VERSION "created by canmatrix"

NS_ :

BS_:

BU_: MD1_ECM ETC NODE_5 BSM_EBS RM_IRCS IC_Multic SGW BCM_NBM VCM NODE_31 ETS NODE_45 FCCU DICO NODE_72 FMReceiver SGW2 VCU ADCU MRGEN DTCO MBMS TPMS AI_CAID ELC ELC_R NODE_F7 BMS3 TUROLLA PCM SRR_Front_Left SRR_Rear_Right SRR_Front_Right SRR_Front SRR_Rear_Left ELFA3_S THERMOKING_M TMU_HP_Rr NODE_B1 NODE_B2 NODE_B3 NODE_B4 NODE_B5 NODE_B6 NODE_B7 NODE_B8 BMS2 NODE_B9 NODE_BA NODE_FC NODE_BB NODE_BC NODE_BE NODE_BD NODE_BF ACU NODE_C0 BMS1 NODE_C1 FCU NODE_C3 NODE_C4 NODE_EC NODE_C5 NODE_C6 NODE_C7 NODE_C8 VCU2 NODE_CA NODE_CB NODE_CD NODE_CE NODE_CF NODE_ED ST_ScanTool MASTER68_STD1 NODE_D1 NODE_F2 NODE_FD NODE_D2 MCSL NODE_EB NODE_D3 NODE_D4 NODE_D5 NODE_D6 VCCU NODE_D8 NODE_D9 NODE_F9 DiagTool NODE_DA NODE_DB NODE_DC NODE_DD NODE_DE NODE_DF NODE_E0 NODE_E1 NODE_E2 NODE_E9 NODE_E3 SAS NODE_FB NODE_F8 NODE_E6 ELFA3 NODE_F THERMOKING_D FMS MULTIC_S MULTIC_2 BMS4 BMS5 BMS6 BMS7 BMS8 BMS9 BMS10 BMS11 NODE_71

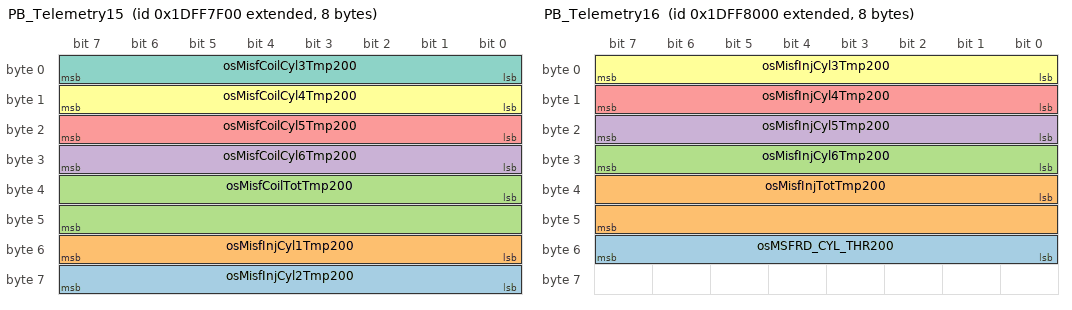
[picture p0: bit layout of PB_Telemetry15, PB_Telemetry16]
BO_ 2650767104 PB_Telemetry15: 8 MD1_ECM
 SG_ osMisfInjCyl2Tmp200 : 56|8@1+ (1,0) [0|255] "adm"  PCM
 SG_ osMisfInjCyl1Tmp200 : 48|8@1+ (1,0) [0|255] "adm"  PCM
 SG_ osMisfCoilTotTmp200 : 32|16@1+ (1,0) [0|65535] "adm"  PCM
 SG_ osMisfCoilCyl6Tmp200 : 24|8@1+ (1,0) [0|255] "adm"  PCM
 SG_ osMisfCoilCyl5Tmp200 : 16|8@1+ (1,0) [0|255] "adm"  PCM
 SG_ osMisfCoilCyl4Tmp200 : 8|8@1+ (1,0) [0|255] "adm"  PCM
 SG_ osMisfCoilCyl3Tmp200 : 0|8@1+ (1,0) [0|255] "adm"  PCM

BO_ 2650767360 PB_Telemetry16: 8 MD1_ECM
 SG_ osMSFRD_CYL_THR200 : 48|8@1+ (1,0) [0|100] "adm"  PCM
 SG_ osMisfInjTotTmp200 : 32|16@1+ (1,0) [0|65535] "adm"  PCM
 SG_ osMisfInjCyl6Tmp200 : 24|8@1+ (1,0) [0|255] "adm"  PCM
 SG_ osMisfInjCyl5Tmp200 : 16|8@1+ (1,0) [0|255] "adm"  PCM
 SG_ osMisfInjCyl4Tmp200 : 8|8@1+ (1,0) [0|255] "adm"  PCM
 SG_ osMisfInjCyl3Tmp200 : 0|8@1+ (1,0) [0|255] "adm"  PCM

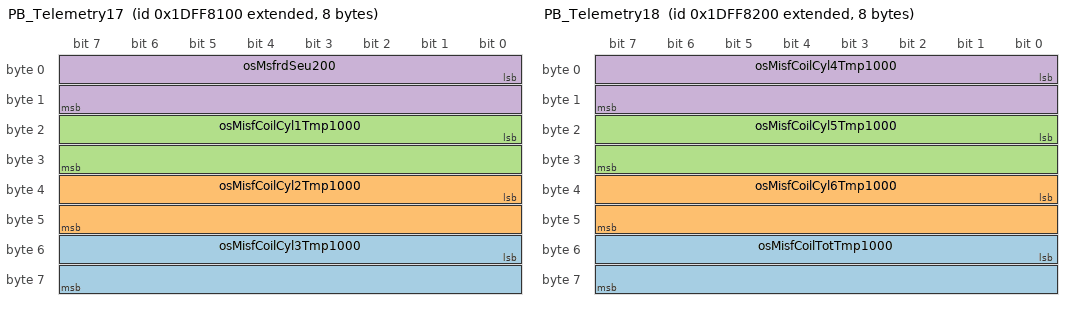
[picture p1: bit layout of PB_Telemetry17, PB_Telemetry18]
BO_ 2650767616 PB_Telemetry17: 8 MD1_ECM
 SG_ osMisfCoilCyl3Tmp1000 : 48|16@1+ (1,0) [0|65535] "adm"  PCM
 SG_ osMisfCoilCyl2Tmp1000 : 32|16@1+ (1,0) [0|65535] "adm"  PCM
 SG_ osMisfCoilCyl1Tmp1000 : 16|16@1+ (1,0) [0|65535] "adm"  PCM
 SG_ osMsfrdSeu200 : 0|16@1+ (1,0) [0|65535] "adm"  PCM

BO_ 2650767872 PB_Telemetry18: 8 MD1_ECM
 SG_ osMisfCoilTotTmp1000 : 48|16@1+ (1,0) [0|65535] "adm"  PCM
 SG_ osMisfCoilCyl6Tmp1000 : 32|16@1+ (1,0) [0|65535] "adm"  PCM
 SG_ osMisfCoilCyl5Tmp1000 : 16|16@1+ (1,0) [0|65535] "adm"  PCM
 SG_ osMisfCoilCyl4Tmp1000 : 0|16@1+ (1,0) [0|65535] "adm"  PCM

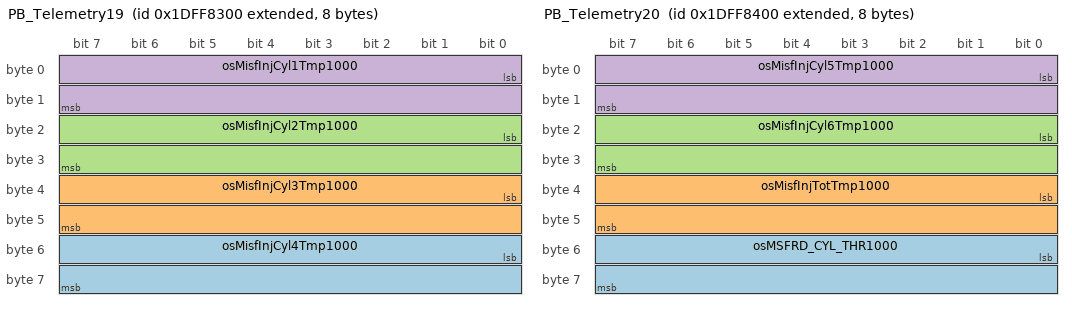
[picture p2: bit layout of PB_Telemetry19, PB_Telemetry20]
BO_ 2650768128 PB_Telemetry19: 8 MD1_ECM
 SG_ osMisfInjCyl4Tmp1000 : 48|16@1+ (1,0) [0|65535] "adm"  PCM
 SG_ osMisfInjCyl3Tmp1000 : 32|16@1+ (1,0) [0|65535] "adm"  PCM
 SG_ osMisfInjCyl2Tmp1000 : 16|16@1+ (1,0) [0|65535] "adm"  PCM
 SG_ osMisfInjCyl1Tmp1000 : 0|16@1+ (1,0) [0|65535] "adm"  PCM

BO_ 2650768384 PB_Telemetry20: 8 MD1_ECM
 SG_ osMSFRD_CYL_THR1000 : 48|16@1+ (1,0) [0|500] "adm"  PCM
 SG_ osMisfInjTotTmp1000 : 32|16@1+ (1,0) [0|65535] "adm"  PCM
 SG_ osMisfInjCyl6Tmp1000 : 16|16@1+ (1,0) [0|65535] "adm"  PCM
 SG_ osMisfInjCyl5Tmp1000 : 0|16@1+ (1,0) [0|65535] "adm"  PCM

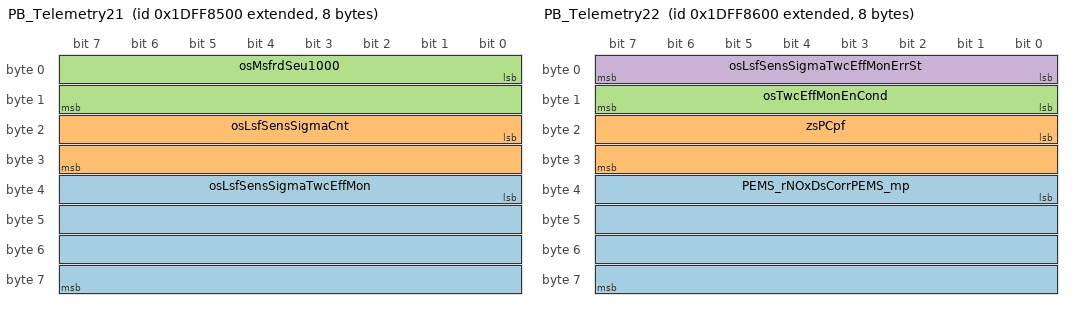
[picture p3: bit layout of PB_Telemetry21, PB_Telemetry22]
BO_ 2650768640 PB_Telemetry21: 8 MD1_ECM
 SG_ osLsfSensSigmaTwcEffMon : 32|32@1+ (2.3283064365387E-006,0) [0|10000] "mV"  PCM
 SG_ osLsfSensSigmaCnt : 16|16@1+ (1,0) [0|65535] "adm"  PCM
 SG_ osMsfrdSeu1000 : 0|16@1+ (1,0) [0|65535] "adm"  PCM

BO_ 2650768896 PB_Telemetry22: 8 MD1_ECM
 SG_ PEMS_rNOxDsCorrPEMS_mp : 32|32@1+ (1.52587890625E-005,0) [-32768|32767] "ppm"  PCM
 SG_ zsPCpf : 16|16@1+ (1,0) [-32768|32767] "hPa"  PCM
 SG_ osTwcEffMonEnCond : 8|8@1+ (1,0) [0|1] "adm"  PCM
 SG_ osLsfSensSigmaTwcEffMonErrSt : 0|8@1+ (1,0) [0|1] "adm"  PCM

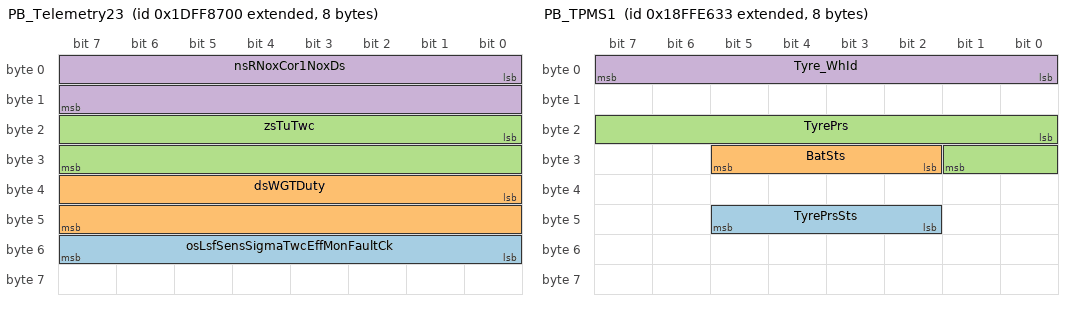
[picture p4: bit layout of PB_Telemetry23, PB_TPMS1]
BO_ 2650769152 PB_Telemetry23: 8 MD1_ECM
 SG_ osLsfSensSigmaTwcEffMonFaultCk : 48|8@1+ (1,0) [0|1] "adm"  PCM
 SG_ dsWGTDuty : 32|16@1+ (0.125,0) [0|8191.875] "%"  PCM
 SG_ zsTuTwc : 16|16@1+ (1,-40) [-40|65495] "°C"  PCM
 SG_ nsRNoxCor1NoxDs : 0|16@1+ (1,0) [-32768|32767] "ppm"  PCM

BO_ 2566907443 PB_TPMS1: 8 TPMS
 SG_ TyrePrsSts : 42|4@1+ (1,0) [0|15] ""  PCM
 SG_ BatSts : 26|4@1+ (10,0) [0|100] "%"  PCM
 SG_ TyrePrs : 16|10@1+ (2,0) [0|2036] "kPa"  PCM
 SG_ Tyre_WhId : 0|8@1+ (1,0) [0|255] ""  PCM

BO_ 2566867182 PB_VDO1: 32 DTCO
 SG_ SignifTimeOverlapInUsedDrivActiv : 254|2@1+ (1,0) [0|3] ""  PCM
 SG_ MultiManningCurShift : 252|2@1+ (1,0) [0|3] ""  PCM
 SG_ WeekRestPerCalcEna : 250|2@1+ (1,0) [0|3] ""  PCM
 SG_ NoSuffDataOnTheDrivCard : 248|2@1+ (1,0) [0|3] ""  PCM
 SG_ UnknownPer : 246|2@1+ (1,0) [0|3] ""  PCM
 SG_ RemReducDayRestPer : 243|3@1+ (1,0) [0|7] ""  PCM
 SG_ Rem10HDrivTimes : 240|3@1+ (1,0) [0|7] ""  PCM
 SG_ OpenCompIn2ndWeekBefLast : 224|16@1+ (1,0) [0|64255] "min"  PCM
 SG_ OpenCompInWeekBefLast : 208|16@1+ (1,0) [0|64255] "min"  PCM
 SG_ OpenCompInLw : 192|16@1+ (1,0) [0|64255] "min"  PCM
 SG_ DurOfNwlyRestPer : 176|16@1+ (1,0) [0|64255] "min"  PCM
 SG_ RemTimeTillNwlyRestPer : 160|16@1+ (1,0) [0|64255] "min"  PCM
 SG_ RemDrivTimeOfCw : 144|16@1+ (1,0) [0|64255] "min"  PCM
 SG_ DurOfNextDayRestPer : 128|16@1+ (1,0) [0|64255] "min"  PCM
 SG_ RemTimeTillNextDayRestPer : 112|16@1+ (1,0) [0|64255] "min"  PCM
 SG_ RemCurDayDrivTime : 96|16@1+ (1,0) [0|64255] "min"  PCM
 SG_ DurOfNextDrivPer : 80|16@1+ (1,0) [0|64255] "min"  PCM
 SG_ TimeBefStartOfNextDrivPer : 64|16@1+ (1,0) [0|64255] "min"  PCM
 SG_ RemDurOfCurBreak_Rest : 48|16@1+ (1,0) [0|64255] "min"  PCM
 SG_ DurOfNextRest_Break : 32|16@1+ (1,0) [0|64255] "min"  PCM
 SG_ RemTimeTillNextRest_Break : 16|16@1+ (1,0) [0|64255] "min"  PCM
 SG_ RemCurDrivTime : 0|16@1+ (1,0) [0|64255] "min"  PCM

BO_ 2566867438 PB_VDO1ex: 16 DTCO
 SG_ NextBreak_RestExByAComp : 22|2@1+ (1,0) [0|3] ""  PCM
 SG_ TypeOfNextBreak_Rest : 16|6@1+ (1,0) [0|63] ""  PCM
 SG_ RemDrivTimeTillNwlyRestPer : 0|16@1+ (1,0) [0|64255] "min"  PCM

BO_ 2566867694 PB_VDO2: 32 DTCO
 SG_ CwWorkTime : 144|16@1+ (1,0) [0|64255] "min"  PCM
 SG_ CurDayWorkTime : 128|16@1+ (1,0) [0|64255] "min"  PCM
 SG_ LwAssignReducWeekRestPer : 124|4@1+ (1,0) [0|15] ""  PCM
 SG_ LwAssignRegWeekRestPer : 120|4@1+ (1,0) [0|15] ""  PCM
 SG_ CwNumOfAssignReducWeekRestPer : 116|4@1+ (1,0) [0|15] ""  PCM
 SG_ CwNumOfAssignRegWeekRestPer : 112|4@1+ (1,0) [0|15] ""  PCM
 SG_ DurOfCurRestPer : 96|16@1+ (1,0) [0|64255] "min"  PCM
 SG_ DurOfCurRest : 80|16@1+ (1,0) [0|64255] "min"  PCM
 SG_ CumulBreakTime : 64|16@1+ (1,0) [0|64255] "min"  PCM
 SG_ WeekDrivTime : 48|16@1+ (1,0) [0|64255] "min"  PCM
 SG_ TwoWeeksDrivTime : 32|16@1+ (1,0) [0|64255] "min"  PCM
 SG_ DayDrivTime_FF4AEE : 16|16@1+ (1,0) [0|64255] "min"  PCM
 SG_ ContDrivTime : 0|16@1+ (1,0) [0|64255] "min"  PCM

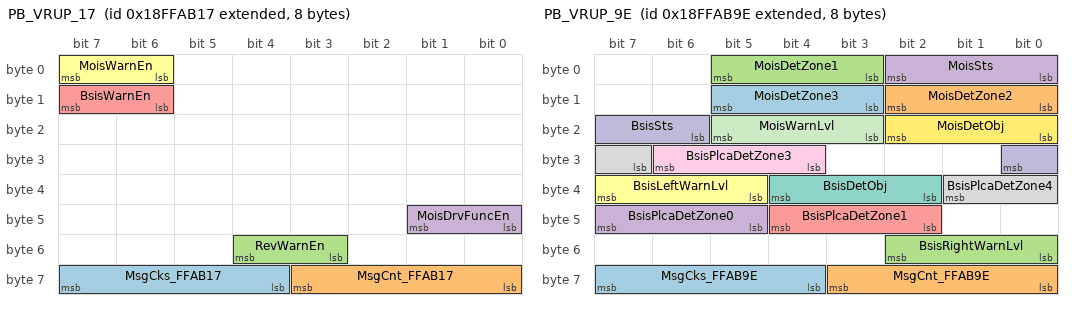
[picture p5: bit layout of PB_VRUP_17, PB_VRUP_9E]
BO_ 2566892311 PB_VRUP_17: 8 IC_Multic
 SG_ MsgCks_FFAB17 : 60|4@1+ (1,0) [0|15] "count"  PCM
 SG_ MsgCnt_FFAB17 : 56|4@1+ (1,0) [0|15] "count"  PCM
 SG_ RevWarnEn : 51|2@1+ (1,0) [0|3] ""  PCM
 SG_ MoisDrvFuncEn : 40|2@1+ (1,0) [0|3] ""  PCM
 SG_ BsisWarnEn : 14|2@1+ (1,0) [0|3] ""  PCM
 SG_ MoisWarnEn : 6|2@1+ (1,0) [0|3] ""  PCM

BO_ 2566892446 PB_VRUP_9E: 8 ADCU
 SG_ MsgCks_FFAB9E : 60|4@1+ (1,0) [0|15] "count"  PCM
 SG_ MsgCnt_FFAB9E : 56|4@1+ (1,0) [0|15] "count"  PCM
 SG_ BsisRightWarnLvl : 48|3@1+ (1,0) [0|7] ""  PCM
 SG_ BsisPlcaDetZone0 : 45|3@1+ (1,0) [0|7] ""  PCM
 SG_ BsisPlcaDetZone1 : 42|3@1+ (1,0) [0|7] ""  PCM
 SG_ BsisLeftWarnLvl : 37|3@1+ (1,0) [0|7] ""  PCM
 SG_ BsisDetObj : 34|3@1+ (1,0) [0|7] ""  PCM
 SG_ BsisPlcaDetZone4 : 31|3@1+ (1,0) [0|7] ""  PCM
 SG_ BsisPlcaDetZone3 : 28|3@1+ (1,0) [0|7] ""  PCM
 SG_ BsisSts : 22|3@1+ (1,0) [0|3] ""  PCM
 SG_ MoisWarnLvl : 19|3@1+ (1,0) [0|7] ""  PCM
 SG_ MoisDetObj : 16|3@1+ (1,0) [0|7] ""  PCM
 SG_ MoisDetZone3 : 11|3@1+ (1,0) [0|7] ""  PCM
 SG_ MoisDetZone2 : 8|3@1+ (1,0) [0|7] ""  PCM
 SG_ MoisDetZone1 : 3|3@1+ (1,0) [0|7] ""  PCM
 SG_ MoisSts : 0|3@1+ (1,0) [0|7] ""  PCM

BO_ 2631855639 RESET_17_EE: 8 IC_Multic
 SG_ TripGrp1 : 0|2@1+ (1,0) [0|3] ""  PCM,DTCO

BO_ 2566847248 RF: 8 RM_IRCS
 SG_ HydrRetOilTemp : 8|8@1+ (1,-40) [-40|210] "°C"  PCM

BO_ 2565537539 RQST_03: 3 ETC
 SG_ PgnRqst : 0|24@1+ (1,0) [0|16777215] "PGN"  PCM

BO_ 2565485386 RQST_4A_33: 3 PCM
 SG_ PgnRqst_EA334A : 0|24@1+ (1,0) [0|16777215] "PGN"  TPMS

BO_ 2565533258 RQST_4A_EE: 3 PCM
 SG_ PgnRqst_EAEE4A : 0|24@1+ (1,0) [0|16777215] "PGN"  DTCO

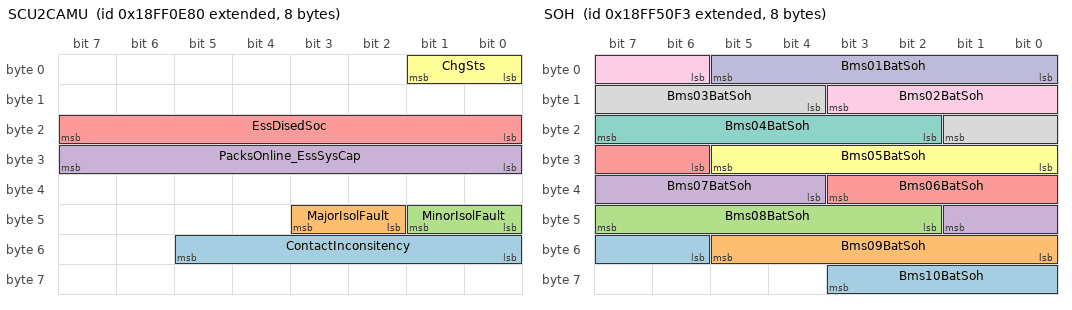
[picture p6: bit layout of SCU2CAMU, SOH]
BO_ 2566852224 SCU2CAMU: 8 VCU
 SG_ ContactInconsitency : 48|6@1+ (1,0) [0|63] ""  PCM
 SG_ MajorIsolFault : 42|2@1+ (1,0) [0|3] ""  PCM
 SG_ MinorIsolFault : 40|2@1+ (1,0) [0|3] ""  PCM
 SG_ PacksOnline_EssSysCap : 24|8@1+ (1,0) [0|250] "packs"  PCM
 SG_ EssDisedSoc : 16|8@1+ (0.4,0) [0|100] "%"  PCM
 SG_ ChgSts : 0|2@1+ (1,0) [0|3] ""  PCM

BO_ 2566838813 SOFT_1D: 202 SGW
 SG_ SwIdField5 : 40|8@1+ (1,0) [0|255] "ASCII"  PCM
 SG_ SwIdField4 : 32|8@1+ (1,0) [0|255] "ASCII"  PCM
 SG_ SwIdField3 : 24|8@1+ (1,0) [0|255] "ASCII"  PCM
 SG_ SwIdField2 : 16|8@1+ (1,0) [0|255] "ASCII"  PCM
 SG_ SwIdField1 : 8|8@1+ (1,0) [0|255] "ASCII"  PCM
 SG_ NumOfSwIdFields : 0|8@1+ (1,0) [0|250] "step"  PCM

BO_ 2566838878 SOFT_5E: 202 AI_CAID
 SG_ SwId : 8|8@1+ (1,0) [0|255] "ASCII"  PCM
 SG_ NumOfSwIdFields_FEDA5E : 0|8@1+ (1,0) [0|250] "step"  PCM

BO_ 2566869235 SOH: 8 MBMS
 SG_ Bms10BatSoh : 54|6@1+ (1,39) [39|100] "%"  PCM
 SG_ Bms09BatSoh : 48|6@1+ (1,39) [39|100] "%"  PCM
 SG_ Bms08BatSoh : 42|6@1+ (1,39) [39|100] "%"  PCM
 SG_ Bms07BatSoh : 36|6@1+ (1,39) [39|100] "%"  PCM
 SG_ Bms06BatSoh : 30|6@1+ (1,39) [39|100] "%"  PCM
 SG_ Bms05BatSoh : 24|6@1+ (1,39) [39|100] "%"  PCM
 SG_ Bms04BatSoh : 18|6@1+ (1,39) [39|100] "%"  PCM
 SG_ Bms03BatSoh : 12|6@1+ (1,39) [39|100] "%"  PCM
 SG_ Bms02BatSoh : 6|6@1+ (1,39) [39|100] "%"  PCM
 SG_ Bms01BatSoh : 0|6@1+ (1,39) [39|100] "%"  PCM

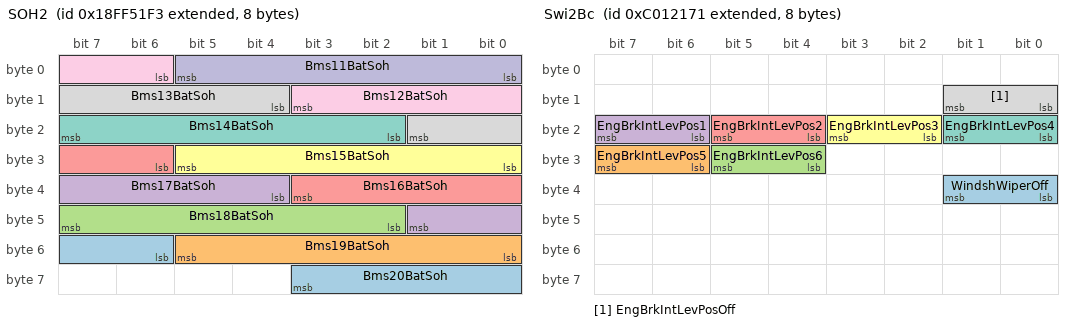
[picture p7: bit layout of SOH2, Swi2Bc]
BO_ 2566869491 SOH2: 8 MBMS
 SG_ Bms20BatSoh : 54|6@1+ (1,39) [39|100] "%"  PCM
 SG_ Bms19BatSoh : 48|6@1+ (1,39) [39|100] "%"  PCM
 SG_ Bms18BatSoh : 42|6@1+ (1,39) [39|100] "%"  PCM
 SG_ Bms17BatSoh : 36|6@1+ (1,39) [39|100] "%"  PCM
 SG_ Bms16BatSoh : 30|6@1+ (1,39) [39|100] "%"  PCM
 SG_ Bms15BatSoh : 24|6@1+ (1,39) [39|100] "%"  PCM
 SG_ Bms14BatSoh : 18|6@1+ (1,39) [39|100] "%"  PCM
 SG_ Bms13BatSoh : 12|6@1+ (1,39) [39|100] "%"  PCM
 SG_ Bms12BatSoh : 6|6@1+ (1,39) [39|100] "%"  PCM
 SG_ Bms11BatSoh : 0|6@1+ (1,39) [39|100] "%"  PCM

BO_ 2566884079 StTU1: 8 ELFA3
 SG_ TempInvHeatsink : 24|8@1+ (1,-40) [-40|210] "°C"  PCM

BO_ 2348884337 Swi2Bc: 8 NODE_71
 SG_ WindshWiperOff : 32|2@1+ (1,0) [0|3] ""  PCM,BCM_NBM
 SG_ EngBrkIntLevPos5 : 30|2@1+ (1,0) [0|3] ""  PCM,BCM_NBM
 SG_ EngBrkIntLevPos6 : 28|2@1+ (1,0) [0|3] ""  PCM,BCM_NBM
 SG_ EngBrkIntLevPos1 : 22|2@1+ (1,0) [0|3] ""  PCM,BCM_NBM
 SG_ EngBrkIntLevPos2 : 20|2@1+ (1,0) [0|3] ""  PCM,BCM_NBM
 SG_ EngBrkIntLevPos3 : 18|2@1+ (1,0) [0|3] ""  PCM,BCM_NBM
 SG_ EngBrkIntLevPos4 : 16|2@1+ (1,0) [0|3] ""  PCM,BCM_NBM
 SG_ EngBrkIntLevPosOff : 8|2@1+ (1,0) [0|3] ""  PCM,BCM_NBM

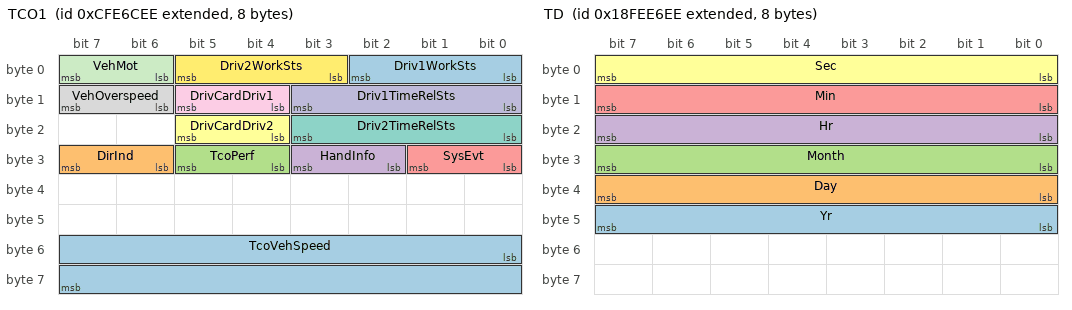
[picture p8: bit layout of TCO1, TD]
BO_ 2365484270 TCO1: 8 DTCO
 SG_ TcoVehSpeed : 48|16@1+ (0.00390625,0) [0|250.996] "km/h"  PCM
 SG_ DirInd : 30|2@1+ (1,0) [0|3] ""  PCM
 SG_ TcoPerf : 28|2@1+ (1,0) [0|3] ""  PCM
 SG_ HandInfo : 26|2@1+ (1,0) [0|3] ""  PCM
 SG_ SysEvt : 24|2@1+ (1,0) [0|3] ""  PCM
 SG_ DrivCardDriv2 : 20|2@1+ (1,0) [0|3] ""  PCM
 SG_ Driv2TimeRelSts : 16|4@1+ (1,0) [0|15] ""  PCM
 SG_ VehOverspeed : 14|2@1+ (1,0) [0|3] ""  PCM
 SG_ DrivCardDriv1 : 12|2@1+ (1,0) [0|3] ""  PCM
 SG_ Driv1TimeRelSts : 8|4@1+ (1,0) [0|15] ""  PCM
 SG_ VehMot : 6|2@1+ (1,0) [0|3] ""  PCM
 SG_ Driv2WorkSts : 3|3@1+ (1,0) [0|7] ""  PCM
 SG_ Driv1WorkSts : 0|3@1+ (1,0) [0|7] ""  PCM

BO_ 2566842094 TD: 8 DTCO
 SG_ Yr : 40|8@1+ (1,1985) [1985|2235] "year"  PCM
 SG_ Day : 32|8@1+ (0.25,0) [0|62.5] "day"  PCM
 SG_ Month : 24|8@1+ (1,0) [0|250] "month"  PCM
 SG_ Hr : 16|8@1+ (1,0) [0|250] "h"  PCM
 SG_ Min : 8|8@1+ (1,0) [0|250] "min"  PCM
 SG_ Sec : 0|8@1+ (0.25,0) [0|62.5] "s"  PCM

BO_ 2566854213 Telemat_1: 8 NODE_45
 SG_ ApuRedWarn : 63|1@1+ (1,0) [0|1] ""  PCM
 SG_ MildhybridStop_StartDeact : 62|1@1+ (1,0) [0|1] ""  PCM
 SG_ ApuOrangeWarn_ElectrovalvesApuDe : 61|1@1+ (1,0) [0|1] ""  PCM
 SG_ OilLevPwrSteerPumpDef : 60|1@1+ (1,0) [0|1] ""  PCM
 SG_ OilSepFault : 59|1@1+ (1,0) [0|1] ""  PCM
 SG_ GasFailElectrovalveN10 : 58|1@1+ (1,0) [0|1] ""  PCM
 SG_ GasFailElectrovalveN9 : 57|1@1+ (1,0) [0|1] ""  PCM
 SG_ GasFailElectrovalveN8 : 56|1@1+ (1,0) [0|1] ""  PCM
 SG_ GasFailElectrovalveN7 : 55|1@1+ (1,0) [0|1] ""  PCM
 SG_ GasFailElectrovalveN6 : 54|1@1+ (1,0) [0|1] ""  PCM
 SG_ GasFailElectrovalveN5 : 53|1@1+ (1,0) [0|1] ""  PCM
 SG_ GasFailElectrovalveN4 : 52|1@1+ (1,0) [0|1] ""  PCM
 SG_ GasFailElectrovalveN3 : 51|1@1+ (1,0) [0|1] ""  PCM
 SG_ GasFailElectrovalveN2 : 50|1@1+ (1,0) [0|1] ""  PCM
 SG_ GasFailElectrovalveN1 : 49|1@1+ (1,0) [0|1] ""  PCM
 SG_ ElectrovalveGasFail : 48|1@1+ (1,0) [0|1] ""  PCM
 SG_ GasTempSensFail : 47|1@1+ (1,0) [0|1] ""  PCM
 SG_ GasRefuelingGateOpen : 46|1@1+ (1,0) [0|1] ""  PCM
 SG_ GasTempTooHigh : 45|1@1+ (1,0) [0|1] ""  PCM
 SG_ AutoOilDef : 43|1@1+ (1,0) [0|1] ""  PCM
 SG_ DefPompeDosMod : 42|1@1+ (1,0) [0|1] ""  PCM
 SG_ AcComprSts : 41|1@1+ (1,0) [0|1] ""  PCM
 SG_ AcFault : 40|1@1+ (1,0) [0|1] ""  PCM
 SG_ AcOn : 39|1@1+ (1,0) [0|1] ""  PCM
 SG_ DrivAcFault : 38|1@1+ (1,0) [0|1] ""  PCM
 SG_ DrivAcOn : 37|1@1+ (1,0) [0|1] ""  PCM
 SG_ FuelFiltClogDef : 36|1@1+ (1,0) [0|1] ""  PCM
 SG_ EngOilLowLev : 35|1@1+ (1,0) [0|1] ""  PCM
 SG_ EngAirFiltClogDef : 34|1@1+ (1,0) [0|1] ""  PCM
 SG_ LowLevEngCoolRefr : 33|1@1+ (1,0) [0|1] ""  PCM
 SG_ VehSpeedSigDef : 32|1@1+ (1,0) [0|1] ""  PCM
 SG_ CaidLeadenBtnSts : 31|1@1+ (1,0) [0|1] ""  PCM
 SG_ DrlLightDef : 30|1@1+ (1,0) [0|1] ""  PCM
 SG_ PavillonRightTurnLightDef : 29|1@1+ (1,0) [0|1] ""  PCM
 SG_ PavillonLeftTurnLightDef : 28|1@1+ (1,0) [0|1] ""  PCM
 SG_ LatRightTurnLightDef : 27|1@1+ (1,0) [0|1] ""  PCM
 SG_ LatLeftTurnLightDef : 26|1@1+ (1,0) [0|1] ""  PCM
 SG_ RearRightTurnLightDef : 25|1@1+ (1,0) [0|1] ""  PCM
 SG_ RearLeftTurnLightDef : 24|1@1+ (1,0) [0|1] ""  PCM
 SG_ RearFogLightDef : 23|1@1+ (1,0) [0|1] ""  PCM
 SG_ FaRFogLightDef : 22|1@1+ (1,0) [0|1] ""  PCM
 SG_ FaLFogLightDef : 21|1@1+ (1,0) [0|1] ""  PCM
 SG_ RearPosLightDef : 20|1@1+ (1,0) [0|1] ""  PCM
 SG_ RearPavillonPosLightDef : 19|1@1+ (1,0) [0|1] ""  PCM
 SG_ FrontRightTurnLightDef : 18|1@1+ (1,0) [0|1] ""  PCM
 SG_ FrontLeftTurnLightDef : 17|1@1+ (1,0) [0|1] ""  PCM
 SG_ RightLowBeamLightDef : 16|1@1+ (1,0) [0|1] ""  PCM
 SG_ LeftLowBeamLightDef : 15|1@1+ (1,0) [0|1] ""  PCM
 SG_ RightHighBeamLightDef : 14|1@1+ (1,0) [0|1] ""  PCM
 SG_ LeftHighBeamLightDef : 13|1@1+ (1,0) [0|1] ""  PCM
 SG_ RevLightDef : 12|1@1+ (1,0) [0|1] ""  PCM
 SG_ StopLightDef : 11|1@1+ (1,0) [0|1] ""  PCM
 SG_ FireOngoing : 10|1@1+ (1,0) [0|1] ""  PCM
 SG_ Overheating_RiskOfFire : 9|1@1+ (1,0) [0|1] ""  PCM
 SG_ FireExtinctionFaulty : 8|1@1+ (1,0) [0|1] ""  PCM
 SG_ AirPrsMidBrkCircDef : 7|1@1+ (1,0) [0|1] ""  PCM
 SG_ AirPrsServitudeCircDef : 6|1@1+ (1,0) [0|1] ""  PCM
 SG_ AirPrsParkBrkCircDef : 5|1@1+ (1,0) [0|1] ""  PCM
 SG_ AirPrsFrontBrkCircDef : 4|1@1+ (1,0) [0|1] ""  PCM
 SG_ AirPrsRearBrkCircDef : 3|1@1+ (1,0) [0|1] ""  PCM
 SG_ Ramp_Whchair_LiftFail : 2|1@1+ (1,0) [0|1] ""  PCM
 SG_ FailOnRampSensitiveEdge_Step : 1|1@1+ (1,0) [0|1] ""  PCM
 SG_ DoorsSecurModeDeactivated : 0|1@1+ (1,0) [0|1] ""  PCM

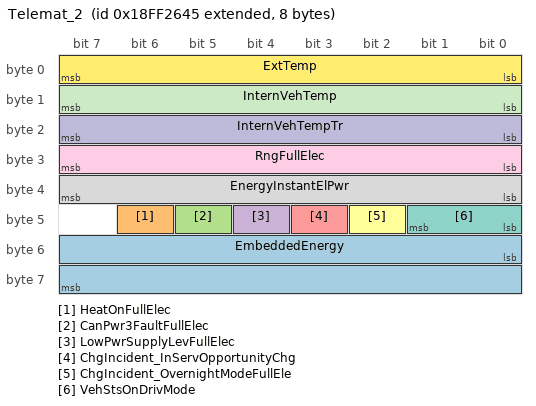
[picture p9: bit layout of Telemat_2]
BO_ 2566858309 Telemat_2: 8 NODE_45
 SG_ EmbeddedEnergy : 48|16@1+ (1,0) [0|385] "kwh"  PCM
 SG_ HeatOnFullElec : 46|1@1+ (1,0) [0|1] ""  PCM
 SG_ CanPwr3FaultFullElec : 45|1@1+ (1,0) [0|1] ""  PCM
 SG_ LowPwrSupplyLevFullElec : 44|1@1+ (1,0) [0|1] ""  PCM
 SG_ ChgIncident_InServOpportunityChg : 43|1@1+ (1,0) [0|1] ""  PCM
 SG_ ChgIncident_OvernightModeFullEle : 42|1@1+ (1,0) [0|1] ""  PCM
 SG_ VehStsOnDrivMode : 40|2@1+ (1,0) [0|3] ""  PCM
 SG_ EnergyInstantElPwr : 32|8@1+ (2,-250) [-250|250] "kw"  PCM
 SG_ RngFullElec : 24|8@1+ (2,0) [0|500] "km"  PCM
 SG_ InternVehTempTr : 16|8@1+ (1,-40) [-40|210] "°C"  PCM
 SG_ InternVehTemp : 8|8@1+ (1,-40) [-40|210] "°C"  PCM
 SG_ ExtTemp : 0|8@1+ (1,-40) [-40|210] "°C"  PCM

CM_ BO_ 2650767104 "- Telemetry purpose. NEF CNG only";
CM_ BO_ 2650767360 "- Telemetry purpose. NEF CNG only";
CM_ BO_ 2650767616 "- Telemetry purpose. NEF CNG only";
CM_ BO_ 2650767872 "- Telemetry purpose. NEF CNG only";
CM_ BO_ 2650768128 "- Telemetry purpose. NEF CNG only";
CM_ BO_ 2650768384 "- Telemetry purpose. NEF CNG only";
CM_ BO_ 2650768640 "- Telemetry purpose. NEF CNG only";
CM_ BO_ 2650768896 "- Telemetry purpose. NEF CNG only";
CM_ BO_ 2650769152 "- Telemetry purpose. NEF CNG only";
CM_ SG_ 2566907443 Tyre_WhId "- The TPMS Tyre location parameter will follow that which is defined by ISO 11992 defined i.e. 0x17, 0x19, 0x27, 0x29, 0x36, etc.";
CM_ BO_ 2566867182 "- PGN=0xFF00 (65280) as Conti default, 0xFF48 (65352) applied by Iveco.
-  Transmission rate: 60 [s] or at change
-  Update filled in acc with DTCO4.1 (New file)";
CM_ BO_ 2566867438 "- PGN=0xFF01 (65281) as Conti default, 0xFF49 (65353) applied by Iveco
-  Update filled in acc with DTCO4.1 (New file)";
CM_ BO_ 2566867694 "- PGN=0xFF02 (65282) as Conti default, 0xFF4A (65354) applied by Iveco
-  Update filled in acc with DTCO4.1 (New file)";
CM_ SG_ 2566892311 RevWarnEn "- Z. Lin: Check internally - Used for SRR as REV sensor";
CM_ BO_ 2566892446 "- IC1.A.IC..25..MCS: routed from ADCU";
CM_ SG_ 2566892446 BsisRightWarnLvl "- DC4.xx.MCSL..GSRC..MCS: routed to Right MCS";
CM_ BO_ 2631855639 "- Repetition rate: 1000 ms on request (ms). Timeout (ms): 1000 ms.
-  Transmission rate: 1000/AsNeeded.";
CM_ SG_ 2631855639 TripGrp1 "- bits 1, 0: Trip Group 1 - Resets the High Resolution Trip Distance, see [1_CAN_3360].
-  bits 3, 2: Trip Group 2 - Proprietary Resets the Driving, Work and Availability counters, see [1_CAN_3361].
-  bits 7 to 4: ‘1111’B. -Don’t care, any value will be accepted.";
CM_ BO_ 2565537539 "- Any Source Address and ECU specific or Global Destination Addresses shall be accepted (CNHI Std. 18-2253).
-  Request PGN Transmission to ALL
-  Requested after LOG P60 (on CAN Telem, Tacho, FMS).";
CM_ SG_ 2565537539 PgnRqst "- Value Table filled with the most commonly used PGNs in Iveco applications, ECU implementation may differ";
CM_ BO_ 2565485386 "- CUC.C.PCM..3..TELEM: Filled in acordind with TPMS request";
CM_ BO_ 2565533258 "- Any Source Address and ECU specific or Global Destination Addresses shall be accepted (CNHI Std. 18-2253)
-  Used by X-Slot to request VIN and Driver's ID.";
CM_ BO_ 2566852224 "- Now 100ms, previously 1000ms, 100ms on change
- OVG.Mtx.MPPxPT.FE2.25..FMSi: Output message managed via PNG with SA 0xFF0E80";
CM_ SG_ 2566852224 ContactInconsitency "- 000000: no error. 00xxxx: Error status. 110000: error. 111111: not available
-  00000x: Bit 1 for Contactor Q1 . 0000x0: Bit 2 for Contactor Q2. 000x00: Bit 3 for Contactor Q4. 00x000: Bit 4 for Contactor Q5
-  X = 0 no error. X = 1 error";
CM_ BO_ 2566838813 "- Multipacket message handled by SAE Transport Protocol (J1939/21, par 5.10, Multipacket Broadcast with TP.CM/BAM, TP.DT)
-  Transport Protocol with Control Flow  (RTS, CTS, EndOfMsgAck, Conn_Abort) shall be also supported by the receiver if the multipacket message has been solicited by a Destination Specific Request
-  Variable Message Length, maximum value used for dbc generation";
CM_ SG_ 2566838813 SwIdField5 "- 8+1 characters maximum, CNHI Warning and Fault Database Version (CNHI Std. 18-2253)
-  Variable signal length, 8 bits used for dbc generation only";
CM_ SG_ 2566838813 SwIdField4 "- 15+1 characters maximum. Calibration Identification Number (CNHI Std. 18-2253)
-  Variable signal length, 8 bits used for dbc generation only";
CM_ SG_ 2566838813 SwIdField3 "- 8+1 characters (yyyymmdd). Manufacturer SW Issue Date, optional if Software Version is available (CNHI Std. 18-2253)
-  Variable signal length, 8 bits used for dbc generation only";
CM_ SG_ 2566838813 SwIdField2 "- 15+1 characters maximum. Manufacturer SW Version, Optional if Software Issue Date is available (CNHI Std. 18-2253)
-  Variable signal length, 8 bits used for dbc generation only";
CM_ SG_ 2566838813 SwIdField1 "- Variable signal length, 8 bits used for dbc generation only";
CM_ SG_ 2566838813 NumOfSwIdFields "- 5 (IVECO Std. 18-2253)";
CM_ SG_ 2566838878 SwId "- 15+1 characters maximum. Manufacturer SW P/N (CNHI Std. 18-2253)
-  Variable signal length, 8 bits used for dbc generation only";
CM_ SG_ 2566838878 NumOfSwIdFields_FEDA5E "- 5 (IVECO Std. 18-2253)";
CM_ BO_ 2566869235 "- OVG.Mtx.FMS.4.24.Generic.FMSi: predisposal. Full Elec only";
CM_ SG_ 2566869235 Bms10BatSoh "- 1% resolution / range [39-100%] 000000 = 39%. 111101 = 100%
-  111110 = Error (Error on SOH measurment). 111111 = Not Available";
CM_ SG_ 2566869235 Bms09BatSoh "- 1% resolution / range [39-100%] 000000 = 39%. 111101 = 100%
-  111110 = Error (Error on SOH measurment). 111111 = Not Available";
CM_ SG_ 2566869235 Bms08BatSoh "- 1% resolution / range [39-100%] 000000 = 39%. 111101 = 100%
-  111110 = Error (Error on SOH measurment). 111111 = Not Available";
CM_ SG_ 2566869235 Bms07BatSoh "- 1% resolution / range [39-100%] 000000 = 39%. 111101 = 100%
-  111110 = Error (Error on SOH measurment). 111111 = Not Available";
CM_ SG_ 2566869235 Bms06BatSoh "- 1% resolution / range [39-100%] 000000 = 39%. 111101 = 100%
-  111110 = Error (Error on SOH measurment). 111111 = Not Available";
CM_ SG_ 2566869235 Bms05BatSoh "- 1% resolution / range [39-100%] 000000 = 39%. 111101 = 100%
-  111110 = Error (Error on SOH measurment). 111111 = Not Available";
CM_ SG_ 2566869235 Bms04BatSoh "- 1% resolution / range [39-100%] 000000 = 39%. 111101 = 100%
-  111110 = Error (Error on SOH measurment). 111111 = Not Available";
CM_ SG_ 2566869235 Bms03BatSoh "- 1% resolution / range [39-100%] 000000 = 39%. 111101 = 100%
-  111110 = Error (Error on SOH measurment). 111111 = Not Available";
CM_ SG_ 2566869235 Bms02BatSoh "- 1% resolution / range [39-100%] 000000 = 39%. 111101 = 100%
-  111110 = Error (Error on SOH measurment). 111111 = Not Available";
CM_ SG_ 2566869235 Bms01BatSoh "- 1% resolution / range [39-100%] 000000 = 39%. 111101 = 100%
-  111110 = Error (Error on SOH measurment). 111111 = Not Available";
CM_ BO_ 2566869491 "- Predisposal for ZEN35 battery pack. Full Elec only";
CM_ SG_ 2566869491 Bms20BatSoh "- 1% resolution / range [39-100%] 000000 = 39%. 111101 = 100%
-  111110 = Error (Error on SOH measurment). 111111 = Not Available";
CM_ SG_ 2566869491 Bms19BatSoh "- 1% resolution / range [39-100%] 000000 = 39%. 111101 = 100%
-  111110 = Error (Error on SOH measurment). 111111 = Not Available";
CM_ SG_ 2566869491 Bms18BatSoh "- 1% resolution / range [39-100%] 000000 = 39%. 111101 = 100%
-  111110 = Error (Error on SOH measurment). 111111 = Not Available";
CM_ SG_ 2566869491 Bms17BatSoh "- 1% resolution / range [39-100%] 000000 = 39%. 111101 = 100%
-  111110 = Error (Error on SOH measurment). 111111 = Not Available";
CM_ SG_ 2566869491 Bms16BatSoh "- 1% resolution / range [39-100%] 000000 = 39%. 111101 = 100%
-  111110 = Error (Error on SOH measurment). 111111 = Not Available";
CM_ SG_ 2566869491 Bms15BatSoh "- 1% resolution / range [39-100%] 000000 = 39%. 111101 = 100%
-  111110 = Error (Error on SOH measurment). 111111 = Not Available";
CM_ SG_ 2566869491 Bms14BatSoh "- 1% resolution / range [39-100%] 000000 = 39%. 111101 = 100%
-  111110 = Error (Error on SOH measurment). 111111 = Not Available";
CM_ SG_ 2566869491 Bms13BatSoh "- 1% resolution / range [39-100%] 000000 = 39%. 111101 = 100%
-  111110 = Error (Error on SOH measurment). 111111 = Not Available";
CM_ SG_ 2566869491 Bms12BatSoh "- 1% resolution / range [39-100%] 000000 = 39%. 111101 = 100%
-  111110 = Error (Error on SOH measurment). 111111 = Not Available";
CM_ SG_ 2566869491 Bms11BatSoh "- 1% resolution / range [39-100%] 000000 = 39%. 111101 = 100%
-  111110 = Error (Error on SOH measurment). 111111 = Not Available";
CM_ BO_ 2566884079 "- Specific to Siemens Full Elec vehicles. PCM Fill (in yellow) in acoording with VCU file.";
CM_ BO_ 2348884337 "- Exception - Should be J1939 p2p
-  To be confirmed if available on CW FE too. Message present on LOG VM81.";
CM_ BO_ 2365484270 "- If without Tacho then Multic S is Tx. else MulticS is Rx.
-  In some applications Rate transmission can be 20 ms.
- OVG.Mtx.FMS.4.24.Generic.FMSi: If option.";
CM_ BO_ 2566842094 "- MulticS/MulticII: Is sender ''Tx'' if P_TCO=0
-  SAE Trans.Rate=On Request
- OVG.Mtx.FMS.4.24.Generic.FMSi: If option.";
CM_ SG_ 2566842094 Yr "- SAE J1939/73 Freeze Frame parameter";
CM_ SG_ 2566842094 Day "- SAE J1939/73 Freeze Frame parameter";
CM_ SG_ 2566842094 Month "- SAE J1939/73 Freeze Frame parameter";
CM_ SG_ 2566842094 Hr "- SAE J1939/73 Freeze Frame parameter";
CM_ SG_ 2566842094 Min "- SAE J1939/73 Freeze Frame parameter";
CM_ SG_ 2566842094 Sec "- SAE J1939/73 Freeze Frame parameter";
CM_ BO_ 2566858309 "- Full Elec only.";
CM_ SG_ 2566858309 ChgIncident_InServOpportunityChg "- CUC.C.PCM..3..TELEM: Predisposition. Not yet implemented on MUX software";
CM_ SG_ 2566858309 ChgIncident_OvernightModeFullEle "- CUC.C.PCM..3..TELEM: Predisposition. Not yet implemented on MUX software";
BA_DEF_ BO_  "CI_MsgDefinition" STRING ;
BA_DEF_ BO_  "CI_MsgId" INT 0 2147483647;
BA_DEF_ BO_  "CI_MsgName" STRING ;
BA_DEF_ BO_  "GenMsgCycleTime" INT 0 3600000;
BA_DEF_ BO_  "GenMsgCycleTimeFast" INT 0 3600000;
BA_DEF_ BO_  "GenMsgDelayTime" INT 0 3600000;
BA_DEF_ BO_  "GenMsgILSupport" ENUM  "No","Yes";
BA_DEF_ BO_  "GenMsgNrOfRepetition" INT 0 1000000;
BA_DEF_ BO_  "GenMsgRequestable" INT 0 1;
BA_DEF_ BO_  "GenMsgSendType" ENUM  "cyclic","NotUsed","NotUsed","NotUsed","NotUsed","NotUsed","NotUsed","IfActive","noMsgSendType";
BA_DEF_ BO_  "GenMsgStartDelayTime" INT 0 100000;
BA_DEF_ BO_  "TpJ1939VarDlc" ENUM  "No","Yes";
BA_DEF_ BO_  "VFrameFormat" ENUM  "StandardCAN","ExtendedCAN","reserved","J1939PG";
BA_DEF_ SG_  "CI_ParId" STRING ;
BA_DEF_ SG_  "CI_SigId" INT 0 2147483647;
BA_DEF_ SG_  "CI_SigName" STRING ;
BA_DEF_ SG_  "GenSigEVName" STRING ;
BA_DEF_ SG_  "GenSigILSupport" ENUM  "No","Yes";
BA_DEF_ SG_  "GenSigInactiveValue" INT 0 2147483647;
BA_DEF_ SG_  "GenSigSendType" ENUM  "Cyclic","OnWrite","OnWriteWithRepetition","OnChange","OnChangeWithRepetition","IfActive","IfActiveWithRepetition","NoSigSendType";
BA_DEF_ SG_  "GenSigStartValue" INT 0 2147483647;
BA_DEF_ SG_  "GenSigTimeoutTime_ACM_CANAIR" INT 0 3600000;
BA_DEF_ SG_  "GenSigTimeoutTime_ACU" INT 0 3600000;
BA_DEF_ SG_  "GenSigTimeoutTime_ADCU" INT 0 3600000;
BA_DEF_ SG_  "GenSigTimeoutTime_AI_CAID" INT 0 3600000;
BA_DEF_ SG_  "GenSigTimeoutTime_ASM_ELC5_Fr" INT 0 3600000;
BA_DEF_ SG_  "GenSigTimeoutTime_AVAS" INT 0 3600000;
BA_DEF_ SG_  "GenSigTimeoutTime_Av2HP" INT 0 3600000;
BA_DEF_ SG_  "GenSigTimeoutTime_BCM_NBM" INT 0 3600000;
BA_DEF_ SG_  "GenSigTimeoutTime_BSM_EBS" INT 0 3600000;
BA_DEF_ SG_  "GenSigTimeoutTime_DICO" INT 0 3600000;
BA_DEF_ SG_  "GenSigTimeoutTime_DMS" INT 0 3600000;
BA_DEF_ SG_  "GenSigTimeoutTime_EBS_EBR" INT 0 3600000;
BA_DEF_ SG_  "GenSigTimeoutTime_ECM_MD1_D" INT 0 3600000;
BA_DEF_ SG_  "GenSigTimeoutTime_ECM_MD1_G" INT 0 3600000;
BA_DEF_ SG_  "GenSigTimeoutTime_ETC_DiwaNXT" INT 0 3600000;
BA_DEF_ SG_  "GenSigTimeoutTime_ETC_DiwaNXT_MH" INT 0 3600000;
BA_DEF_ SG_  "GenSigTimeoutTime_ETC_Ecolife2" INT 0 3600000;
BA_DEF_ SG_  "GenSigTimeoutTime_FCCU" INT 0 3600000;
BA_DEF_ SG_  "GenSigTimeoutTime_FMS_FMS4" INT 0 3600000;
BA_DEF_ SG_  "GenSigTimeoutTime_FMS_FMS5" INT 0 3600000;
BA_DEF_ SG_  "GenSigTimeoutTime_HVPDU_HV_BOX" INT 0 3600000;
BA_DEF_ SG_  "GenSigTimeoutTime_IC_MulticII" INT 0 3600000;
BA_DEF_ SG_  "GenSigTimeoutTime_IC_MulticS" INT 0 3600000;
BA_DEF_ SG_  "GenSigTimeoutTime_INVEM1_ELFA3" INT 0 3600000;
BA_DEF_ SG_  "GenSigTimeoutTime_MBMS" INT 0 3600000;
BA_DEF_ SG_  "GenSigTimeoutTime_MCSL" INT 0 3600000;
BA_DEF_ SG_  "GenSigTimeoutTime_MPPxPTFE2" INT 0 3600000;
BA_DEF_ SG_  "GenSigTimeoutTime_PCM" INT 0 3600000;
BA_DEF_ SG_  "GenSigTimeoutTime_RDAB_SmtRadio" INT 0 3600000;
BA_DEF_ SG_  "GenSigTimeoutTime_RM_INTD" INT 0 3600000;
BA_DEF_ SG_  "GenSigTimeoutTime_RM_IRCS" INT 0 3600000;
BA_DEF_ SG_  "GenSigTimeoutTime_SAS" INT 0 3600000;
BA_DEF_ SG_  "GenSigTimeoutTime_SGW" INT 0 3600000;
BA_DEF_ SG_  "GenSigTimeoutTime_SGW2" INT 0 3600000;
BA_DEF_ SG_  "GenSigTimeoutTime_TASM_ETS" INT 0 3600000;
BA_DEF_ SG_  "GenSigTimeoutTime_TMU_HP_Fr" INT 0 3600000;
BA_DEF_ SG_  "GenSigTimeoutTime_TMU_HP_Rr" INT 0 3600000;
BA_DEF_ SG_  "GenSigTimeoutTime_TPMS" INT 0 3600000;
BA_DEF_ SG_  "GenSigTimeoutTime_Tacho_DTCO" INT 0 3600000;
BA_DEF_ SG_  "GenSigTimeoutTime_Tacho_MTCO" INT 0 3600000;
BA_DEF_ SG_  "GenSigTimeoutTime_Tacho_TSU" INT 0 3600000;
BA_DEF_ SG_  "GenSigTimeoutTime_VCM" INT 0 3600000;
BA_DEF_ SG_  "GenSigTimeoutTime_VCU" INT 0 3600000;
BA_DEF_ SG_  "GenSigTimeoutTime_VMU" INT 0 3600000;
BA_DEF_ SG_  "SPN" INT 0 524287;
BA_DEF_ SG_  "SigType" ENUM  "Default","Range","RangeSigned","ASCII","Discrete","Control","ReferencePGN","DTC","StringDelimiter","StringLength","StringLengthControl";
BA_DEF_DEF_  "CI_MsgDefinition" "";
BA_DEF_DEF_  "CI_MsgId" 0;
BA_DEF_DEF_  "CI_MsgName" "";
BA_DEF_DEF_  "GenMsgCycleTime" 0;
BA_DEF_DEF_  "GenMsgCycleTimeFast" 0;
BA_DEF_DEF_  "GenMsgDelayTime" 1;
BA_DEF_DEF_  "GenMsgILSupport" "Yes";
BA_DEF_DEF_  "GenMsgNrOfRepetition" 0;
BA_DEF_DEF_  "GenMsgRequestable" 0;
BA_DEF_DEF_  "GenMsgSendType" "noMsgSendType";
BA_DEF_DEF_  "GenMsgStartDelayTime" 0;
BA_DEF_DEF_  "TpJ1939VarDlc" "No";
BA_DEF_DEF_  "VFrameFormat" "J1939PG";
BA_DEF_DEF_  "CI_ParId" "";
BA_DEF_DEF_  "CI_SigId" 0;
BA_DEF_DEF_  "CI_SigName" "";
BA_DEF_DEF_  "GenSigEVName" "Env@Nodename_@Signame";
BA_DEF_DEF_  "GenSigILSupport" "Yes";
BA_DEF_DEF_  "GenSigInactiveValue" 0;
BA_DEF_DEF_  "GenSigSendType" "NoSigSendType";
BA_DEF_DEF_  "GenSigStartValue" 0;
BA_DEF_DEF_  "GenSigTimeoutTime_ACM_CANAIR" 0;
BA_DEF_DEF_  "GenSigTimeoutTime_ACU" 0;
BA_DEF_DEF_  "GenSigTimeoutTime_ADCU" 0;
BA_DEF_DEF_  "GenSigTimeoutTime_AI_CAID" 0;
BA_DEF_DEF_  "GenSigTimeoutTime_ASM_ELC5_Fr" 0;
BA_DEF_DEF_  "GenSigTimeoutTime_AVAS" 0;
BA_DEF_DEF_  "GenSigTimeoutTime_Av2HP" 0;
BA_DEF_DEF_  "GenSigTimeoutTime_BCM_NBM" 0;
BA_DEF_DEF_  "GenSigTimeoutTime_BSM_EBS" 0;
BA_DEF_DEF_  "GenSigTimeoutTime_DICO" 0;
BA_DEF_DEF_  "GenSigTimeoutTime_DMS" 0;
BA_DEF_DEF_  "GenSigTimeoutTime_EBS_EBR" 0;
BA_DEF_DEF_  "GenSigTimeoutTime_ECM_MD1_D" 0;
BA_DEF_DEF_  "GenSigTimeoutTime_ECM_MD1_G" 0;
BA_DEF_DEF_  "GenSigTimeoutTime_ETC_DiwaNXT" 0;
BA_DEF_DEF_  "GenSigTimeoutTime_ETC_DiwaNXT_MH" 0;
BA_DEF_DEF_  "GenSigTimeoutTime_ETC_Ecolife2" 0;
BA_DEF_DEF_  "GenSigTimeoutTime_FCCU" 0;
BA_DEF_DEF_  "GenSigTimeoutTime_FMS_FMS4" 0;
BA_DEF_DEF_  "GenSigTimeoutTime_FMS_FMS5" 0;
BA_DEF_DEF_  "GenSigTimeoutTime_HVPDU_HV_BOX" 0;
BA_DEF_DEF_  "GenSigTimeoutTime_IC_MulticII" 0;
BA_DEF_DEF_  "GenSigTimeoutTime_IC_MulticS" 0;
BA_DEF_DEF_  "GenSigTimeoutTime_INVEM1_ELFA3" 0;
BA_DEF_DEF_  "GenSigTimeoutTime_MBMS" 0;
BA_DEF_DEF_  "GenSigTimeoutTime_MCSL" 0;
BA_DEF_DEF_  "GenSigTimeoutTime_MPPxPTFE2" 0;
BA_DEF_DEF_  "GenSigTimeoutTime_PCM" 0;
BA_DEF_DEF_  "GenSigTimeoutTime_RDAB_SmtRadio" 0;
BA_DEF_DEF_  "GenSigTimeoutTime_RM_INTD" 0;
BA_DEF_DEF_  "GenSigTimeoutTime_RM_IRCS" 0;
BA_DEF_DEF_  "GenSigTimeoutTime_SAS" 0;
BA_DEF_DEF_  "GenSigTimeoutTime_SGW" 0;
BA_DEF_DEF_  "GenSigTimeoutTime_SGW2" 0;
BA_DEF_DEF_  "GenSigTimeoutTime_TASM_ETS" 0;
BA_DEF_DEF_  "GenSigTimeoutTime_TMU_HP_Fr" 0;
BA_DEF_DEF_  "GenSigTimeoutTime_TMU_HP_Rr" 0;
BA_DEF_DEF_  "GenSigTimeoutTime_TPMS" 0;
BA_DEF_DEF_  "GenSigTimeoutTime_Tacho_DTCO" 0;
BA_DEF_DEF_  "GenSigTimeoutTime_Tacho_MTCO" 0;
BA_DEF_DEF_  "GenSigTimeoutTime_Tacho_TSU" 0;
BA_DEF_DEF_  "GenSigTimeoutTime_VCM" 0;
BA_DEF_DEF_  "GenSigTimeoutTime_VCU" 0;
BA_DEF_DEF_  "GenSigTimeoutTime_VMU" 0;
BA_DEF_DEF_  "SPN" 0;
BA_DEF_DEF_  "SigType" "Default";
BA_ "GenMsgStartDelayTime" BO_ 2650767104 32;
BA_ "GenMsgSendType" BO_ 2650767104 0;
BA_ "GenMsgDelayTime" BO_ 2650767104 250;
BA_ "GenMsgCycleTimeFast" BO_ 2650767104 500;
BA_ "GenMsgCycleTime" BO_ 2650767104 500;
BA_ "CI_MsgName" BO_ 2650767104 "PB_Telemetry15 - Proprietary B - Telemetry 15";
BA_ "CI_MsgId" BO_ 2650767104 17444;
BA_ "CI_MsgDefinition" BO_ 2650767104 "Iveco Proprietary";
BA_ "GenMsgStartDelayTime" BO_ 2650767360 33;
BA_ "GenMsgSendType" BO_ 2650767360 0;
BA_ "GenMsgDelayTime" BO_ 2650767360 250;
BA_ "GenMsgCycleTimeFast" BO_ 2650767360 500;
BA_ "GenMsgCycleTime" BO_ 2650767360 500;
BA_ "CI_MsgName" BO_ 2650767360 "PB_Telemetry16 - Proprietary B - Telemetry 16";
BA_ "CI_MsgId" BO_ 2650767360 17452;
BA_ "CI_MsgDefinition" BO_ 2650767360 "Iveco Proprietary";
BA_ "GenMsgStartDelayTime" BO_ 2650767616 34;
BA_ "GenMsgSendType" BO_ 2650767616 0;
BA_ "GenMsgDelayTime" BO_ 2650767616 250;
BA_ "GenMsgCycleTimeFast" BO_ 2650767616 500;
BA_ "GenMsgCycleTime" BO_ 2650767616 500;
BA_ "CI_MsgName" BO_ 2650767616 "PB_Telemetry17 - Proprietary B - Telemetry 17";
BA_ "CI_MsgId" BO_ 2650767616 17459;
BA_ "CI_MsgDefinition" BO_ 2650767616 "Iveco Proprietary";
BA_ "GenMsgStartDelayTime" BO_ 2650767872 35;
BA_ "GenMsgSendType" BO_ 2650767872 0;
BA_ "GenMsgDelayTime" BO_ 2650767872 250;
BA_ "GenMsgCycleTimeFast" BO_ 2650767872 500;
BA_ "GenMsgCycleTime" BO_ 2650767872 500;
BA_ "CI_MsgName" BO_ 2650767872 "PB_Telemetry18 - Proprietary B - Telemetry 18";
BA_ "CI_MsgId" BO_ 2650767872 17464;
BA_ "CI_MsgDefinition" BO_ 2650767872 "Iveco Proprietary";
BA_ "GenMsgStartDelayTime" BO_ 2650768128 36;
BA_ "GenMsgSendType" BO_ 2650768128 0;
BA_ "GenMsgDelayTime" BO_ 2650768128 250;
BA_ "GenMsgCycleTimeFast" BO_ 2650768128 500;
BA_ "GenMsgCycleTime" BO_ 2650768128 500;
BA_ "CI_MsgName" BO_ 2650768128 "PB_Telemetry19 - Proprietary B - Telemetry 19";
BA_ "CI_MsgId" BO_ 2650768128 17469;
BA_ "CI_MsgDefinition" BO_ 2650768128 "Iveco Proprietary";
BA_ "GenMsgStartDelayTime" BO_ 2650768384 37;
BA_ "GenMsgSendType" BO_ 2650768384 0;
BA_ "GenMsgDelayTime" BO_ 2650768384 250;
BA_ "GenMsgCycleTimeFast" BO_ 2650768384 500;
BA_ "GenMsgCycleTime" BO_ 2650768384 500;
BA_ "CI_MsgName" BO_ 2650768384 "PB_Telemetry20 - Proprietary B - Telemetry 20";
BA_ "CI_MsgId" BO_ 2650768384 17474;
BA_ "CI_MsgDefinition" BO_ 2650768384 "Iveco Proprietary";
BA_ "GenMsgStartDelayTime" BO_ 2650768640 38;
BA_ "GenMsgSendType" BO_ 2650768640 0;
BA_ "GenMsgDelayTime" BO_ 2650768640 250;
BA_ "GenMsgCycleTimeFast" BO_ 2650768640 500;
BA_ "GenMsgCycleTime" BO_ 2650768640 500;
BA_ "CI_MsgName" BO_ 2650768640 "PB_Telemetry21 - Proprietary B - Telemetry 21";
BA_ "CI_MsgId" BO_ 2650768640 17479;
BA_ "CI_MsgDefinition" BO_ 2650768640 "Iveco Proprietary";
BA_ "GenMsgStartDelayTime" BO_ 2650768896 39;
BA_ "GenMsgSendType" BO_ 2650768896 0;
BA_ "GenMsgDelayTime" BO_ 2650768896 250;
BA_ "GenMsgCycleTimeFast" BO_ 2650768896 500;
BA_ "GenMsgCycleTime" BO_ 2650768896 500;
BA_ "CI_MsgName" BO_ 2650768896 "PB_Telemetry22 - Proprietary B - Telemetry 22";
BA_ "CI_MsgId" BO_ 2650768896 17483;
BA_ "CI_MsgDefinition" BO_ 2650768896 "Iveco Proprietary";
BA_ "GenMsgStartDelayTime" BO_ 2650769152 41;
BA_ "GenMsgSendType" BO_ 2650769152 0;
BA_ "GenMsgDelayTime" BO_ 2650769152 250;
BA_ "GenMsgCycleTimeFast" BO_ 2650769152 500;
BA_ "GenMsgCycleTime" BO_ 2650769152 500;
BA_ "CI_MsgName" BO_ 2650769152 "PB_Telemetry23 - Proprietary B - Telemetry 23";
BA_ "CI_MsgId" BO_ 2650769152 17488;
BA_ "CI_MsgDefinition" BO_ 2650769152 "Iveco Proprietary";
BA_ "GenMsgSendType" BO_ 2566907443 0;
BA_ "GenMsgDelayTime" BO_ 2566907443 100;
BA_ "GenMsgCycleTimeFast" BO_ 2566907443 200;
BA_ "GenMsgCycleTime" BO_ 2566907443 200;
BA_ "CI_MsgName" BO_ 2566907443 "PB_TPMS1 - High Line Message (Sensata Technologies Proprietary)";
BA_ "CI_MsgId" BO_ 2566907443 3247;
BA_ "CI_MsgDefinition" BO_ 2566907443 "Sensata Technologies Proprietary";
BA_ "GenMsgStartDelayTime" BO_ 2566867182 51;
BA_ "GenMsgSendType" BO_ 2566867182 0;
BA_ "GenMsgDelayTime" BO_ 2566867182 30000;
BA_ "GenMsgCycleTimeFast" BO_ 2566867182 60000;
BA_ "GenMsgCycleTime" BO_ 2566867182 60000;
BA_ "CI_MsgName" BO_ 2566867182 "PB_VDO1 - VDO1 (Continental Proprietary)";
BA_ "CI_MsgId" BO_ 2566867182 13123;
BA_ "CI_MsgDefinition" BO_ 2566867182 "Continental Proprietary";
BA_ "GenMsgStartDelayTime" BO_ 2566867438 52;
BA_ "GenMsgSendType" BO_ 2566867438 0;
BA_ "GenMsgDelayTime" BO_ 2566867438 30000;
BA_ "GenMsgCycleTimeFast" BO_ 2566867438 60000;
BA_ "GenMsgCycleTime" BO_ 2566867438 60000;
BA_ "CI_MsgName" BO_ 2566867438 "PB_VDO1ex - VDO1 Extended (Continental Proprietary)";
BA_ "CI_MsgId" BO_ 2566867438 13146;
BA_ "CI_MsgDefinition" BO_ 2566867438 "Continental Proprietary";
BA_ "GenMsgStartDelayTime" BO_ 2566867694 53;
BA_ "GenMsgSendType" BO_ 2566867694 0;
BA_ "GenMsgDelayTime" BO_ 2566867694 30000;
BA_ "GenMsgCycleTimeFast" BO_ 2566867694 60000;
BA_ "GenMsgCycleTime" BO_ 2566867694 60000;
BA_ "CI_MsgName" BO_ 2566867694 "PB_VDO2 - VDO2 (Continental Proprietary)";
BA_ "CI_MsgId" BO_ 2566867694 780;
BA_ "CI_MsgDefinition" BO_ 2566867694 "Continental Proprietary";
BA_ "GenMsgStartDelayTime" BO_ 2566892311 52;
BA_ "GenMsgSendType" BO_ 2566892311 0;
BA_ "GenMsgDelayTime" BO_ 2566892311 50;
BA_ "GenMsgCycleTimeFast" BO_ 2566892311 100;
BA_ "GenMsgCycleTime" BO_ 2566892311 1000;
BA_ "CI_MsgName" BO_ 2566892311 "PB_VRUP_17 - Proprietary B - Vulnerable Road User Protection";
BA_ "CI_MsgId" BO_ 2566892311 2884;
BA_ "CI_MsgDefinition" BO_ 2566892311 "Iveco Proprietary";
BA_ "GenMsgStartDelayTime" BO_ 2566892446 19;
BA_ "GenMsgSendType" BO_ 2566892446 0;
BA_ "GenMsgDelayTime" BO_ 2566892446 100;
BA_ "GenMsgCycleTimeFast" BO_ 2566892446 1000;
BA_ "GenMsgCycleTime" BO_ 2566892446 1000;
BA_ "CI_MsgName" BO_ 2566892446 "PB_VRUP_9E - Proprietary B - Vulnerable Road User Protection";
BA_ "CI_MsgId" BO_ 2566892446 2866;
BA_ "CI_MsgDefinition" BO_ 2566892446 "Iveco Proprietary";
BA_ "GenMsgStartDelayTime" BO_ 2631855639 121;
BA_ "GenMsgSendType" BO_ 2631855639 0;
BA_ "GenMsgDelayTime" BO_ 2631855639 500;
BA_ "GenMsgCycleTimeFast" BO_ 2631855639 1000;
BA_ "GenMsgCycleTime" BO_ 2631855639 1000;
BA_ "CI_MsgName" BO_ 2631855639 "RESET_17_EE - Reset";
BA_ "CI_MsgId" BO_ 2631855639 4449;
BA_ "CI_MsgDefinition" BO_ 2631855639 "J1939DA";
BA_ "GenMsgStartDelayTime" BO_ 2566847248 37;
BA_ "GenMsgSendType" BO_ 2566847248 0;
BA_ "GenMsgDelayTime" BO_ 2566847248 500;
BA_ "GenMsgCycleTimeFast" BO_ 2566847248 1000;
BA_ "GenMsgCycleTime" BO_ 2566847248 1000;
BA_ "CI_MsgName" BO_ 2566847248 "RF - Retarder fluids";
BA_ "CI_MsgId" BO_ 2566847248 651;
BA_ "CI_MsgDefinition" BO_ 2566847248 "J1939DA";
BA_ "CI_MsgName" BO_ 2565537539 "RQST_03 - Request";
BA_ "CI_MsgId" BO_ 2565537539 11044;
BA_ "CI_MsgDefinition" BO_ 2565537539 "J1939 broadcast";
BA_ "CI_MsgName" BO_ 2565485386 "RQST_4A_33 - Request";
BA_ "CI_MsgId" BO_ 2565485386 11096;
BA_ "CI_MsgDefinition" BO_ 2565485386 "J1939 broadcast";
BA_ "CI_MsgName" BO_ 2565533258 "RQST_4A_EE - Request";
BA_ "CI_MsgId" BO_ 2565533258 13165;
BA_ "CI_MsgDefinition" BO_ 2565533258 "J1939 broadcast";
BA_ "GenMsgStartDelayTime" BO_ 2566852224 24;
BA_ "GenMsgSendType" BO_ 2566852224 0;
BA_ "GenMsgDelayTime" BO_ 2566852224 100;
BA_ "GenMsgCycleTimeFast" BO_ 2566852224 200;
BA_ "GenMsgCycleTime" BO_ 2566852224 200;
BA_ "CI_MsgName" BO_ 2566852224 "SCU2CAMU - VCU2CAMU";
BA_ "CI_MsgId" BO_ 2566852224 3318;
BA_ "CI_MsgDefinition" BO_ 2566852224 "Iveco Proprietary";
BA_ "TpJ1939VarDlc" BO_ 2566838813 1;
BA_ "CI_MsgName" BO_ 2566838813 "SOFT_1D - Software Identification";
BA_ "CI_MsgId" BO_ 2566838813 10443;
BA_ "CI_MsgDefinition" BO_ 2566838813 "J1939 broadcast";
BA_ "TpJ1939VarDlc" BO_ 2566838878 1;
BA_ "CI_MsgName" BO_ 2566838878 "SOFT_5E - Software Identification";
BA_ "CI_MsgId" BO_ 2566838878 10433;
BA_ "CI_MsgDefinition" BO_ 2566838878 "J1939 broadcast";
BA_ "GenMsgStartDelayTime" BO_ 2566869235 44;
BA_ "GenMsgSendType" BO_ 2566869235 0;
BA_ "GenMsgDelayTime" BO_ 2566869235 2500;
BA_ "GenMsgCycleTimeFast" BO_ 2566869235 5000;
BA_ "GenMsgCycleTime" BO_ 2566869235 5000;
BA_ "CI_MsgName" BO_ 2566869235 "SOH - Branches State of Health";
BA_ "CI_MsgId" BO_ 2566869235 2909;
BA_ "CI_MsgDefinition" BO_ 2566869235 "Iveco Bus Proprietary";
BA_ "GenMsgStartDelayTime" BO_ 2566869491 50;
BA_ "GenMsgSendType" BO_ 2566869491 0;
BA_ "GenMsgDelayTime" BO_ 2566869491 2500;
BA_ "GenMsgCycleTimeFast" BO_ 2566869491 5000;
BA_ "GenMsgCycleTime" BO_ 2566869491 5000;
BA_ "CI_MsgName" BO_ 2566869491 "SOH2 - Branches State of Health";
BA_ "CI_MsgId" BO_ 2566869491 2921;
BA_ "CI_MsgDefinition" BO_ 2566869491 "Iveco Bus Proprietary";
BA_ "GenMsgStartDelayTime" BO_ 2566884079 11;
BA_ "GenMsgSendType" BO_ 2566884079 0;
BA_ "GenMsgDelayTime" BO_ 2566884079 250;
BA_ "GenMsgCycleTimeFast" BO_ 2566884079 500;
BA_ "GenMsgCycleTime" BO_ 2566884079 500;
BA_ "CI_MsgName" BO_ 2566884079 "StTU1 - StatusTracUnit1";
BA_ "CI_MsgId" BO_ 2566884079 1458;
BA_ "CI_MsgDefinition" BO_ 2566884079 "Iveco Proprietary";
BA_ "GenMsgStartDelayTime" BO_ 2348884337 6;
BA_ "GenMsgSendType" BO_ 2348884337 0;
BA_ "GenMsgDelayTime" BO_ 2348884337 25;
BA_ "GenMsgCycleTimeFast" BO_ 2348884337 50;
BA_ "GenMsgCycleTime" BO_ 2348884337 50;
BA_ "CI_MsgName" BO_ 2348884337 "Swi2Bc - Steering Wheel Interface to Body Computer";
BA_ "CI_MsgId" BO_ 2348884337 3732;
BA_ "CI_MsgDefinition" BO_ 2348884337 "Iveco SPR2 Proprietary";
BA_ "GenMsgStartDelayTime" BO_ 2365484270 6;
BA_ "GenMsgSendType" BO_ 2365484270 0;
BA_ "GenMsgDelayTime" BO_ 2365484270 25;
BA_ "GenMsgCycleTimeFast" BO_ 2365484270 50;
BA_ "GenMsgCycleTime" BO_ 2365484270 50;
BA_ "CI_MsgName" BO_ 2365484270 "TCO1 - Tachograph";
BA_ "CI_MsgId" BO_ 2365484270 655;
BA_ "CI_MsgDefinition" BO_ 2365484270 "J1939DA";
BA_ "GenMsgStartDelayTime" BO_ 2566842094 30;
BA_ "GenMsgSendType" BO_ 2566842094 0;
BA_ "GenMsgDelayTime" BO_ 2566842094 500;
BA_ "GenMsgCycleTimeFast" BO_ 2566842094 1000;
BA_ "GenMsgCycleTime" BO_ 2566842094 1000;
BA_ "CI_MsgName" BO_ 2566842094 "TD - Time/Date";
BA_ "CI_MsgId" BO_ 2566842094 694;
BA_ "CI_MsgDefinition" BO_ 2566842094 "J1939DA";
BA_ "GenMsgStartDelayTime" BO_ 2566854213 148;
BA_ "GenMsgSendType" BO_ 2566854213 0;
BA_ "GenMsgDelayTime" BO_ 2566854213 500;
BA_ "GenMsgCycleTimeFast" BO_ 2566854213 1000;
BA_ "GenMsgCycleTime" BO_ 2566854213 1000;
BA_ "CI_MsgName" BO_ 2566854213 "Telemat_1 - Telemat message 1";
BA_ "CI_MsgId" BO_ 2566854213 1783;
BA_ "CI_MsgDefinition" BO_ 2566854213 "Iveco Bus Proprietary";
BA_ "VFrameFormat" BO_ 2566858309 1;
BA_ "GenMsgStartDelayTime" BO_ 2566858309 167;
BA_ "GenMsgSendType" BO_ 2566858309 0;
BA_ "GenMsgDelayTime" BO_ 2566858309 500;
BA_ "GenMsgCycleTimeFast" BO_ 2566858309 1000;
BA_ "GenMsgCycleTime" BO_ 2566858309 1000;
BA_ "CI_MsgName" BO_ 2566858309 "Telemat_2 - Telemat message 2";
BA_ "CI_MsgId" BO_ 2566858309 1847;
BA_ "CI_MsgDefinition" BO_ 2566858309 "Wabco Proprietary";
BA_ "SigType" SG_ 2650767104 osMisfInjCyl2Tmp200 1;
BA_ "GenSigTimeoutTime_SGW" SG_ 2650767104 osMisfInjCyl2Tmp200 2500;
BA_ "GenSigTimeoutTime_PCM" SG_ 2650767104 osMisfInjCyl2Tmp200 2500;
BA_ "CI_SigName" SG_ 2650767104 osMisfInjCyl2Tmp200 "Misfuel counter for cylinder 2 in a 200 rpm window";
BA_ "CI_SigId" SG_ 2650767104 osMisfInjCyl2Tmp200 17451;
BA_ "CI_ParId" SG_ 2650767104 osMisfInjCyl2Tmp200 "F344";
BA_ "SigType" SG_ 2650767104 osMisfInjCyl1Tmp200 1;
BA_ "GenSigTimeoutTime_SGW" SG_ 2650767104 osMisfInjCyl1Tmp200 2500;
BA_ "GenSigTimeoutTime_PCM" SG_ 2650767104 osMisfInjCyl1Tmp200 2500;
BA_ "CI_SigName" SG_ 2650767104 osMisfInjCyl1Tmp200 "Misfuel counter for cylinder 1 in a 200 rpm window";
BA_ "CI_SigId" SG_ 2650767104 osMisfInjCyl1Tmp200 17450;
BA_ "CI_ParId" SG_ 2650767104 osMisfInjCyl1Tmp200 "F343";
BA_ "SigType" SG_ 2650767104 osMisfCoilTotTmp200 1;
BA_ "GenSigTimeoutTime_SGW" SG_ 2650767104 osMisfCoilTotTmp200 2500;
BA_ "GenSigTimeoutTime_PCM" SG_ 2650767104 osMisfCoilTotTmp200 2500;
BA_ "CI_SigName" SG_ 2650767104 osMisfCoilTotTmp200 "Misfire total cylinder counter in a 200 rpm window";
BA_ "CI_SigId" SG_ 2650767104 osMisfCoilTotTmp200 17449;
BA_ "CI_ParId" SG_ 2650767104 osMisfCoilTotTmp200 "F342";
BA_ "SigType" SG_ 2650767104 osMisfCoilCyl6Tmp200 1;
BA_ "GenSigTimeoutTime_SGW" SG_ 2650767104 osMisfCoilCyl6Tmp200 2500;
BA_ "GenSigTimeoutTime_PCM" SG_ 2650767104 osMisfCoilCyl6Tmp200 2500;
BA_ "CI_SigName" SG_ 2650767104 osMisfCoilCyl6Tmp200 "Misfire counter for cylinder 6 in a 200 rpm window";
BA_ "CI_SigId" SG_ 2650767104 osMisfCoilCyl6Tmp200 17448;
BA_ "CI_ParId" SG_ 2650767104 osMisfCoilCyl6Tmp200 "F341";
BA_ "SigType" SG_ 2650767104 osMisfCoilCyl5Tmp200 1;
BA_ "GenSigTimeoutTime_SGW" SG_ 2650767104 osMisfCoilCyl5Tmp200 2500;
BA_ "GenSigTimeoutTime_PCM" SG_ 2650767104 osMisfCoilCyl5Tmp200 2500;
BA_ "CI_SigName" SG_ 2650767104 osMisfCoilCyl5Tmp200 "Misfire counter for cylinder 5 in a 200 rpm window";
BA_ "CI_SigId" SG_ 2650767104 osMisfCoilCyl5Tmp200 17447;
BA_ "CI_ParId" SG_ 2650767104 osMisfCoilCyl5Tmp200 "F340";
BA_ "SigType" SG_ 2650767104 osMisfCoilCyl4Tmp200 1;
BA_ "GenSigTimeoutTime_SGW" SG_ 2650767104 osMisfCoilCyl4Tmp200 2500;
BA_ "GenSigTimeoutTime_PCM" SG_ 2650767104 osMisfCoilCyl4Tmp200 2500;
BA_ "CI_SigName" SG_ 2650767104 osMisfCoilCyl4Tmp200 "Misfire counter for cylinder 4 in a 200 rpm window";
BA_ "CI_SigId" SG_ 2650767104 osMisfCoilCyl4Tmp200 17446;
BA_ "CI_ParId" SG_ 2650767104 osMisfCoilCyl4Tmp200 "F339";
BA_ "SigType" SG_ 2650767104 osMisfCoilCyl3Tmp200 1;
BA_ "GenSigTimeoutTime_SGW" SG_ 2650767104 osMisfCoilCyl3Tmp200 2500;
BA_ "GenSigTimeoutTime_PCM" SG_ 2650767104 osMisfCoilCyl3Tmp200 2500;
BA_ "CI_SigName" SG_ 2650767104 osMisfCoilCyl3Tmp200 "Misfire counter for cylinder 3 in a 200 rpm window";
BA_ "CI_SigId" SG_ 2650767104 osMisfCoilCyl3Tmp200 17445;
BA_ "CI_ParId" SG_ 2650767104 osMisfCoilCyl3Tmp200 "F338";
BA_ "SigType" SG_ 2650767360 osMSFRD_CYL_THR200 1;
BA_ "GenSigTimeoutTime_SGW" SG_ 2650767360 osMSFRD_CYL_THR200 2500;
BA_ "GenSigTimeoutTime_PCM" SG_ 2650767360 osMSFRD_CYL_THR200 2500;
BA_ "CI_SigName" SG_ 2650767360 osMSFRD_CYL_THR200 "Threshold for misfire and misfuel counters in a 200 rpm window";
BA_ "CI_SigId" SG_ 2650767360 osMSFRD_CYL_THR200 17458;
BA_ "CI_ParId" SG_ 2650767360 osMSFRD_CYL_THR200 "F350";
BA_ "SigType" SG_ 2650767360 osMisfInjTotTmp200 1;
BA_ "GenSigTimeoutTime_SGW" SG_ 2650767360 osMisfInjTotTmp200 2500;
BA_ "GenSigTimeoutTime_PCM" SG_ 2650767360 osMisfInjTotTmp200 2500;
BA_ "CI_SigName" SG_ 2650767360 osMisfInjTotTmp200 "Misfuel total cylinder counter in a 200 rpm window";
BA_ "CI_SigId" SG_ 2650767360 osMisfInjTotTmp200 17457;
BA_ "CI_ParId" SG_ 2650767360 osMisfInjTotTmp200 "F349";
BA_ "SigType" SG_ 2650767360 osMisfInjCyl6Tmp200 1;
BA_ "GenSigTimeoutTime_SGW" SG_ 2650767360 osMisfInjCyl6Tmp200 2500;
BA_ "GenSigTimeoutTime_PCM" SG_ 2650767360 osMisfInjCyl6Tmp200 2500;
BA_ "CI_SigName" SG_ 2650767360 osMisfInjCyl6Tmp200 "Misfuel counter for cylinder 6 in a 200 rpm window";
BA_ "CI_SigId" SG_ 2650767360 osMisfInjCyl6Tmp200 17456;
BA_ "CI_ParId" SG_ 2650767360 osMisfInjCyl6Tmp200 "F348";
BA_ "SigType" SG_ 2650767360 osMisfInjCyl5Tmp200 1;
BA_ "GenSigTimeoutTime_SGW" SG_ 2650767360 osMisfInjCyl5Tmp200 2500;
BA_ "GenSigTimeoutTime_PCM" SG_ 2650767360 osMisfInjCyl5Tmp200 2500;
BA_ "CI_SigName" SG_ 2650767360 osMisfInjCyl5Tmp200 "Misfuel counter for cylinder 5 in a 200 rpm window";
BA_ "CI_SigId" SG_ 2650767360 osMisfInjCyl5Tmp200 17455;
BA_ "CI_ParId" SG_ 2650767360 osMisfInjCyl5Tmp200 "F347";
BA_ "SigType" SG_ 2650767360 osMisfInjCyl4Tmp200 1;
BA_ "GenSigTimeoutTime_SGW" SG_ 2650767360 osMisfInjCyl4Tmp200 2500;
BA_ "GenSigTimeoutTime_PCM" SG_ 2650767360 osMisfInjCyl4Tmp200 2500;
BA_ "CI_SigName" SG_ 2650767360 osMisfInjCyl4Tmp200 "Misfuel counter for cylinder 4 in a 200 rpm window";
BA_ "CI_SigId" SG_ 2650767360 osMisfInjCyl4Tmp200 17454;
BA_ "CI_ParId" SG_ 2650767360 osMisfInjCyl4Tmp200 "F346";
BA_ "SigType" SG_ 2650767360 osMisfInjCyl3Tmp200 1;
BA_ "GenSigTimeoutTime_SGW" SG_ 2650767360 osMisfInjCyl3Tmp200 2500;
BA_ "GenSigTimeoutTime_PCM" SG_ 2650767360 osMisfInjCyl3Tmp200 2500;
BA_ "CI_SigName" SG_ 2650767360 osMisfInjCyl3Tmp200 "Misfuel counter for cylinder 3 in a 200 rpm window";
BA_ "CI_SigId" SG_ 2650767360 osMisfInjCyl3Tmp200 17453;
BA_ "CI_ParId" SG_ 2650767360 osMisfInjCyl3Tmp200 "F345";
BA_ "SigType" SG_ 2650767616 osMisfCoilCyl3Tmp1000 1;
BA_ "GenSigTimeoutTime_SGW" SG_ 2650767616 osMisfCoilCyl3Tmp1000 2500;
BA_ "GenSigTimeoutTime_PCM" SG_ 2650767616 osMisfCoilCyl3Tmp1000 2500;
BA_ "CI_SigName" SG_ 2650767616 osMisfCoilCyl3Tmp1000 "Misfire counter for cylinder 3 in a 1000 rpm window";
BA_ "CI_SigId" SG_ 2650767616 osMisfCoilCyl3Tmp1000 17463;
BA_ "CI_ParId" SG_ 2650767616 osMisfCoilCyl3Tmp1000 "F354";
BA_ "SigType" SG_ 2650767616 osMisfCoilCyl2Tmp1000 1;
BA_ "GenSigTimeoutTime_SGW" SG_ 2650767616 osMisfCoilCyl2Tmp1000 2500;
BA_ "GenSigTimeoutTime_PCM" SG_ 2650767616 osMisfCoilCyl2Tmp1000 2500;
BA_ "CI_SigName" SG_ 2650767616 osMisfCoilCyl2Tmp1000 "Misfire counter for cylinder 2 in a 1000 rpm window";
BA_ "CI_SigId" SG_ 2650767616 osMisfCoilCyl2Tmp1000 17462;
BA_ "CI_ParId" SG_ 2650767616 osMisfCoilCyl2Tmp1000 "F353";
BA_ "SigType" SG_ 2650767616 osMisfCoilCyl1Tmp1000 1;
BA_ "GenSigTimeoutTime_SGW" SG_ 2650767616 osMisfCoilCyl1Tmp1000 2500;
BA_ "GenSigTimeoutTime_PCM" SG_ 2650767616 osMisfCoilCyl1Tmp1000 2500;
BA_ "CI_SigName" SG_ 2650767616 osMisfCoilCyl1Tmp1000 "Misfire counter for cylinder 1 in a 1000 rpm window";
BA_ "CI_SigId" SG_ 2650767616 osMisfCoilCyl1Tmp1000 17461;
BA_ "CI_ParId" SG_ 2650767616 osMisfCoilCyl1Tmp1000 "F352";
BA_ "SigType" SG_ 2650767616 osMsfrdSeu200 1;
BA_ "GenSigTimeoutTime_SGW" SG_ 2650767616 osMsfrdSeu200 2500;
BA_ "GenSigTimeoutTime_PCM" SG_ 2650767616 osMsfrdSeu200 2500;
BA_ "CI_SigName" SG_ 2650767616 osMsfrdSeu200 "Threshold for sum of total misfire and misfuel counters in a 200 rpm window";
BA_ "CI_SigId" SG_ 2650767616 osMsfrdSeu200 17460;
BA_ "CI_ParId" SG_ 2650767616 osMsfrdSeu200 "F351";
BA_ "SigType" SG_ 2650767872 osMisfCoilTotTmp1000 1;
BA_ "GenSigTimeoutTime_SGW" SG_ 2650767872 osMisfCoilTotTmp1000 2500;
BA_ "GenSigTimeoutTime_PCM" SG_ 2650767872 osMisfCoilTotTmp1000 2500;
BA_ "CI_SigName" SG_ 2650767872 osMisfCoilTotTmp1000 "Misfire total cylinder counter in a 1000 rpm window";
BA_ "CI_SigId" SG_ 2650767872 osMisfCoilTotTmp1000 17468;
BA_ "CI_ParId" SG_ 2650767872 osMisfCoilTotTmp1000 "F358";
BA_ "SigType" SG_ 2650767872 osMisfCoilCyl6Tmp1000 1;
BA_ "GenSigTimeoutTime_SGW" SG_ 2650767872 osMisfCoilCyl6Tmp1000 2500;
BA_ "GenSigTimeoutTime_PCM" SG_ 2650767872 osMisfCoilCyl6Tmp1000 2500;
BA_ "CI_SigName" SG_ 2650767872 osMisfCoilCyl6Tmp1000 "Misfire counter for cylinder 6 in a 1000 rpm window";
BA_ "CI_SigId" SG_ 2650767872 osMisfCoilCyl6Tmp1000 17467;
BA_ "CI_ParId" SG_ 2650767872 osMisfCoilCyl6Tmp1000 "F357";
BA_ "SigType" SG_ 2650767872 osMisfCoilCyl5Tmp1000 1;
BA_ "GenSigTimeoutTime_SGW" SG_ 2650767872 osMisfCoilCyl5Tmp1000 2500;
BA_ "GenSigTimeoutTime_PCM" SG_ 2650767872 osMisfCoilCyl5Tmp1000 2500;
BA_ "CI_SigName" SG_ 2650767872 osMisfCoilCyl5Tmp1000 "Misfire counter for cylinder 5 in a 1000 rpm window";
BA_ "CI_SigId" SG_ 2650767872 osMisfCoilCyl5Tmp1000 17466;
BA_ "CI_ParId" SG_ 2650767872 osMisfCoilCyl5Tmp1000 "F356";
BA_ "SigType" SG_ 2650767872 osMisfCoilCyl4Tmp1000 1;
BA_ "GenSigTimeoutTime_SGW" SG_ 2650767872 osMisfCoilCyl4Tmp1000 2500;
BA_ "GenSigTimeoutTime_PCM" SG_ 2650767872 osMisfCoilCyl4Tmp1000 2500;
BA_ "CI_SigName" SG_ 2650767872 osMisfCoilCyl4Tmp1000 "Misfire counter for cylinder 4 in a 1000 rpm window";
BA_ "CI_SigId" SG_ 2650767872 osMisfCoilCyl4Tmp1000 17465;
BA_ "CI_ParId" SG_ 2650767872 osMisfCoilCyl4Tmp1000 "F355";
BA_ "SigType" SG_ 2650768128 osMisfInjCyl4Tmp1000 1;
BA_ "GenSigTimeoutTime_SGW" SG_ 2650768128 osMisfInjCyl4Tmp1000 2500;
BA_ "GenSigTimeoutTime_PCM" SG_ 2650768128 osMisfInjCyl4Tmp1000 2500;
BA_ "CI_SigName" SG_ 2650768128 osMisfInjCyl4Tmp1000 "Misfuel counter for cylinder 4 in a 1000 rpm window";
BA_ "CI_SigId" SG_ 2650768128 osMisfInjCyl4Tmp1000 17473;
BA_ "CI_ParId" SG_ 2650768128 osMisfInjCyl4Tmp1000 "F362";
BA_ "SigType" SG_ 2650768128 osMisfInjCyl3Tmp1000 1;
BA_ "GenSigTimeoutTime_SGW" SG_ 2650768128 osMisfInjCyl3Tmp1000 2500;
BA_ "GenSigTimeoutTime_PCM" SG_ 2650768128 osMisfInjCyl3Tmp1000 2500;
BA_ "CI_SigName" SG_ 2650768128 osMisfInjCyl3Tmp1000 "Misfuel counter for cylinder 3 in a 1000 rpm window";
BA_ "CI_SigId" SG_ 2650768128 osMisfInjCyl3Tmp1000 17472;
BA_ "CI_ParId" SG_ 2650768128 osMisfInjCyl3Tmp1000 "F361";
BA_ "SigType" SG_ 2650768128 osMisfInjCyl2Tmp1000 1;
BA_ "GenSigTimeoutTime_SGW" SG_ 2650768128 osMisfInjCyl2Tmp1000 2500;
BA_ "GenSigTimeoutTime_PCM" SG_ 2650768128 osMisfInjCyl2Tmp1000 2500;
BA_ "CI_SigName" SG_ 2650768128 osMisfInjCyl2Tmp1000 "Misfuel counter for cylinder 2 in a 1000 rpm window";
BA_ "CI_SigId" SG_ 2650768128 osMisfInjCyl2Tmp1000 17471;
BA_ "CI_ParId" SG_ 2650768128 osMisfInjCyl2Tmp1000 "F360";
BA_ "SigType" SG_ 2650768128 osMisfInjCyl1Tmp1000 1;
BA_ "GenSigTimeoutTime_SGW" SG_ 2650768128 osMisfInjCyl1Tmp1000 2500;
BA_ "GenSigTimeoutTime_PCM" SG_ 2650768128 osMisfInjCyl1Tmp1000 2500;
BA_ "CI_SigName" SG_ 2650768128 osMisfInjCyl1Tmp1000 "Misfuel counter for cylinder 1 in a 1000 rpm window";
BA_ "CI_SigId" SG_ 2650768128 osMisfInjCyl1Tmp1000 17470;
BA_ "CI_ParId" SG_ 2650768128 osMisfInjCyl1Tmp1000 "F359";
BA_ "SigType" SG_ 2650768384 osMSFRD_CYL_THR1000 1;
BA_ "GenSigTimeoutTime_SGW" SG_ 2650768384 osMSFRD_CYL_THR1000 2500;
BA_ "GenSigTimeoutTime_PCM" SG_ 2650768384 osMSFRD_CYL_THR1000 2500;
BA_ "CI_SigName" SG_ 2650768384 osMSFRD_CYL_THR1000 "Threshold for misfire and misfuel counters in a 1000 rpm window";
BA_ "CI_SigId" SG_ 2650768384 osMSFRD_CYL_THR1000 17478;
BA_ "CI_ParId" SG_ 2650768384 osMSFRD_CYL_THR1000 "F366";
BA_ "SigType" SG_ 2650768384 osMisfInjTotTmp1000 1;
BA_ "GenSigTimeoutTime_SGW" SG_ 2650768384 osMisfInjTotTmp1000 2500;
BA_ "GenSigTimeoutTime_PCM" SG_ 2650768384 osMisfInjTotTmp1000 2500;
BA_ "CI_SigName" SG_ 2650768384 osMisfInjTotTmp1000 "Misfuel total cylinder counter in a 1000 rpm window";
BA_ "CI_SigId" SG_ 2650768384 osMisfInjTotTmp1000 17477;
BA_ "CI_ParId" SG_ 2650768384 osMisfInjTotTmp1000 "F365";
BA_ "SigType" SG_ 2650768384 osMisfInjCyl6Tmp1000 1;
BA_ "GenSigTimeoutTime_SGW" SG_ 2650768384 osMisfInjCyl6Tmp1000 2500;
BA_ "GenSigTimeoutTime_PCM" SG_ 2650768384 osMisfInjCyl6Tmp1000 2500;
BA_ "CI_SigName" SG_ 2650768384 osMisfInjCyl6Tmp1000 "Misfuel counter for cylinder 6 in a 1000 rpm window";
BA_ "CI_SigId" SG_ 2650768384 osMisfInjCyl6Tmp1000 17476;
BA_ "CI_ParId" SG_ 2650768384 osMisfInjCyl6Tmp1000 "F364";
BA_ "SigType" SG_ 2650768384 osMisfInjCyl5Tmp1000 1;
BA_ "GenSigTimeoutTime_SGW" SG_ 2650768384 osMisfInjCyl5Tmp1000 2500;
BA_ "GenSigTimeoutTime_PCM" SG_ 2650768384 osMisfInjCyl5Tmp1000 2500;
BA_ "CI_SigName" SG_ 2650768384 osMisfInjCyl5Tmp1000 "Misfuel counter for cylinder 5 in a 1000 rpm window";
BA_ "CI_SigId" SG_ 2650768384 osMisfInjCyl5Tmp1000 17475;
BA_ "CI_ParId" SG_ 2650768384 osMisfInjCyl5Tmp1000 "F363";
BA_ "SigType" SG_ 2650768640 osLsfSensSigmaTwcEffMon 1;
BA_ "GenSigTimeoutTime_SGW" SG_ 2650768640 osLsfSensSigmaTwcEffMon 2500;
BA_ "GenSigTimeoutTime_PCM" SG_ 2650768640 osLsfSensSigmaTwcEffMon 2500;
BA_ "CI_SigName" SG_ 2650768640 osLsfSensSigmaTwcEffMon "Lambda probe oscillation";
BA_ "CI_SigId" SG_ 2650768640 osLsfSensSigmaTwcEffMon 17482;
BA_ "CI_ParId" SG_ 2650768640 osLsfSensSigmaTwcEffMon "F369";
BA_ "SigType" SG_ 2650768640 osLsfSensSigmaCnt 1;
BA_ "GenSigTimeoutTime_SGW" SG_ 2650768640 osLsfSensSigmaCnt 2500;
BA_ "GenSigTimeoutTime_PCM" SG_ 2650768640 osLsfSensSigmaCnt 2500;
BA_ "CI_SigName" SG_ 2650768640 osLsfSensSigmaCnt "Counter of active faults (based on sigma over threshold)";
BA_ "CI_SigId" SG_ 2650768640 osLsfSensSigmaCnt 17481;
BA_ "CI_ParId" SG_ 2650768640 osLsfSensSigmaCnt "F368";
BA_ "SigType" SG_ 2650768640 osMsfrdSeu1000 1;
BA_ "GenSigTimeoutTime_SGW" SG_ 2650768640 osMsfrdSeu1000 2500;
BA_ "GenSigTimeoutTime_PCM" SG_ 2650768640 osMsfrdSeu1000 2500;
BA_ "CI_SigName" SG_ 2650768640 osMsfrdSeu1000 "Threshold for sum of total misfire and misfuel counters in a 1000 rpm window";
BA_ "CI_SigId" SG_ 2650768640 osMsfrdSeu1000 17480;
BA_ "CI_ParId" SG_ 2650768640 osMsfrdSeu1000 "F367";
BA_ "SigType" SG_ 2650768896 PEMS_rNOxDsCorrPEMS_mp 1;
BA_ "GenSigTimeoutTime_SGW" SG_ 2650768896 PEMS_rNOxDsCorrPEMS_mp 2500;
BA_ "GenSigTimeoutTime_PCM" SG_ 2650768896 PEMS_rNOxDsCorrPEMS_mp 2500;
BA_ "CI_SigName" SG_ 2650768896 PEMS_rNOxDsCorrPEMS_mp "PEMS module corrected NOx concentration";
BA_ "CI_SigId" SG_ 2650768896 PEMS_rNOxDsCorrPEMS_mp 17487;
BA_ "CI_ParId" SG_ 2650768896 PEMS_rNOxDsCorrPEMS_mp "F373";
BA_ "SigType" SG_ 2650768896 zsPCpf 1;
BA_ "GenSigTimeoutTime_SGW" SG_ 2650768896 zsPCpf 2500;
BA_ "GenSigTimeoutTime_PCM" SG_ 2650768896 zsPCpf 2500;
BA_ "CI_SigName" SG_ 2650768896 zsPCpf "Differential pressure over CPF";
BA_ "CI_SigId" SG_ 2650768896 zsPCpf 17486;
BA_ "CI_ParId" SG_ 2650768896 zsPCpf "F372";
BA_ "SigType" SG_ 2650768896 osTwcEffMonEnCond 1;
BA_ "GenSigTimeoutTime_SGW" SG_ 2650768896 osTwcEffMonEnCond 2500;
BA_ "GenSigTimeoutTime_PCM" SG_ 2650768896 osTwcEffMonEnCond 2500;
BA_ "CI_SigName" SG_ 2650768896 osTwcEffMonEnCond "Status of enabling conditions of catalyst efficiency diagnosis";
BA_ "CI_SigId" SG_ 2650768896 osTwcEffMonEnCond 17485;
BA_ "CI_ParId" SG_ 2650768896 osTwcEffMonEnCond "F371";
BA_ "SigType" SG_ 2650768896 osLsfSensSigmaTwcEffMonErrSt 1;
BA_ "GenSigTimeoutTime_SGW" SG_ 2650768896 osLsfSensSigmaTwcEffMonErrSt 2500;
BA_ "GenSigTimeoutTime_PCM" SG_ 2650768896 osLsfSensSigmaTwcEffMonErrSt 2500;
BA_ "CI_SigName" SG_ 2650768896 osLsfSensSigmaTwcEffMonErrSt "Status of catalyst efficiency diagnosis";
BA_ "CI_SigId" SG_ 2650768896 osLsfSensSigmaTwcEffMonErrSt 17484;
BA_ "CI_ParId" SG_ 2650768896 osLsfSensSigmaTwcEffMonErrSt "F370";
BA_ "SigType" SG_ 2650769152 osLsfSensSigmaTwcEffMonFaultCk 1;
BA_ "GenSigTimeoutTime_SGW" SG_ 2650769152 osLsfSensSigmaTwcEffMonFaultCk 2500;
BA_ "GenSigTimeoutTime_PCM" SG_ 2650769152 osLsfSensSigmaTwcEffMonFaultCk 2500;
BA_ "CI_SigName" SG_ 2650769152 osLsfSensSigmaTwcEffMonFaultCk "Sigma under or over threshold";
BA_ "CI_SigId" SG_ 2650769152 osLsfSensSigmaTwcEffMonFaultCk 17492;
BA_ "CI_ParId" SG_ 2650769152 osLsfSensSigmaTwcEffMonFaultCk "F377";
BA_ "SigType" SG_ 2650769152 dsWGTDuty 1;
BA_ "GenSigTimeoutTime_SGW" SG_ 2650769152 dsWGTDuty 2500;
BA_ "GenSigTimeoutTime_PCM" SG_ 2650769152 dsWGTDuty 2500;
BA_ "CI_SigName" SG_ 2650769152 dsWGTDuty "Waste Gate control valve opening";
BA_ "CI_SigId" SG_ 2650769152 dsWGTDuty 17491;
BA_ "CI_ParId" SG_ 2650769152 dsWGTDuty "F376";
BA_ "SigType" SG_ 2650769152 zsTuTwc 1;
BA_ "GenSigTimeoutTime_SGW" SG_ 2650769152 zsTuTwc 2500;
BA_ "GenSigTimeoutTime_PCM" SG_ 2650769152 zsTuTwc 2500;
BA_ "GenSigStartValue" SG_ 2650769152 zsTuTwc 40;
BA_ "CI_SigName" SG_ 2650769152 zsTuTwc "Upstream catalyzer temperature";
BA_ "CI_SigId" SG_ 2650769152 zsTuTwc 17490;
BA_ "CI_ParId" SG_ 2650769152 zsTuTwc "F375";
BA_ "SigType" SG_ 2650769152 nsRNoxCor1NoxDs 1;
BA_ "GenSigTimeoutTime_SGW" SG_ 2650769152 nsRNoxCor1NoxDs 2500;
BA_ "GenSigTimeoutTime_PCM" SG_ 2650769152 nsRNoxCor1NoxDs 2500;
BA_ "CI_SigName" SG_ 2650769152 nsRNoxCor1NoxDs "Corrected Downstream NOx concentration";
BA_ "CI_SigId" SG_ 2650769152 nsRNoxCor1NoxDs 17489;
BA_ "CI_ParId" SG_ 2650769152 nsRNoxCor1NoxDs "F374";
BA_ "GenSigTimeoutTime_SGW" SG_ 2566907443 TyrePrsSts 1000;
BA_ "GenSigTimeoutTime_PCM" SG_ 2566907443 TyrePrsSts 1000;
BA_ "GenSigTimeoutTime_MPPxPTFE2" SG_ 2566907443 TyrePrsSts 1000;
BA_ "GenSigTimeoutTime_IC_MulticS" SG_ 2566907443 TyrePrsSts 1000;
BA_ "GenSigTimeoutTime_IC_MulticII" SG_ 2566907443 TyrePrsSts 1000;
BA_ "GenSigTimeoutTime_FMS_FMS5" SG_ 2566907443 TyrePrsSts 1000;
BA_ "CI_SigName" SG_ 2566907443 TyrePrsSts "Tyre Pressure Status";
BA_ "CI_SigId" SG_ 2566907443 TyrePrsSts 3254;
BA_ "CI_ParId" SG_ 2566907443 TyrePrsSts "St014";
BA_ "GenSigTimeoutTime_SGW" SG_ 2566907443 BatSts 1000;
BA_ "GenSigTimeoutTime_PCM" SG_ 2566907443 BatSts 1000;
BA_ "GenSigTimeoutTime_MPPxPTFE2" SG_ 2566907443 BatSts 1000;
BA_ "GenSigTimeoutTime_IC_MulticS" SG_ 2566907443 BatSts 1000;
BA_ "GenSigTimeoutTime_IC_MulticII" SG_ 2566907443 BatSts 1000;
BA_ "GenSigTimeoutTime_FMS_FMS5" SG_ 2566907443 BatSts 1000;
BA_ "CI_SigName" SG_ 2566907443 BatSts "Battery Status";
BA_ "CI_SigId" SG_ 2566907443 BatSts 3251;
BA_ "CI_ParId" SG_ 2566907443 BatSts "St011";
BA_ "GenSigTimeoutTime_SGW" SG_ 2566907443 TyrePrs 1000;
BA_ "GenSigTimeoutTime_PCM" SG_ 2566907443 TyrePrs 1000;
BA_ "GenSigTimeoutTime_MPPxPTFE2" SG_ 2566907443 TyrePrs 1000;
BA_ "GenSigTimeoutTime_IC_MulticS" SG_ 2566907443 TyrePrs 1000;
BA_ "GenSigTimeoutTime_IC_MulticII" SG_ 2566907443 TyrePrs 1000;
BA_ "GenSigTimeoutTime_FMS_FMS5" SG_ 2566907443 TyrePrs 1000;
BA_ "CI_SigName" SG_ 2566907443 TyrePrs "Tyre Pressure";
BA_ "CI_SigId" SG_ 2566907443 TyrePrs 3250;
BA_ "CI_ParId" SG_ 2566907443 TyrePrs "St010";
BA_ "GenSigTimeoutTime_SGW" SG_ 2566907443 Tyre_WhId 1000;
BA_ "GenSigTimeoutTime_PCM" SG_ 2566907443 Tyre_WhId 1000;
BA_ "GenSigTimeoutTime_MPPxPTFE2" SG_ 2566907443 Tyre_WhId 1000;
BA_ "GenSigTimeoutTime_IC_MulticS" SG_ 2566907443 Tyre_WhId 1000;
BA_ "GenSigTimeoutTime_IC_MulticII" SG_ 2566907443 Tyre_WhId 1000;
BA_ "GenSigTimeoutTime_FMS_FMS5" SG_ 2566907443 Tyre_WhId 1000;
BA_ "CI_SigName" SG_ 2566907443 Tyre_WhId "Tyre / Wheel Identification";
BA_ "CI_SigId" SG_ 2566907443 Tyre_WhId 3248;
BA_ "CI_ParId" SG_ 2566907443 Tyre_WhId "St008";
BA_ "SigType" SG_ 2566867182 SignifTimeOverlapInUsedDrivActiv 4;
BA_ "GenSigTimeoutTime_SGW" SG_ 2566867182 SignifTimeOverlapInUsedDrivActiv 300000;
BA_ "GenSigTimeoutTime_PCM" SG_ 2566867182 SignifTimeOverlapInUsedDrivActiv 300000;
BA_ "GenSigSendType" SG_ 2566867182 SignifTimeOverlapInUsedDrivActiv 3;
BA_ "CI_SigName" SG_ 2566867182 SignifTimeOverlapInUsedDrivActiv "Significant time overlap in used driver activities";
BA_ "CI_SigId" SG_ 2566867182 SignifTimeOverlapInUsedDrivActiv 13145;
BA_ "CI_ParId" SG_ 2566867182 SignifTimeOverlapInUsedDrivActiv "V075";
BA_ "SigType" SG_ 2566867182 MultiManningCurShift 4;
BA_ "GenSigTimeoutTime_SGW" SG_ 2566867182 MultiManningCurShift 300000;
BA_ "GenSigTimeoutTime_PCM" SG_ 2566867182 MultiManningCurShift 300000;
BA_ "GenSigSendType" SG_ 2566867182 MultiManningCurShift 3;
BA_ "CI_SigName" SG_ 2566867182 MultiManningCurShift "Multi-manning for the current shift";
BA_ "CI_SigId" SG_ 2566867182 MultiManningCurShift 13144;
BA_ "CI_ParId" SG_ 2566867182 MultiManningCurShift "V074";
BA_ "SigType" SG_ 2566867182 WeekRestPerCalcEna 4;
BA_ "GenSigTimeoutTime_SGW" SG_ 2566867182 WeekRestPerCalcEna 300000;
BA_ "GenSigTimeoutTime_PCM" SG_ 2566867182 WeekRestPerCalcEna 300000;
BA_ "GenSigSendType" SG_ 2566867182 WeekRestPerCalcEna 3;
BA_ "CI_SigName" SG_ 2566867182 WeekRestPerCalcEna "Weekly rest periods calculation enabled";
BA_ "CI_SigId" SG_ 2566867182 WeekRestPerCalcEna 13143;
BA_ "CI_ParId" SG_ 2566867182 WeekRestPerCalcEna "V073";
BA_ "SigType" SG_ 2566867182 NoSuffDataOnTheDrivCard 4;
BA_ "GenSigTimeoutTime_SGW" SG_ 2566867182 NoSuffDataOnTheDrivCard 300000;
BA_ "GenSigTimeoutTime_PCM" SG_ 2566867182 NoSuffDataOnTheDrivCard 300000;
BA_ "GenSigSendType" SG_ 2566867182 NoSuffDataOnTheDrivCard 3;
BA_ "CI_SigName" SG_ 2566867182 NoSuffDataOnTheDrivCard "No sufficient data on the driver card";
BA_ "CI_SigId" SG_ 2566867182 NoSuffDataOnTheDrivCard 13142;
BA_ "CI_ParId" SG_ 2566867182 NoSuffDataOnTheDrivCard "V072";
BA_ "SigType" SG_ 2566867182 UnknownPer 4;
BA_ "GenSigTimeoutTime_SGW" SG_ 2566867182 UnknownPer 300000;
BA_ "GenSigTimeoutTime_PCM" SG_ 2566867182 UnknownPer 300000;
BA_ "GenSigSendType" SG_ 2566867182 UnknownPer 3;
BA_ "CI_SigName" SG_ 2566867182 UnknownPer "Unknown periods";
BA_ "CI_SigId" SG_ 2566867182 UnknownPer 13141;
BA_ "CI_ParId" SG_ 2566867182 UnknownPer "V071";
BA_ "GenSigTimeoutTime_SGW" SG_ 2566867182 RemReducDayRestPer 300000;
BA_ "GenSigTimeoutTime_PCM" SG_ 2566867182 RemReducDayRestPer 300000;
BA_ "GenSigSendType" SG_ 2566867182 RemReducDayRestPer 3;
BA_ "CI_SigName" SG_ 2566867182 RemReducDayRestPer "Remaining reduced daily rest periods";
BA_ "CI_SigId" SG_ 2566867182 RemReducDayRestPer 13140;
BA_ "CI_ParId" SG_ 2566867182 RemReducDayRestPer "V070";
BA_ "GenSigTimeoutTime_SGW" SG_ 2566867182 Rem10HDrivTimes 300000;
BA_ "GenSigTimeoutTime_PCM" SG_ 2566867182 Rem10HDrivTimes 300000;
BA_ "GenSigSendType" SG_ 2566867182 Rem10HDrivTimes 3;
BA_ "CI_SigName" SG_ 2566867182 Rem10HDrivTimes "Remaining 10 h driving times";
BA_ "CI_SigId" SG_ 2566867182 Rem10HDrivTimes 13139;
BA_ "CI_ParId" SG_ 2566867182 Rem10HDrivTimes "V069";
BA_ "SigType" SG_ 2566867182 OpenCompIn2ndWeekBefLast 1;
BA_ "GenSigTimeoutTime_SGW" SG_ 2566867182 OpenCompIn2ndWeekBefLast 300000;
BA_ "GenSigTimeoutTime_PCM" SG_ 2566867182 OpenCompIn2ndWeekBefLast 300000;
BA_ "GenSigSendType" SG_ 2566867182 OpenCompIn2ndWeekBefLast 3;
BA_ "CI_SigName" SG_ 2566867182 OpenCompIn2ndWeekBefLast "Open compensation in the 2nd week before last";
BA_ "CI_SigId" SG_ 2566867182 OpenCompIn2ndWeekBefLast 13138;
BA_ "CI_ParId" SG_ 2566867182 OpenCompIn2ndWeekBefLast "V067";
BA_ "SigType" SG_ 2566867182 OpenCompInWeekBefLast 1;
BA_ "GenSigTimeoutTime_SGW" SG_ 2566867182 OpenCompInWeekBefLast 300000;
BA_ "GenSigTimeoutTime_PCM" SG_ 2566867182 OpenCompInWeekBefLast 300000;
BA_ "GenSigSendType" SG_ 2566867182 OpenCompInWeekBefLast 3;
BA_ "CI_SigName" SG_ 2566867182 OpenCompInWeekBefLast "Open compensation in the week before last";
BA_ "CI_SigId" SG_ 2566867182 OpenCompInWeekBefLast 13137;
BA_ "CI_ParId" SG_ 2566867182 OpenCompInWeekBefLast "V066";
BA_ "SigType" SG_ 2566867182 OpenCompInLw 1;
BA_ "GenSigTimeoutTime_SGW" SG_ 2566867182 OpenCompInLw 300000;
BA_ "GenSigTimeoutTime_PCM" SG_ 2566867182 OpenCompInLw 300000;
BA_ "GenSigSendType" SG_ 2566867182 OpenCompInLw 3;
BA_ "CI_SigName" SG_ 2566867182 OpenCompInLw "Open compensation in the last week";
BA_ "CI_SigId" SG_ 2566867182 OpenCompInLw 13136;
BA_ "CI_ParId" SG_ 2566867182 OpenCompInLw "V065";
BA_ "SigType" SG_ 2566867182 DurOfNwlyRestPer 1;
BA_ "GenSigTimeoutTime_SGW" SG_ 2566867182 DurOfNwlyRestPer 300000;
BA_ "GenSigTimeoutTime_PCM" SG_ 2566867182 DurOfNwlyRestPer 300000;
BA_ "GenSigSendType" SG_ 2566867182 DurOfNwlyRestPer 3;
BA_ "CI_SigName" SG_ 2566867182 DurOfNwlyRestPer "Duration of next weekly rest period";
BA_ "CI_SigId" SG_ 2566867182 DurOfNwlyRestPer 13135;
BA_ "CI_ParId" SG_ 2566867182 DurOfNwlyRestPer "V064";
BA_ "SigType" SG_ 2566867182 RemTimeTillNwlyRestPer 1;
BA_ "GenSigTimeoutTime_SGW" SG_ 2566867182 RemTimeTillNwlyRestPer 300000;
BA_ "GenSigTimeoutTime_PCM" SG_ 2566867182 RemTimeTillNwlyRestPer 300000;
BA_ "GenSigSendType" SG_ 2566867182 RemTimeTillNwlyRestPer 3;
BA_ "CI_SigName" SG_ 2566867182 RemTimeTillNwlyRestPer "Remaining time till next weekly rest period";
BA_ "CI_SigId" SG_ 2566867182 RemTimeTillNwlyRestPer 13134;
BA_ "CI_ParId" SG_ 2566867182 RemTimeTillNwlyRestPer "V063";
BA_ "SigType" SG_ 2566867182 RemDrivTimeOfCw 1;
BA_ "GenSigTimeoutTime_SGW" SG_ 2566867182 RemDrivTimeOfCw 300000;
BA_ "GenSigTimeoutTime_PCM" SG_ 2566867182 RemDrivTimeOfCw 300000;
BA_ "GenSigSendType" SG_ 2566867182 RemDrivTimeOfCw 3;
BA_ "CI_SigName" SG_ 2566867182 RemDrivTimeOfCw "Remaining driving time of current week";
BA_ "CI_SigId" SG_ 2566867182 RemDrivTimeOfCw 13133;
BA_ "CI_ParId" SG_ 2566867182 RemDrivTimeOfCw "V062";
BA_ "SigType" SG_ 2566867182 DurOfNextDayRestPer 1;
BA_ "GenSigTimeoutTime_SGW" SG_ 2566867182 DurOfNextDayRestPer 300000;
BA_ "GenSigTimeoutTime_PCM" SG_ 2566867182 DurOfNextDayRestPer 300000;
BA_ "GenSigSendType" SG_ 2566867182 DurOfNextDayRestPer 3;
BA_ "CI_SigName" SG_ 2566867182 DurOfNextDayRestPer "Duration of next daily rest period";
BA_ "CI_SigId" SG_ 2566867182 DurOfNextDayRestPer 13132;
BA_ "CI_ParId" SG_ 2566867182 DurOfNextDayRestPer "V061";
BA_ "SigType" SG_ 2566867182 RemTimeTillNextDayRestPer 1;
BA_ "GenSigTimeoutTime_SGW" SG_ 2566867182 RemTimeTillNextDayRestPer 300000;
BA_ "GenSigTimeoutTime_PCM" SG_ 2566867182 RemTimeTillNextDayRestPer 300000;
BA_ "GenSigSendType" SG_ 2566867182 RemTimeTillNextDayRestPer 3;
BA_ "CI_SigName" SG_ 2566867182 RemTimeTillNextDayRestPer "Remaining time till next daily rest period";
BA_ "CI_SigId" SG_ 2566867182 RemTimeTillNextDayRestPer 13131;
BA_ "CI_ParId" SG_ 2566867182 RemTimeTillNextDayRestPer "V060";
BA_ "SigType" SG_ 2566867182 RemCurDayDrivTime 1;
BA_ "GenSigTimeoutTime_SGW" SG_ 2566867182 RemCurDayDrivTime 300000;
BA_ "GenSigTimeoutTime_PCM" SG_ 2566867182 RemCurDayDrivTime 300000;
BA_ "GenSigSendType" SG_ 2566867182 RemCurDayDrivTime 3;
BA_ "CI_SigName" SG_ 2566867182 RemCurDayDrivTime "Remaining current daily driving time";
BA_ "CI_SigId" SG_ 2566867182 RemCurDayDrivTime 13130;
BA_ "CI_ParId" SG_ 2566867182 RemCurDayDrivTime "V059";
BA_ "SigType" SG_ 2566867182 DurOfNextDrivPer 1;
BA_ "GenSigTimeoutTime_SGW" SG_ 2566867182 DurOfNextDrivPer 300000;
BA_ "GenSigTimeoutTime_PCM" SG_ 2566867182 DurOfNextDrivPer 300000;
BA_ "GenSigSendType" SG_ 2566867182 DurOfNextDrivPer 3;
BA_ "CI_SigName" SG_ 2566867182 DurOfNextDrivPer "Duration of next driving period ";
BA_ "CI_SigId" SG_ 2566867182 DurOfNextDrivPer 13129;
BA_ "CI_ParId" SG_ 2566867182 DurOfNextDrivPer "V058";
BA_ "SigType" SG_ 2566867182 TimeBefStartOfNextDrivPer 1;
BA_ "GenSigTimeoutTime_SGW" SG_ 2566867182 TimeBefStartOfNextDrivPer 300000;
BA_ "GenSigTimeoutTime_PCM" SG_ 2566867182 TimeBefStartOfNextDrivPer 300000;
BA_ "GenSigSendType" SG_ 2566867182 TimeBefStartOfNextDrivPer 3;
BA_ "CI_SigName" SG_ 2566867182 TimeBefStartOfNextDrivPer "Time before start of next driving period";
BA_ "CI_SigId" SG_ 2566867182 TimeBefStartOfNextDrivPer 13128;
BA_ "CI_ParId" SG_ 2566867182 TimeBefStartOfNextDrivPer "V057";
BA_ "SigType" SG_ 2566867182 RemDurOfCurBreak_Rest 1;
BA_ "GenSigTimeoutTime_SGW" SG_ 2566867182 RemDurOfCurBreak_Rest 300000;
BA_ "GenSigTimeoutTime_PCM" SG_ 2566867182 RemDurOfCurBreak_Rest 300000;
BA_ "GenSigSendType" SG_ 2566867182 RemDurOfCurBreak_Rest 3;
BA_ "CI_SigName" SG_ 2566867182 RemDurOfCurBreak_Rest "Remaining duration of current break/rest";
BA_ "CI_SigId" SG_ 2566867182 RemDurOfCurBreak_Rest 13127;
BA_ "CI_ParId" SG_ 2566867182 RemDurOfCurBreak_Rest "V056";
BA_ "SigType" SG_ 2566867182 DurOfNextRest_Break 1;
BA_ "GenSigTimeoutTime_SGW" SG_ 2566867182 DurOfNextRest_Break 300000;
BA_ "GenSigTimeoutTime_PCM" SG_ 2566867182 DurOfNextRest_Break 300000;
BA_ "GenSigSendType" SG_ 2566867182 DurOfNextRest_Break 3;
BA_ "CI_SigName" SG_ 2566867182 DurOfNextRest_Break "Duration of next rest/break";
BA_ "CI_SigId" SG_ 2566867182 DurOfNextRest_Break 13126;
BA_ "CI_ParId" SG_ 2566867182 DurOfNextRest_Break "V055";
BA_ "SigType" SG_ 2566867182 RemTimeTillNextRest_Break 1;
BA_ "GenSigTimeoutTime_SGW" SG_ 2566867182 RemTimeTillNextRest_Break 300000;
BA_ "GenSigTimeoutTime_PCM" SG_ 2566867182 RemTimeTillNextRest_Break 300000;
BA_ "GenSigSendType" SG_ 2566867182 RemTimeTillNextRest_Break 3;
BA_ "CI_SigName" SG_ 2566867182 RemTimeTillNextRest_Break "Remaining time till next rest/break";
BA_ "CI_SigId" SG_ 2566867182 RemTimeTillNextRest_Break 13125;
BA_ "CI_ParId" SG_ 2566867182 RemTimeTillNextRest_Break "V054";
BA_ "SigType" SG_ 2566867182 RemCurDrivTime 1;
BA_ "GenSigTimeoutTime_SGW" SG_ 2566867182 RemCurDrivTime 300000;
BA_ "GenSigTimeoutTime_PCM" SG_ 2566867182 RemCurDrivTime 300000;
BA_ "GenSigSendType" SG_ 2566867182 RemCurDrivTime 3;
BA_ "CI_SigName" SG_ 2566867182 RemCurDrivTime "Remaining current driving time";
BA_ "CI_SigId" SG_ 2566867182 RemCurDrivTime 13124;
BA_ "CI_ParId" SG_ 2566867182 RemCurDrivTime "V053";
BA_ "SigType" SG_ 2566867438 NextBreak_RestExByAComp 4;
BA_ "GenSigTimeoutTime_SGW" SG_ 2566867438 NextBreak_RestExByAComp 300000;
BA_ "GenSigTimeoutTime_PCM" SG_ 2566867438 NextBreak_RestExByAComp 300000;
BA_ "GenSigSendType" SG_ 2566867438 NextBreak_RestExByAComp 3;
BA_ "CI_SigName" SG_ 2566867438 NextBreak_RestExByAComp "Next break/rest extended by a compensation";
BA_ "CI_SigId" SG_ 2566867438 NextBreak_RestExByAComp 13149;
BA_ "CI_ParId" SG_ 2566867438 NextBreak_RestExByAComp "V079";
BA_ "GenSigTimeoutTime_SGW" SG_ 2566867438 TypeOfNextBreak_Rest 300000;
BA_ "GenSigTimeoutTime_PCM" SG_ 2566867438 TypeOfNextBreak_Rest 300000;
BA_ "GenSigSendType" SG_ 2566867438 TypeOfNextBreak_Rest 3;
BA_ "CI_SigName" SG_ 2566867438 TypeOfNextBreak_Rest "Type of next break/rest";
BA_ "CI_SigId" SG_ 2566867438 TypeOfNextBreak_Rest 13148;
BA_ "CI_ParId" SG_ 2566867438 TypeOfNextBreak_Rest "V078";
BA_ "SigType" SG_ 2566867438 RemDrivTimeTillNwlyRestPer 1;
BA_ "GenSigTimeoutTime_SGW" SG_ 2566867438 RemDrivTimeTillNwlyRestPer 300000;
BA_ "GenSigTimeoutTime_PCM" SG_ 2566867438 RemDrivTimeTillNwlyRestPer 300000;
BA_ "GenSigSendType" SG_ 2566867438 RemDrivTimeTillNwlyRestPer 3;
BA_ "CI_SigName" SG_ 2566867438 RemDrivTimeTillNwlyRestPer "Remaining driving time till next weekly rest period";
BA_ "CI_SigId" SG_ 2566867438 RemDrivTimeTillNwlyRestPer 13147;
BA_ "CI_ParId" SG_ 2566867438 RemDrivTimeTillNwlyRestPer "V076";
BA_ "SigType" SG_ 2566867694 CwWorkTime 1;
BA_ "GenSigTimeoutTime_SGW" SG_ 2566867694 CwWorkTime 300000;
BA_ "GenSigTimeoutTime_PCM" SG_ 2566867694 CwWorkTime 300000;
BA_ "GenSigSendType" SG_ 2566867694 CwWorkTime 3;
BA_ "CI_SigName" SG_ 2566867694 CwWorkTime "Current week working time";
BA_ "CI_SigId" SG_ 2566867694 CwWorkTime 793;
BA_ "CI_ParId" SG_ 2566867694 CwWorkTime "V094";
BA_ "SigType" SG_ 2566867694 CurDayWorkTime 1;
BA_ "GenSigTimeoutTime_SGW" SG_ 2566867694 CurDayWorkTime 300000;
BA_ "GenSigTimeoutTime_PCM" SG_ 2566867694 CurDayWorkTime 300000;
BA_ "GenSigSendType" SG_ 2566867694 CurDayWorkTime 3;
BA_ "CI_SigName" SG_ 2566867694 CurDayWorkTime "Current daily working time";
BA_ "CI_SigId" SG_ 2566867694 CurDayWorkTime 792;
BA_ "CI_ParId" SG_ 2566867694 CurDayWorkTime "V093";
BA_ "GenSigTimeoutTime_SGW" SG_ 2566867694 LwAssignReducWeekRestPer 300000;
BA_ "GenSigTimeoutTime_PCM" SG_ 2566867694 LwAssignReducWeekRestPer 300000;
BA_ "GenSigSendType" SG_ 2566867694 LwAssignReducWeekRestPer 3;
BA_ "CI_SigName" SG_ 2566867694 LwAssignReducWeekRestPer "Last Week - Assigned reduced weekly rest periods";
BA_ "CI_SigId" SG_ 2566867694 LwAssignReducWeekRestPer 791;
BA_ "CI_ParId" SG_ 2566867694 LwAssignReducWeekRestPer "V092";
BA_ "GenSigTimeoutTime_SGW" SG_ 2566867694 LwAssignRegWeekRestPer 300000;
BA_ "GenSigTimeoutTime_PCM" SG_ 2566867694 LwAssignRegWeekRestPer 300000;
BA_ "GenSigSendType" SG_ 2566867694 LwAssignRegWeekRestPer 3;
BA_ "CI_SigName" SG_ 2566867694 LwAssignRegWeekRestPer "Last Week - Assigned regular weekly rest periods";
BA_ "CI_SigId" SG_ 2566867694 LwAssignRegWeekRestPer 790;
BA_ "CI_ParId" SG_ 2566867694 LwAssignRegWeekRestPer "V091";
BA_ "GenSigTimeoutTime_SGW" SG_ 2566867694 CwNumOfAssignReducWeekRestPer 300000;
BA_ "GenSigTimeoutTime_PCM" SG_ 2566867694 CwNumOfAssignReducWeekRestPer 300000;
BA_ "GenSigSendType" SG_ 2566867694 CwNumOfAssignReducWeekRestPer 3;
BA_ "CI_SigName" SG_ 2566867694 CwNumOfAssignReducWeekRestPer "Current Week - Number of assigned reduced weekly rest periods";
BA_ "CI_SigId" SG_ 2566867694 CwNumOfAssignReducWeekRestPer 789;
BA_ "CI_ParId" SG_ 2566867694 CwNumOfAssignReducWeekRestPer "V089";
BA_ "GenSigTimeoutTime_SGW" SG_ 2566867694 CwNumOfAssignRegWeekRestPer 300000;
BA_ "GenSigTimeoutTime_PCM" SG_ 2566867694 CwNumOfAssignRegWeekRestPer 300000;
BA_ "GenSigSendType" SG_ 2566867694 CwNumOfAssignRegWeekRestPer 3;
BA_ "CI_SigName" SG_ 2566867694 CwNumOfAssignRegWeekRestPer "Current Week - Number of assigned regular weekly rest periods";
BA_ "CI_SigId" SG_ 2566867694 CwNumOfAssignRegWeekRestPer 788;
BA_ "CI_ParId" SG_ 2566867694 CwNumOfAssignRegWeekRestPer "V088";
BA_ "SigType" SG_ 2566867694 DurOfCurRestPer 1;
BA_ "GenSigTimeoutTime_SGW" SG_ 2566867694 DurOfCurRestPer 300000;
BA_ "GenSigTimeoutTime_PCM" SG_ 2566867694 DurOfCurRestPer 300000;
BA_ "GenSigSendType" SG_ 2566867694 DurOfCurRestPer 3;
BA_ "CI_SigName" SG_ 2566867694 DurOfCurRestPer "Duration of current rest period";
BA_ "CI_SigId" SG_ 2566867694 DurOfCurRestPer 787;
BA_ "CI_ParId" SG_ 2566867694 DurOfCurRestPer "V086";
BA_ "SigType" SG_ 2566867694 DurOfCurRest 1;
BA_ "GenSigTimeoutTime_SGW" SG_ 2566867694 DurOfCurRest 300000;
BA_ "GenSigTimeoutTime_PCM" SG_ 2566867694 DurOfCurRest 300000;
BA_ "GenSigSendType" SG_ 2566867694 DurOfCurRest 3;
BA_ "CI_SigName" SG_ 2566867694 DurOfCurRest "Duration of current rest";
BA_ "CI_SigId" SG_ 2566867694 DurOfCurRest 786;
BA_ "CI_ParId" SG_ 2566867694 DurOfCurRest "V085";
BA_ "SigType" SG_ 2566867694 CumulBreakTime 1;
BA_ "GenSigTimeoutTime_SGW" SG_ 2566867694 CumulBreakTime 300000;
BA_ "GenSigTimeoutTime_PCM" SG_ 2566867694 CumulBreakTime 300000;
BA_ "GenSigSendType" SG_ 2566867694 CumulBreakTime 3;
BA_ "CI_SigName" SG_ 2566867694 CumulBreakTime "Cumulative break time";
BA_ "CI_SigId" SG_ 2566867694 CumulBreakTime 785;
BA_ "CI_ParId" SG_ 2566867694 CumulBreakTime "V084";
BA_ "SigType" SG_ 2566867694 WeekDrivTime 1;
BA_ "GenSigTimeoutTime_SGW" SG_ 2566867694 WeekDrivTime 300000;
BA_ "GenSigTimeoutTime_PCM" SG_ 2566867694 WeekDrivTime 300000;
BA_ "GenSigSendType" SG_ 2566867694 WeekDrivTime 3;
BA_ "CI_SigName" SG_ 2566867694 WeekDrivTime "Weekly driving time";
BA_ "CI_SigId" SG_ 2566867694 WeekDrivTime 784;
BA_ "CI_ParId" SG_ 2566867694 WeekDrivTime "V083";
BA_ "SigType" SG_ 2566867694 TwoWeeksDrivTime 1;
BA_ "GenSigTimeoutTime_SGW" SG_ 2566867694 TwoWeeksDrivTime 300000;
BA_ "GenSigTimeoutTime_PCM" SG_ 2566867694 TwoWeeksDrivTime 300000;
BA_ "GenSigSendType" SG_ 2566867694 TwoWeeksDrivTime 3;
BA_ "CI_SigName" SG_ 2566867694 TwoWeeksDrivTime "Two weeks driving time";
BA_ "CI_SigId" SG_ 2566867694 TwoWeeksDrivTime 783;
BA_ "CI_ParId" SG_ 2566867694 TwoWeeksDrivTime "V082";
BA_ "SigType" SG_ 2566867694 DayDrivTime_FF4AEE 1;
BA_ "GenSigTimeoutTime_SGW" SG_ 2566867694 DayDrivTime_FF4AEE 300000;
BA_ "GenSigTimeoutTime_PCM" SG_ 2566867694 DayDrivTime_FF4AEE 300000;
BA_ "GenSigSendType" SG_ 2566867694 DayDrivTime_FF4AEE 3;
BA_ "CI_SigName" SG_ 2566867694 DayDrivTime_FF4AEE "Daily driving time";
BA_ "CI_SigId" SG_ 2566867694 DayDrivTime_FF4AEE 782;
BA_ "CI_ParId" SG_ 2566867694 DayDrivTime_FF4AEE "V081";
BA_ "SigType" SG_ 2566867694 ContDrivTime 1;
BA_ "GenSigTimeoutTime_SGW" SG_ 2566867694 ContDrivTime 300000;
BA_ "GenSigTimeoutTime_PCM" SG_ 2566867694 ContDrivTime 300000;
BA_ "GenSigSendType" SG_ 2566867694 ContDrivTime 3;
BA_ "CI_SigName" SG_ 2566867694 ContDrivTime "Continuous driving time";
BA_ "CI_SigId" SG_ 2566867694 ContDrivTime 781;
BA_ "CI_ParId" SG_ 2566867694 ContDrivTime "V080";
BA_ "SPN" SG_ 2566892311 MsgCks_FFAB17 4207;
BA_ "GenSigTimeoutTime_SGW" SG_ 2566892311 MsgCks_FFAB17 5000;
BA_ "GenSigTimeoutTime_PCM" SG_ 2566892311 MsgCks_FFAB17 5000;
BA_ "GenSigTimeoutTime_ADCU" SG_ 2566892311 MsgCks_FFAB17 5000;
BA_ "GenSigSendType" SG_ 2566892311 MsgCks_FFAB17 3;
BA_ "CI_SigName" SG_ 2566892311 MsgCks_FFAB17 "Message Checksum";
BA_ "CI_SigId" SG_ 2566892311 MsgCks_FFAB17 2890;
BA_ "CI_ParId" SG_ 2566892311 MsgCks_FFAB17 "4207";
BA_ "SPN" SG_ 2566892311 MsgCnt_FFAB17 4206;
BA_ "GenSigTimeoutTime_SGW" SG_ 2566892311 MsgCnt_FFAB17 5000;
BA_ "GenSigTimeoutTime_PCM" SG_ 2566892311 MsgCnt_FFAB17 5000;
BA_ "GenSigTimeoutTime_ADCU" SG_ 2566892311 MsgCnt_FFAB17 5000;
BA_ "GenSigSendType" SG_ 2566892311 MsgCnt_FFAB17 3;
BA_ "CI_SigName" SG_ 2566892311 MsgCnt_FFAB17 "Message Counter";
BA_ "CI_SigId" SG_ 2566892311 MsgCnt_FFAB17 2889;
BA_ "CI_ParId" SG_ 2566892311 MsgCnt_FFAB17 "4206";
BA_ "SigType" SG_ 2566892311 RevWarnEn 4;
BA_ "GenSigTimeoutTime_SGW" SG_ 2566892311 RevWarnEn 5000;
BA_ "GenSigTimeoutTime_PCM" SG_ 2566892311 RevWarnEn 5000;
BA_ "GenSigTimeoutTime_ADCU" SG_ 2566892311 RevWarnEn 5000;
BA_ "GenSigSendType" SG_ 2566892311 RevWarnEn 3;
BA_ "CI_SigName" SG_ 2566892311 RevWarnEn "Reverse Detection Warning Enable";
BA_ "CI_SigId" SG_ 2566892311 RevWarnEn 2888;
BA_ "CI_ParId" SG_ 2566892311 RevWarnEn "IS972";
BA_ "SigType" SG_ 2566892311 MoisDrvFuncEn 4;
BA_ "GenSigTimeoutTime_SGW" SG_ 2566892311 MoisDrvFuncEn 5000;
BA_ "GenSigTimeoutTime_PCM" SG_ 2566892311 MoisDrvFuncEn 5000;
BA_ "GenSigTimeoutTime_ADCU" SG_ 2566892311 MoisDrvFuncEn 5000;
BA_ "GenSigSendType" SG_ 2566892311 MoisDrvFuncEn 3;
BA_ "CI_SigName" SG_ 2566892311 MoisDrvFuncEn "Moving Off Information System Driver Function Enable";
BA_ "CI_SigId" SG_ 2566892311 MoisDrvFuncEn 2887;
BA_ "CI_ParId" SG_ 2566892311 MoisDrvFuncEn "IS971";
BA_ "SigType" SG_ 2566892311 BsisWarnEn 4;
BA_ "GenSigTimeoutTime_SGW" SG_ 2566892311 BsisWarnEn 5000;
BA_ "GenSigTimeoutTime_PCM" SG_ 2566892311 BsisWarnEn 5000;
BA_ "GenSigTimeoutTime_BCM_NBM" SG_ 2566892311 BsisWarnEn 5000;
BA_ "GenSigTimeoutTime_ADCU" SG_ 2566892311 BsisWarnEn 5000;
BA_ "GenSigSendType" SG_ 2566892311 BsisWarnEn 3;
BA_ "CI_SigName" SG_ 2566892311 BsisWarnEn "Blind Spot Information System Warning Enable";
BA_ "CI_SigId" SG_ 2566892311 BsisWarnEn 2886;
BA_ "CI_ParId" SG_ 2566892311 BsisWarnEn "IS970";
BA_ "SigType" SG_ 2566892311 MoisWarnEn 4;
BA_ "GenSigTimeoutTime_SGW" SG_ 2566892311 MoisWarnEn 5000;
BA_ "GenSigTimeoutTime_PCM" SG_ 2566892311 MoisWarnEn 5000;
BA_ "GenSigTimeoutTime_ADCU" SG_ 2566892311 MoisWarnEn 5000;
BA_ "GenSigSendType" SG_ 2566892311 MoisWarnEn 3;
BA_ "CI_SigName" SG_ 2566892311 MoisWarnEn "Moving Off Information System Warning Enable";
BA_ "CI_SigId" SG_ 2566892311 MoisWarnEn 2885;
BA_ "CI_ParId" SG_ 2566892311 MoisWarnEn "IS969";
BA_ "SPN" SG_ 2566892446 MsgCks_FFAB9E 4207;
BA_ "GenSigTimeoutTime_SGW" SG_ 2566892446 MsgCks_FFAB9E 5000;
BA_ "GenSigTimeoutTime_PCM" SG_ 2566892446 MsgCks_FFAB9E 5000;
BA_ "GenSigTimeoutTime_IC_MulticS" SG_ 2566892446 MsgCks_FFAB9E 5000;
BA_ "GenSigTimeoutTime_IC_MulticII" SG_ 2566892446 MsgCks_FFAB9E 5000;
BA_ "GenSigSendType" SG_ 2566892446 MsgCks_FFAB9E 3;
BA_ "CI_SigName" SG_ 2566892446 MsgCks_FFAB9E "Message Checksum";
BA_ "CI_SigId" SG_ 2566892446 MsgCks_FFAB9E 2883;
BA_ "CI_ParId" SG_ 2566892446 MsgCks_FFAB9E "4207";
BA_ "SPN" SG_ 2566892446 MsgCnt_FFAB9E 4206;
BA_ "GenSigTimeoutTime_SGW" SG_ 2566892446 MsgCnt_FFAB9E 5000;
BA_ "GenSigTimeoutTime_PCM" SG_ 2566892446 MsgCnt_FFAB9E 5000;
BA_ "GenSigTimeoutTime_IC_MulticS" SG_ 2566892446 MsgCnt_FFAB9E 5000;
BA_ "GenSigTimeoutTime_IC_MulticII" SG_ 2566892446 MsgCnt_FFAB9E 5000;
BA_ "GenSigSendType" SG_ 2566892446 MsgCnt_FFAB9E 3;
BA_ "CI_SigName" SG_ 2566892446 MsgCnt_FFAB9E "Message Counter";
BA_ "CI_SigId" SG_ 2566892446 MsgCnt_FFAB9E 2882;
BA_ "CI_ParId" SG_ 2566892446 MsgCnt_FFAB9E "4206";
BA_ "GenSigTimeoutTime_SGW" SG_ 2566892446 BsisRightWarnLvl 5000;
BA_ "GenSigTimeoutTime_PCM" SG_ 2566892446 BsisRightWarnLvl 5000;
BA_ "GenSigTimeoutTime_MCSL" SG_ 2566892446 BsisRightWarnLvl 5000;
BA_ "GenSigTimeoutTime_IC_MulticS" SG_ 2566892446 BsisRightWarnLvl 5000;
BA_ "GenSigTimeoutTime_IC_MulticII" SG_ 2566892446 BsisRightWarnLvl 5000;
BA_ "GenSigTimeoutTime_BCM_NBM" SG_ 2566892446 BsisRightWarnLvl 5000;
BA_ "GenSigSendType" SG_ 2566892446 BsisRightWarnLvl 3;
BA_ "CI_SigName" SG_ 2566892446 BsisRightWarnLvl "Blind Spot Information System Right Warning Level";
BA_ "CI_SigId" SG_ 2566892446 BsisRightWarnLvl 2881;
BA_ "CI_ParId" SG_ 2566892446 BsisRightWarnLvl "IS993";
BA_ "GenSigTimeoutTime_SGW" SG_ 2566892446 BsisPlcaDetZone0 5000;
BA_ "GenSigTimeoutTime_PCM" SG_ 2566892446 BsisPlcaDetZone0 5000;
BA_ "GenSigTimeoutTime_IC_MulticS" SG_ 2566892446 BsisPlcaDetZone0 5000;
BA_ "GenSigTimeoutTime_IC_MulticII" SG_ 2566892446 BsisPlcaDetZone0 5000;
BA_ "GenSigSendType" SG_ 2566892446 BsisPlcaDetZone0 3;
BA_ "CI_SigName" SG_ 2566892446 BsisPlcaDetZone0 "BSIS / PLCA Detection Zone 0";
BA_ "CI_SigId" SG_ 2566892446 BsisPlcaDetZone0 2880;
BA_ "CI_ParId" SG_ 2566892446 BsisPlcaDetZone0 "IS992";
BA_ "GenSigTimeoutTime_SGW" SG_ 2566892446 BsisPlcaDetZone1 5000;
BA_ "GenSigTimeoutTime_PCM" SG_ 2566892446 BsisPlcaDetZone1 5000;
BA_ "GenSigTimeoutTime_IC_MulticS" SG_ 2566892446 BsisPlcaDetZone1 5000;
BA_ "GenSigTimeoutTime_IC_MulticII" SG_ 2566892446 BsisPlcaDetZone1 5000;
BA_ "GenSigSendType" SG_ 2566892446 BsisPlcaDetZone1 3;
BA_ "CI_SigName" SG_ 2566892446 BsisPlcaDetZone1 "BSIS / PLCA Detection Zone 1";
BA_ "CI_SigId" SG_ 2566892446 BsisPlcaDetZone1 2879;
BA_ "CI_ParId" SG_ 2566892446 BsisPlcaDetZone1 "IS991";
BA_ "GenSigTimeoutTime_SGW" SG_ 2566892446 BsisLeftWarnLvl 5000;
BA_ "GenSigTimeoutTime_PCM" SG_ 2566892446 BsisLeftWarnLvl 5000;
BA_ "GenSigTimeoutTime_MCSL" SG_ 2566892446 BsisLeftWarnLvl 5000;
BA_ "GenSigTimeoutTime_IC_MulticS" SG_ 2566892446 BsisLeftWarnLvl 5000;
BA_ "GenSigTimeoutTime_IC_MulticII" SG_ 2566892446 BsisLeftWarnLvl 5000;
BA_ "GenSigTimeoutTime_BCM_NBM" SG_ 2566892446 BsisLeftWarnLvl 5000;
BA_ "GenSigSendType" SG_ 2566892446 BsisLeftWarnLvl 3;
BA_ "CI_SigName" SG_ 2566892446 BsisLeftWarnLvl "Blind Spot Information System Left Warning Level";
BA_ "CI_SigId" SG_ 2566892446 BsisLeftWarnLvl 2878;
BA_ "CI_ParId" SG_ 2566892446 BsisLeftWarnLvl "IS968";
BA_ "GenSigTimeoutTime_SGW" SG_ 2566892446 BsisDetObj 5000;
BA_ "GenSigTimeoutTime_PCM" SG_ 2566892446 BsisDetObj 5000;
BA_ "GenSigTimeoutTime_IC_MulticS" SG_ 2566892446 BsisDetObj 5000;
BA_ "GenSigTimeoutTime_IC_MulticII" SG_ 2566892446 BsisDetObj 5000;
BA_ "GenSigSendType" SG_ 2566892446 BsisDetObj 3;
BA_ "CI_SigName" SG_ 2566892446 BsisDetObj "Blind Spot Information System Detection Object";
BA_ "CI_SigId" SG_ 2566892446 BsisDetObj 2877;
BA_ "CI_ParId" SG_ 2566892446 BsisDetObj "IS967";
BA_ "GenSigTimeoutTime_SGW" SG_ 2566892446 BsisPlcaDetZone4 5000;
BA_ "GenSigTimeoutTime_PCM" SG_ 2566892446 BsisPlcaDetZone4 5000;
BA_ "GenSigTimeoutTime_IC_MulticS" SG_ 2566892446 BsisPlcaDetZone4 5000;
BA_ "GenSigTimeoutTime_IC_MulticII" SG_ 2566892446 BsisPlcaDetZone4 5000;
BA_ "GenSigSendType" SG_ 2566892446 BsisPlcaDetZone4 3;
BA_ "CI_SigName" SG_ 2566892446 BsisPlcaDetZone4 "BSIS / PLCA Detection Zone 4";
BA_ "CI_SigId" SG_ 2566892446 BsisPlcaDetZone4 2876;
BA_ "CI_ParId" SG_ 2566892446 BsisPlcaDetZone4 "IS966";
BA_ "GenSigTimeoutTime_SGW" SG_ 2566892446 BsisPlcaDetZone3 5000;
BA_ "GenSigTimeoutTime_PCM" SG_ 2566892446 BsisPlcaDetZone3 5000;
BA_ "GenSigTimeoutTime_IC_MulticS" SG_ 2566892446 BsisPlcaDetZone3 5000;
BA_ "GenSigTimeoutTime_IC_MulticII" SG_ 2566892446 BsisPlcaDetZone3 5000;
BA_ "GenSigSendType" SG_ 2566892446 BsisPlcaDetZone3 3;
BA_ "CI_SigName" SG_ 2566892446 BsisPlcaDetZone3 "BSIS / PLCA Detection Zone 3";
BA_ "CI_SigId" SG_ 2566892446 BsisPlcaDetZone3 2875;
BA_ "CI_ParId" SG_ 2566892446 BsisPlcaDetZone3 "IS965";
BA_ "GenSigTimeoutTime_SGW" SG_ 2566892446 BsisSts 5000;
BA_ "GenSigTimeoutTime_PCM" SG_ 2566892446 BsisSts 5000;
BA_ "GenSigTimeoutTime_IC_MulticS" SG_ 2566892446 BsisSts 5000;
BA_ "GenSigTimeoutTime_IC_MulticII" SG_ 2566892446 BsisSts 5000;
BA_ "GenSigTimeoutTime_BCM_NBM" SG_ 2566892446 BsisSts 5000;
BA_ "GenSigSendType" SG_ 2566892446 BsisSts 3;
BA_ "CI_SigName" SG_ 2566892446 BsisSts "Blind Spot Information System Status";
BA_ "CI_SigId" SG_ 2566892446 BsisSts 2873;
BA_ "CI_ParId" SG_ 2566892446 BsisSts "IS963";
BA_ "GenSigTimeoutTime_SGW" SG_ 2566892446 MoisWarnLvl 5000;
BA_ "GenSigTimeoutTime_PCM" SG_ 2566892446 MoisWarnLvl 5000;
BA_ "GenSigTimeoutTime_IC_MulticS" SG_ 2566892446 MoisWarnLvl 5000;
BA_ "GenSigTimeoutTime_IC_MulticII" SG_ 2566892446 MoisWarnLvl 5000;
BA_ "GenSigSendType" SG_ 2566892446 MoisWarnLvl 3;
BA_ "CI_SigName" SG_ 2566892446 MoisWarnLvl "Moving Off Information System Warning Level";
BA_ "CI_SigId" SG_ 2566892446 MoisWarnLvl 2872;
BA_ "CI_ParId" SG_ 2566892446 MoisWarnLvl "IS962";
BA_ "GenSigTimeoutTime_SGW" SG_ 2566892446 MoisDetObj 5000;
BA_ "GenSigTimeoutTime_PCM" SG_ 2566892446 MoisDetObj 5000;
BA_ "GenSigTimeoutTime_IC_MulticS" SG_ 2566892446 MoisDetObj 5000;
BA_ "GenSigTimeoutTime_IC_MulticII" SG_ 2566892446 MoisDetObj 5000;
BA_ "GenSigSendType" SG_ 2566892446 MoisDetObj 3;
BA_ "CI_SigName" SG_ 2566892446 MoisDetObj "Moving Off Information System DetectionObject";
BA_ "CI_SigId" SG_ 2566892446 MoisDetObj 2871;
BA_ "CI_ParId" SG_ 2566892446 MoisDetObj "IS961";
BA_ "GenSigTimeoutTime_SGW" SG_ 2566892446 MoisDetZone3 5000;
BA_ "GenSigTimeoutTime_PCM" SG_ 2566892446 MoisDetZone3 5000;
BA_ "GenSigTimeoutTime_IC_MulticS" SG_ 2566892446 MoisDetZone3 5000;
BA_ "GenSigTimeoutTime_IC_MulticII" SG_ 2566892446 MoisDetZone3 5000;
BA_ "GenSigSendType" SG_ 2566892446 MoisDetZone3 3;
BA_ "CI_SigName" SG_ 2566892446 MoisDetZone3 "Moving Off Information System Detection Zone 3";
BA_ "CI_SigId" SG_ 2566892446 MoisDetZone3 2870;
BA_ "CI_ParId" SG_ 2566892446 MoisDetZone3 "IS960";
BA_ "GenSigTimeoutTime_SGW" SG_ 2566892446 MoisDetZone2 5000;
BA_ "GenSigTimeoutTime_PCM" SG_ 2566892446 MoisDetZone2 5000;
BA_ "GenSigTimeoutTime_IC_MulticS" SG_ 2566892446 MoisDetZone2 5000;
BA_ "GenSigTimeoutTime_IC_MulticII" SG_ 2566892446 MoisDetZone2 5000;
BA_ "GenSigSendType" SG_ 2566892446 MoisDetZone2 3;
BA_ "CI_SigName" SG_ 2566892446 MoisDetZone2 "Moving Off Information System Detection Zone 2";
BA_ "CI_SigId" SG_ 2566892446 MoisDetZone2 2869;
BA_ "CI_ParId" SG_ 2566892446 MoisDetZone2 "IS959";
BA_ "GenSigTimeoutTime_SGW" SG_ 2566892446 MoisDetZone1 5000;
BA_ "GenSigTimeoutTime_PCM" SG_ 2566892446 MoisDetZone1 5000;
BA_ "GenSigTimeoutTime_IC_MulticS" SG_ 2566892446 MoisDetZone1 5000;
BA_ "GenSigTimeoutTime_IC_MulticII" SG_ 2566892446 MoisDetZone1 5000;
BA_ "GenSigSendType" SG_ 2566892446 MoisDetZone1 3;
BA_ "CI_SigName" SG_ 2566892446 MoisDetZone1 "Moving Off Information System Detection Zone 1";
BA_ "CI_SigId" SG_ 2566892446 MoisDetZone1 2868;
BA_ "CI_ParId" SG_ 2566892446 MoisDetZone1 "IS958";
BA_ "GenSigTimeoutTime_SGW" SG_ 2566892446 MoisSts 5000;
BA_ "GenSigTimeoutTime_PCM" SG_ 2566892446 MoisSts 5000;
BA_ "GenSigTimeoutTime_IC_MulticS" SG_ 2566892446 MoisSts 5000;
BA_ "GenSigTimeoutTime_IC_MulticII" SG_ 2566892446 MoisSts 5000;
BA_ "GenSigSendType" SG_ 2566892446 MoisSts 3;
BA_ "CI_SigName" SG_ 2566892446 MoisSts "Moving Off Information System Status";
BA_ "CI_SigId" SG_ 2566892446 MoisSts 2867;
BA_ "CI_ParId" SG_ 2566892446 MoisSts "IS956";
BA_ "SigType" SG_ 2631855639 TripGrp1 4;
BA_ "SPN" SG_ 2631855639 TripGrp1 988;
BA_ "GenSigTimeoutTime_VMU" SG_ 2631855639 TripGrp1 5000;
BA_ "GenSigTimeoutTime_VCU" SG_ 2631855639 TripGrp1 5000;
BA_ "GenSigTimeoutTime_Tacho_TSU" SG_ 2631855639 TripGrp1 5000;
BA_ "GenSigTimeoutTime_Tacho_MTCO" SG_ 2631855639 TripGrp1 5000;
BA_ "GenSigTimeoutTime_Tacho_DTCO" SG_ 2631855639 TripGrp1 5000;
BA_ "GenSigTimeoutTime_SGW" SG_ 2631855639 TripGrp1 5000;
BA_ "GenSigTimeoutTime_PCM" SG_ 2631855639 TripGrp1 5000;
BA_ "CI_SigName" SG_ 2631855639 TripGrp1 "Trip Group 1";
BA_ "CI_SigId" SG_ 2631855639 TripGrp1 4450;
BA_ "CI_ParId" SG_ 2631855639 TripGrp1 "988";
BA_ "SigType" SG_ 2566847248 HydrRetOilTemp 1;
BA_ "SPN" SG_ 2566847248 HydrRetOilTemp 120;
BA_ "GenSigTimeoutTime_SGW" SG_ 2566847248 HydrRetOilTemp 5000;
BA_ "GenSigTimeoutTime_PCM" SG_ 2566847248 HydrRetOilTemp 5000;
BA_ "GenSigTimeoutTime_FMS_FMS5" SG_ 2566847248 HydrRetOilTemp 5000;
BA_ "GenSigTimeoutTime_FMS_FMS4" SG_ 2566847248 HydrRetOilTemp 5000;
BA_ "GenSigStartValue" SG_ 2566847248 HydrRetOilTemp 40;
BA_ "CI_SigName" SG_ 2566847248 HydrRetOilTemp "Hydraulic Retarder Oil Temperature";
BA_ "CI_SigId" SG_ 2566847248 HydrRetOilTemp 653;
BA_ "CI_ParId" SG_ 2566847248 HydrRetOilTemp "120";
BA_ "SigType" SG_ 2565537539 PgnRqst 6;
BA_ "SPN" SG_ 2565537539 PgnRqst 2540;
BA_ "CI_SigName" SG_ 2565537539 PgnRqst "Parameter Group Number (RQST)";
BA_ "CI_SigId" SG_ 2565537539 PgnRqst 11045;
BA_ "CI_ParId" SG_ 2565537539 PgnRqst "2540";
BA_ "SigType" SG_ 2565485386 PgnRqst_EA334A 6;
BA_ "SPN" SG_ 2565485386 PgnRqst_EA334A 2540;
BA_ "CI_SigName" SG_ 2565485386 PgnRqst_EA334A "Parameter Group Number (RQST)";
BA_ "CI_SigId" SG_ 2565485386 PgnRqst_EA334A 11097;
BA_ "CI_ParId" SG_ 2565485386 PgnRqst_EA334A "2540";
BA_ "SigType" SG_ 2565533258 PgnRqst_EAEE4A 6;
BA_ "SPN" SG_ 2565533258 PgnRqst_EAEE4A 2540;
BA_ "CI_SigName" SG_ 2565533258 PgnRqst_EAEE4A "Parameter Group Number (RQST)";
BA_ "CI_SigId" SG_ 2565533258 PgnRqst_EAEE4A 13166;
BA_ "CI_ParId" SG_ 2565533258 PgnRqst_EAEE4A "2540";
BA_ "GenSigTimeoutTime_SGW" SG_ 2566852224 ContactInconsitency 1000;
BA_ "GenSigTimeoutTime_PCM" SG_ 2566852224 ContactInconsitency 1000;
BA_ "GenSigTimeoutTime_MPPxPTFE2" SG_ 2566852224 ContactInconsitency 1000;
BA_ "GenSigTimeoutTime_BCM_NBM" SG_ 2566852224 ContactInconsitency 1000;
BA_ "CI_SigName" SG_ 2566852224 ContactInconsitency "Contactor Inconsitency";
BA_ "CI_SigId" SG_ 2566852224 ContactInconsitency 3331;
BA_ "CI_ParId" SG_ 2566852224 ContactInconsitency "IB486";
BA_ "SigType" SG_ 2566852224 MajorIsolFault 4;
BA_ "GenSigTimeoutTime_SGW" SG_ 2566852224 MajorIsolFault 1000;
BA_ "GenSigTimeoutTime_PCM" SG_ 2566852224 MajorIsolFault 1000;
BA_ "GenSigTimeoutTime_MPPxPTFE2" SG_ 2566852224 MajorIsolFault 1000;
BA_ "GenSigTimeoutTime_IC_MulticS" SG_ 2566852224 MajorIsolFault 1000;
BA_ "GenSigTimeoutTime_BCM_NBM" SG_ 2566852224 MajorIsolFault 1000;
BA_ "CI_SigName" SG_ 2566852224 MajorIsolFault "Major Isolation Fault";
BA_ "CI_SigId" SG_ 2566852224 MajorIsolFault 3328;
BA_ "CI_ParId" SG_ 2566852224 MajorIsolFault "IB483";
BA_ "SigType" SG_ 2566852224 MinorIsolFault 4;
BA_ "GenSigTimeoutTime_SGW" SG_ 2566852224 MinorIsolFault 1000;
BA_ "GenSigTimeoutTime_PCM" SG_ 2566852224 MinorIsolFault 1000;
BA_ "GenSigTimeoutTime_MPPxPTFE2" SG_ 2566852224 MinorIsolFault 1000;
BA_ "GenSigTimeoutTime_IC_MulticS" SG_ 2566852224 MinorIsolFault 1000;
BA_ "GenSigTimeoutTime_BCM_NBM" SG_ 2566852224 MinorIsolFault 1000;
BA_ "CI_SigName" SG_ 2566852224 MinorIsolFault "Minor Isolation Fault";
BA_ "CI_SigId" SG_ 2566852224 MinorIsolFault 3327;
BA_ "CI_ParId" SG_ 2566852224 MinorIsolFault "IB482";
BA_ "SigType" SG_ 2566852224 PacksOnline_EssSysCap 1;
BA_ "GenSigTimeoutTime_SGW" SG_ 2566852224 PacksOnline_EssSysCap 1000;
BA_ "GenSigTimeoutTime_PCM" SG_ 2566852224 PacksOnline_EssSysCap 1000;
BA_ "GenSigTimeoutTime_MPPxPTFE2" SG_ 2566852224 PacksOnline_EssSysCap 1000;
BA_ "GenSigTimeoutTime_BCM_NBM" SG_ 2566852224 PacksOnline_EssSysCap 1000;
BA_ "CI_SigName" SG_ 2566852224 PacksOnline_EssSysCap "Packs Online / ESS System Capacity";
BA_ "CI_SigId" SG_ 2566852224 PacksOnline_EssSysCap 3324;
BA_ "CI_ParId" SG_ 2566852224 PacksOnline_EssSysCap "IB479";
BA_ "SigType" SG_ 2566852224 EssDisedSoc 1;
BA_ "GenSigTimeoutTime_SGW" SG_ 2566852224 EssDisedSoc 1000;
BA_ "GenSigTimeoutTime_PCM" SG_ 2566852224 EssDisedSoc 1000;
BA_ "GenSigTimeoutTime_MPPxPTFE2" SG_ 2566852224 EssDisedSoc 1000;
BA_ "GenSigTimeoutTime_BCM_NBM" SG_ 2566852224 EssDisedSoc 1000;
BA_ "CI_SigName" SG_ 2566852224 EssDisedSoc "ESS Displayed SoC";
BA_ "CI_SigId" SG_ 2566852224 EssDisedSoc 3323;
BA_ "CI_ParId" SG_ 2566852224 EssDisedSoc "IB478";
BA_ "SigType" SG_ 2566852224 ChgSts 4;
BA_ "GenSigTimeoutTime_SGW" SG_ 2566852224 ChgSts 1000;
BA_ "GenSigTimeoutTime_PCM" SG_ 2566852224 ChgSts 1000;
BA_ "GenSigTimeoutTime_MPPxPTFE2" SG_ 2566852224 ChgSts 1000;
BA_ "GenSigTimeoutTime_BCM_NBM" SG_ 2566852224 ChgSts 1000;
BA_ "CI_SigName" SG_ 2566852224 ChgSts "Charging state";
BA_ "CI_SigId" SG_ 2566852224 ChgSts 3319;
BA_ "CI_ParId" SG_ 2566852224 ChgSts "IB475";
BA_ "SigType" SG_ 2566838813 SwIdField5 8;
BA_ "SPN" SG_ 2566838813 SwIdField5 234;
BA_ "CI_SigName" SG_ 2566838813 SwIdField5 "Software Identification - Field 5";
BA_ "CI_SigId" SG_ 2566838813 SwIdField5 10449;
BA_ "CI_ParId" SG_ 2566838813 SwIdField5 "234";
BA_ "SigType" SG_ 2566838813 SwIdField4 8;
BA_ "SPN" SG_ 2566838813 SwIdField4 234;
BA_ "CI_SigName" SG_ 2566838813 SwIdField4 "Software Identification - Field 4";
BA_ "CI_SigId" SG_ 2566838813 SwIdField4 10448;
BA_ "CI_ParId" SG_ 2566838813 SwIdField4 "234";
BA_ "SigType" SG_ 2566838813 SwIdField3 8;
BA_ "SPN" SG_ 2566838813 SwIdField3 234;
BA_ "CI_SigName" SG_ 2566838813 SwIdField3 "Software Identification - Field 3";
BA_ "CI_SigId" SG_ 2566838813 SwIdField3 10447;
BA_ "CI_ParId" SG_ 2566838813 SwIdField3 "234";
BA_ "SigType" SG_ 2566838813 SwIdField2 8;
BA_ "SPN" SG_ 2566838813 SwIdField2 234;
BA_ "CI_SigName" SG_ 2566838813 SwIdField2 "Software Identification - Field 2";
BA_ "CI_SigId" SG_ 2566838813 SwIdField2 10446;
BA_ "CI_ParId" SG_ 2566838813 SwIdField2 "234";
BA_ "SigType" SG_ 2566838813 SwIdField1 8;
BA_ "SPN" SG_ 2566838813 SwIdField1 234;
BA_ "CI_SigName" SG_ 2566838813 SwIdField1 "Software Identification - Field 1";
BA_ "CI_SigId" SG_ 2566838813 SwIdField1 10445;
BA_ "CI_ParId" SG_ 2566838813 SwIdField1 "234";
BA_ "SigType" SG_ 2566838813 NumOfSwIdFields 1;
BA_ "SPN" SG_ 2566838813 NumOfSwIdFields 965;
BA_ "CI_SigName" SG_ 2566838813 NumOfSwIdFields "Number of Software Identification Fields";
BA_ "CI_SigId" SG_ 2566838813 NumOfSwIdFields 10444;
BA_ "CI_ParId" SG_ 2566838813 NumOfSwIdFields "965";
BA_ "SigType" SG_ 2566838878 SwId 8;
BA_ "SPN" SG_ 2566838878 SwId 234;
BA_ "CI_SigName" SG_ 2566838878 SwId "Software Identification";
BA_ "CI_SigId" SG_ 2566838878 SwId 10435;
BA_ "CI_ParId" SG_ 2566838878 SwId "234";
BA_ "SigType" SG_ 2566838878 NumOfSwIdFields_FEDA5E 1;
BA_ "SPN" SG_ 2566838878 NumOfSwIdFields_FEDA5E 965;
BA_ "CI_SigName" SG_ 2566838878 NumOfSwIdFields_FEDA5E "Number of Software Identification Fields";
BA_ "CI_SigId" SG_ 2566838878 NumOfSwIdFields_FEDA5E 10434;
BA_ "CI_ParId" SG_ 2566838878 NumOfSwIdFields_FEDA5E "965";
BA_ "GenSigTimeoutTime_SGW" SG_ 2566869235 Bms10BatSoh 25000;
BA_ "GenSigTimeoutTime_PCM" SG_ 2566869235 Bms10BatSoh 25000;
BA_ "GenSigTimeoutTime_MPPxPTFE2" SG_ 2566869235 Bms10BatSoh 25000;
BA_ "GenSigTimeoutTime_IC_MulticS" SG_ 2566869235 Bms10BatSoh 25000;
BA_ "GenSigTimeoutTime_FMS_FMS4" SG_ 2566869235 Bms10BatSoh 25000;
BA_ "CI_SigName" SG_ 2566869235 Bms10BatSoh "BMS10 Battery SOH";
BA_ "CI_SigId" SG_ 2566869235 Bms10BatSoh 2919;
BA_ "CI_ParId" SG_ 2566869235 Bms10BatSoh "IB463";
BA_ "GenSigTimeoutTime_SGW" SG_ 2566869235 Bms09BatSoh 25000;
BA_ "GenSigTimeoutTime_PCM" SG_ 2566869235 Bms09BatSoh 25000;
BA_ "GenSigTimeoutTime_MPPxPTFE2" SG_ 2566869235 Bms09BatSoh 25000;
BA_ "GenSigTimeoutTime_IC_MulticS" SG_ 2566869235 Bms09BatSoh 25000;
BA_ "GenSigTimeoutTime_FMS_FMS4" SG_ 2566869235 Bms09BatSoh 25000;
BA_ "CI_SigName" SG_ 2566869235 Bms09BatSoh "BMS09 Battery SOH";
BA_ "CI_SigId" SG_ 2566869235 Bms09BatSoh 2918;
BA_ "CI_ParId" SG_ 2566869235 Bms09BatSoh "IB462";
BA_ "GenSigTimeoutTime_SGW" SG_ 2566869235 Bms08BatSoh 25000;
BA_ "GenSigTimeoutTime_PCM" SG_ 2566869235 Bms08BatSoh 25000;
BA_ "GenSigTimeoutTime_MPPxPTFE2" SG_ 2566869235 Bms08BatSoh 25000;
BA_ "GenSigTimeoutTime_IC_MulticS" SG_ 2566869235 Bms08BatSoh 25000;
BA_ "GenSigTimeoutTime_FMS_FMS4" SG_ 2566869235 Bms08BatSoh 25000;
BA_ "CI_SigName" SG_ 2566869235 Bms08BatSoh "BMS08 Battery SOH";
BA_ "CI_SigId" SG_ 2566869235 Bms08BatSoh 2917;
BA_ "CI_ParId" SG_ 2566869235 Bms08BatSoh "IB461";
BA_ "GenSigTimeoutTime_SGW" SG_ 2566869235 Bms07BatSoh 25000;
BA_ "GenSigTimeoutTime_PCM" SG_ 2566869235 Bms07BatSoh 25000;
BA_ "GenSigTimeoutTime_MPPxPTFE2" SG_ 2566869235 Bms07BatSoh 25000;
BA_ "GenSigTimeoutTime_IC_MulticS" SG_ 2566869235 Bms07BatSoh 25000;
BA_ "GenSigTimeoutTime_FMS_FMS4" SG_ 2566869235 Bms07BatSoh 25000;
BA_ "CI_SigName" SG_ 2566869235 Bms07BatSoh "BMS07 Battery SOH";
BA_ "CI_SigId" SG_ 2566869235 Bms07BatSoh 2916;
BA_ "CI_ParId" SG_ 2566869235 Bms07BatSoh "IB460";
BA_ "GenSigTimeoutTime_SGW" SG_ 2566869235 Bms06BatSoh 25000;
BA_ "GenSigTimeoutTime_PCM" SG_ 2566869235 Bms06BatSoh 25000;
BA_ "GenSigTimeoutTime_MPPxPTFE2" SG_ 2566869235 Bms06BatSoh 25000;
BA_ "GenSigTimeoutTime_IC_MulticS" SG_ 2566869235 Bms06BatSoh 25000;
BA_ "GenSigTimeoutTime_FMS_FMS4" SG_ 2566869235 Bms06BatSoh 25000;
BA_ "CI_SigName" SG_ 2566869235 Bms06BatSoh "BMS06 Battery SOH";
BA_ "CI_SigId" SG_ 2566869235 Bms06BatSoh 2915;
BA_ "CI_ParId" SG_ 2566869235 Bms06BatSoh "IB459";
BA_ "GenSigTimeoutTime_SGW" SG_ 2566869235 Bms05BatSoh 25000;
BA_ "GenSigTimeoutTime_PCM" SG_ 2566869235 Bms05BatSoh 25000;
BA_ "GenSigTimeoutTime_MPPxPTFE2" SG_ 2566869235 Bms05BatSoh 25000;
BA_ "GenSigTimeoutTime_IC_MulticS" SG_ 2566869235 Bms05BatSoh 25000;
BA_ "GenSigTimeoutTime_FMS_FMS4" SG_ 2566869235 Bms05BatSoh 25000;
BA_ "CI_SigName" SG_ 2566869235 Bms05BatSoh "BMS05 Battery SOH";
BA_ "CI_SigId" SG_ 2566869235 Bms05BatSoh 2914;
BA_ "CI_ParId" SG_ 2566869235 Bms05BatSoh "IB458";
BA_ "GenSigTimeoutTime_SGW" SG_ 2566869235 Bms04BatSoh 25000;
BA_ "GenSigTimeoutTime_PCM" SG_ 2566869235 Bms04BatSoh 25000;
BA_ "GenSigTimeoutTime_MPPxPTFE2" SG_ 2566869235 Bms04BatSoh 25000;
BA_ "GenSigTimeoutTime_IC_MulticS" SG_ 2566869235 Bms04BatSoh 25000;
BA_ "GenSigTimeoutTime_FMS_FMS4" SG_ 2566869235 Bms04BatSoh 25000;
BA_ "CI_SigName" SG_ 2566869235 Bms04BatSoh "BMS04 Battery SOH";
BA_ "CI_SigId" SG_ 2566869235 Bms04BatSoh 2913;
BA_ "CI_ParId" SG_ 2566869235 Bms04BatSoh "IB457";
BA_ "GenSigTimeoutTime_SGW" SG_ 2566869235 Bms03BatSoh 25000;
BA_ "GenSigTimeoutTime_PCM" SG_ 2566869235 Bms03BatSoh 25000;
BA_ "GenSigTimeoutTime_MPPxPTFE2" SG_ 2566869235 Bms03BatSoh 25000;
BA_ "GenSigTimeoutTime_IC_MulticS" SG_ 2566869235 Bms03BatSoh 25000;
BA_ "GenSigTimeoutTime_FMS_FMS4" SG_ 2566869235 Bms03BatSoh 25000;
BA_ "CI_SigName" SG_ 2566869235 Bms03BatSoh "BMS03 Battery SOH";
BA_ "CI_SigId" SG_ 2566869235 Bms03BatSoh 2912;
BA_ "CI_ParId" SG_ 2566869235 Bms03BatSoh "IB456";
BA_ "GenSigTimeoutTime_SGW" SG_ 2566869235 Bms02BatSoh 25000;
BA_ "GenSigTimeoutTime_PCM" SG_ 2566869235 Bms02BatSoh 25000;
BA_ "GenSigTimeoutTime_MPPxPTFE2" SG_ 2566869235 Bms02BatSoh 25000;
BA_ "GenSigTimeoutTime_IC_MulticS" SG_ 2566869235 Bms02BatSoh 25000;
BA_ "GenSigTimeoutTime_FMS_FMS4" SG_ 2566869235 Bms02BatSoh 25000;
BA_ "CI_SigName" SG_ 2566869235 Bms02BatSoh "BMS02 Battery SOH";
BA_ "CI_SigId" SG_ 2566869235 Bms02BatSoh 2911;
BA_ "CI_ParId" SG_ 2566869235 Bms02BatSoh "IB455";
BA_ "GenSigTimeoutTime_SGW" SG_ 2566869235 Bms01BatSoh 25000;
BA_ "GenSigTimeoutTime_PCM" SG_ 2566869235 Bms01BatSoh 25000;
BA_ "GenSigTimeoutTime_MPPxPTFE2" SG_ 2566869235 Bms01BatSoh 25000;
BA_ "GenSigTimeoutTime_IC_MulticS" SG_ 2566869235 Bms01BatSoh 25000;
BA_ "GenSigTimeoutTime_FMS_FMS4" SG_ 2566869235 Bms01BatSoh 25000;
BA_ "CI_SigName" SG_ 2566869235 Bms01BatSoh "BMS01 Battery SOH";
BA_ "CI_SigId" SG_ 2566869235 Bms01BatSoh 2910;
BA_ "CI_ParId" SG_ 2566869235 Bms01BatSoh "IB454";
BA_ "GenSigTimeoutTime_SGW" SG_ 2566869491 Bms20BatSoh 25000;
BA_ "GenSigTimeoutTime_PCM" SG_ 2566869491 Bms20BatSoh 25000;
BA_ "GenSigTimeoutTime_MPPxPTFE2" SG_ 2566869491 Bms20BatSoh 25000;
BA_ "GenSigTimeoutTime_IC_MulticS" SG_ 2566869491 Bms20BatSoh 25000;
BA_ "GenSigTimeoutTime_FMS_FMS4" SG_ 2566869491 Bms20BatSoh 25000;
BA_ "CI_SigName" SG_ 2566869491 Bms20BatSoh "BMS20 Battery SOH";
BA_ "CI_SigId" SG_ 2566869491 Bms20BatSoh 2931;
BA_ "CI_ParId" SG_ 2566869491 Bms20BatSoh "IB474";
BA_ "GenSigTimeoutTime_SGW" SG_ 2566869491 Bms19BatSoh 25000;
BA_ "GenSigTimeoutTime_PCM" SG_ 2566869491 Bms19BatSoh 25000;
BA_ "GenSigTimeoutTime_MPPxPTFE2" SG_ 2566869491 Bms19BatSoh 25000;
BA_ "GenSigTimeoutTime_IC_MulticS" SG_ 2566869491 Bms19BatSoh 25000;
BA_ "GenSigTimeoutTime_FMS_FMS4" SG_ 2566869491 Bms19BatSoh 25000;
BA_ "CI_SigName" SG_ 2566869491 Bms19BatSoh "BMS19 Battery SOH";
BA_ "CI_SigId" SG_ 2566869491 Bms19BatSoh 2930;
BA_ "CI_ParId" SG_ 2566869491 Bms19BatSoh "IB473";
BA_ "GenSigTimeoutTime_SGW" SG_ 2566869491 Bms18BatSoh 25000;
BA_ "GenSigTimeoutTime_PCM" SG_ 2566869491 Bms18BatSoh 25000;
BA_ "GenSigTimeoutTime_MPPxPTFE2" SG_ 2566869491 Bms18BatSoh 25000;
BA_ "GenSigTimeoutTime_IC_MulticS" SG_ 2566869491 Bms18BatSoh 25000;
BA_ "GenSigTimeoutTime_FMS_FMS4" SG_ 2566869491 Bms18BatSoh 25000;
BA_ "CI_SigName" SG_ 2566869491 Bms18BatSoh "BMS18 Battery SOH";
BA_ "CI_SigId" SG_ 2566869491 Bms18BatSoh 2929;
BA_ "CI_ParId" SG_ 2566869491 Bms18BatSoh "IB472";
BA_ "GenSigTimeoutTime_SGW" SG_ 2566869491 Bms17BatSoh 25000;
BA_ "GenSigTimeoutTime_PCM" SG_ 2566869491 Bms17BatSoh 25000;
BA_ "GenSigTimeoutTime_MPPxPTFE2" SG_ 2566869491 Bms17BatSoh 25000;
BA_ "GenSigTimeoutTime_IC_MulticS" SG_ 2566869491 Bms17BatSoh 25000;
BA_ "GenSigTimeoutTime_FMS_FMS4" SG_ 2566869491 Bms17BatSoh 25000;
BA_ "CI_SigName" SG_ 2566869491 Bms17BatSoh "BMS17 Battery SOH";
BA_ "CI_SigId" SG_ 2566869491 Bms17BatSoh 2928;
BA_ "CI_ParId" SG_ 2566869491 Bms17BatSoh "IB471";
BA_ "GenSigTimeoutTime_SGW" SG_ 2566869491 Bms16BatSoh 25000;
BA_ "GenSigTimeoutTime_PCM" SG_ 2566869491 Bms16BatSoh 25000;
BA_ "GenSigTimeoutTime_MPPxPTFE2" SG_ 2566869491 Bms16BatSoh 25000;
BA_ "GenSigTimeoutTime_IC_MulticS" SG_ 2566869491 Bms16BatSoh 25000;
BA_ "GenSigTimeoutTime_FMS_FMS4" SG_ 2566869491 Bms16BatSoh 25000;
BA_ "CI_SigName" SG_ 2566869491 Bms16BatSoh "BMS16 Battery SOH";
BA_ "CI_SigId" SG_ 2566869491 Bms16BatSoh 2927;
BA_ "CI_ParId" SG_ 2566869491 Bms16BatSoh "IB470";
BA_ "GenSigTimeoutTime_SGW" SG_ 2566869491 Bms15BatSoh 25000;
BA_ "GenSigTimeoutTime_PCM" SG_ 2566869491 Bms15BatSoh 25000;
BA_ "GenSigTimeoutTime_MPPxPTFE2" SG_ 2566869491 Bms15BatSoh 25000;
BA_ "GenSigTimeoutTime_IC_MulticS" SG_ 2566869491 Bms15BatSoh 25000;
BA_ "GenSigTimeoutTime_FMS_FMS4" SG_ 2566869491 Bms15BatSoh 25000;
BA_ "CI_SigName" SG_ 2566869491 Bms15BatSoh "BMS15 Battery SOH";
BA_ "CI_SigId" SG_ 2566869491 Bms15BatSoh 2926;
BA_ "CI_ParId" SG_ 2566869491 Bms15BatSoh "IB469";
BA_ "GenSigTimeoutTime_SGW" SG_ 2566869491 Bms14BatSoh 25000;
BA_ "GenSigTimeoutTime_PCM" SG_ 2566869491 Bms14BatSoh 25000;
BA_ "GenSigTimeoutTime_MPPxPTFE2" SG_ 2566869491 Bms14BatSoh 25000;
BA_ "GenSigTimeoutTime_IC_MulticS" SG_ 2566869491 Bms14BatSoh 25000;
BA_ "GenSigTimeoutTime_FMS_FMS4" SG_ 2566869491 Bms14BatSoh 25000;
BA_ "CI_SigName" SG_ 2566869491 Bms14BatSoh "BMS14 Battery SOH";
BA_ "CI_SigId" SG_ 2566869491 Bms14BatSoh 2925;
BA_ "CI_ParId" SG_ 2566869491 Bms14BatSoh "IB468";
BA_ "GenSigTimeoutTime_SGW" SG_ 2566869491 Bms13BatSoh 25000;
BA_ "GenSigTimeoutTime_PCM" SG_ 2566869491 Bms13BatSoh 25000;
BA_ "GenSigTimeoutTime_MPPxPTFE2" SG_ 2566869491 Bms13BatSoh 25000;
BA_ "GenSigTimeoutTime_IC_MulticS" SG_ 2566869491 Bms13BatSoh 25000;
BA_ "GenSigTimeoutTime_FMS_FMS4" SG_ 2566869491 Bms13BatSoh 25000;
BA_ "CI_SigName" SG_ 2566869491 Bms13BatSoh "BMS13 Battery SOH";
BA_ "CI_SigId" SG_ 2566869491 Bms13BatSoh 2924;
BA_ "CI_ParId" SG_ 2566869491 Bms13BatSoh "IB467";
BA_ "GenSigTimeoutTime_SGW" SG_ 2566869491 Bms12BatSoh 25000;
BA_ "GenSigTimeoutTime_PCM" SG_ 2566869491 Bms12BatSoh 25000;
BA_ "GenSigTimeoutTime_MPPxPTFE2" SG_ 2566869491 Bms12BatSoh 25000;
BA_ "GenSigTimeoutTime_IC_MulticS" SG_ 2566869491 Bms12BatSoh 25000;
BA_ "GenSigTimeoutTime_FMS_FMS4" SG_ 2566869491 Bms12BatSoh 25000;
BA_ "CI_SigName" SG_ 2566869491 Bms12BatSoh "BMS12 Battery SOH";
BA_ "CI_SigId" SG_ 2566869491 Bms12BatSoh 2923;
BA_ "CI_ParId" SG_ 2566869491 Bms12BatSoh "IB466";
BA_ "GenSigTimeoutTime_SGW" SG_ 2566869491 Bms11BatSoh 25000;
BA_ "GenSigTimeoutTime_PCM" SG_ 2566869491 Bms11BatSoh 25000;
BA_ "GenSigTimeoutTime_MPPxPTFE2" SG_ 2566869491 Bms11BatSoh 25000;
BA_ "GenSigTimeoutTime_IC_MulticS" SG_ 2566869491 Bms11BatSoh 25000;
BA_ "GenSigTimeoutTime_FMS_FMS4" SG_ 2566869491 Bms11BatSoh 25000;
BA_ "CI_SigName" SG_ 2566869491 Bms11BatSoh "BMS11 Battery SOH";
BA_ "CI_SigId" SG_ 2566869491 Bms11BatSoh 2922;
BA_ "CI_ParId" SG_ 2566869491 Bms11BatSoh "IB465";
BA_ "SigType" SG_ 2566884079 TempInvHeatsink 1;
BA_ "GenSigTimeoutTime_VMU" SG_ 2566884079 TempInvHeatsink 2500;
BA_ "GenSigTimeoutTime_VCU" SG_ 2566884079 TempInvHeatsink 2500;
BA_ "GenSigTimeoutTime_SGW" SG_ 2566884079 TempInvHeatsink 2500;
BA_ "GenSigTimeoutTime_PCM" SG_ 2566884079 TempInvHeatsink 2500;
BA_ "GenSigStartValue" SG_ 2566884079 TempInvHeatsink 40;
BA_ "CI_SigName" SG_ 2566884079 TempInvHeatsink "Temperature Inverter Heatsink";
BA_ "CI_SigId" SG_ 2566884079 TempInvHeatsink 1462;
BA_ "CI_ParId" SG_ 2566884079 TempInvHeatsink "IB175";
BA_ "SigType" SG_ 2348884337 WindshWiperOff 4;
BA_ "GenSigTimeoutTime_SGW" SG_ 2348884337 WindshWiperOff 500;
BA_ "GenSigTimeoutTime_PCM" SG_ 2348884337 WindshWiperOff 500;
BA_ "GenSigTimeoutTime_MPPxPTFE2" SG_ 2348884337 WindshWiperOff 500;
BA_ "GenSigTimeoutTime_FMS_FMS5" SG_ 2348884337 WindshWiperOff 500;
BA_ "GenSigTimeoutTime_FMS_FMS4" SG_ 2348884337 WindshWiperOff 500;
BA_ "GenSigTimeoutTime_BCM_NBM" SG_ 2348884337 WindshWiperOff 500;
BA_ "CI_SigName" SG_ 2348884337 WindshWiperOff "Windshield Wiper Off";
BA_ "CI_SigId" SG_ 2348884337 WindshWiperOff 3748;
BA_ "CI_ParId" SG_ 2348884337 WindshWiperOff "IS404";
BA_ "SigType" SG_ 2348884337 EngBrkIntLevPos5 4;
BA_ "GenSigTimeoutTime_SGW" SG_ 2348884337 EngBrkIntLevPos5 500;
BA_ "GenSigTimeoutTime_RM_IRCS" SG_ 2348884337 EngBrkIntLevPos5 500;
BA_ "GenSigTimeoutTime_PCM" SG_ 2348884337 EngBrkIntLevPos5 500;
BA_ "GenSigTimeoutTime_MPPxPTFE2" SG_ 2348884337 EngBrkIntLevPos5 500;
BA_ "GenSigTimeoutTime_FMS_FMS5" SG_ 2348884337 EngBrkIntLevPos5 500;
BA_ "GenSigTimeoutTime_FMS_FMS4" SG_ 2348884337 EngBrkIntLevPos5 500;
BA_ "GenSigTimeoutTime_BCM_NBM" SG_ 2348884337 EngBrkIntLevPos5 500;
BA_ "CI_SigName" SG_ 2348884337 EngBrkIntLevPos5 "Engine Brake Intarder Lever Position 5";
BA_ "CI_SigId" SG_ 2348884337 EngBrkIntLevPos5 3747;
BA_ "CI_ParId" SG_ 2348884337 EngBrkIntLevPos5 "IB1015";
BA_ "SigType" SG_ 2348884337 EngBrkIntLevPos6 4;
BA_ "GenSigTimeoutTime_SGW" SG_ 2348884337 EngBrkIntLevPos6 500;
BA_ "GenSigTimeoutTime_RM_IRCS" SG_ 2348884337 EngBrkIntLevPos6 500;
BA_ "GenSigTimeoutTime_PCM" SG_ 2348884337 EngBrkIntLevPos6 500;
BA_ "GenSigTimeoutTime_MPPxPTFE2" SG_ 2348884337 EngBrkIntLevPos6 500;
BA_ "GenSigTimeoutTime_FMS_FMS5" SG_ 2348884337 EngBrkIntLevPos6 500;
BA_ "GenSigTimeoutTime_FMS_FMS4" SG_ 2348884337 EngBrkIntLevPos6 500;
BA_ "GenSigTimeoutTime_BCM_NBM" SG_ 2348884337 EngBrkIntLevPos6 500;
BA_ "CI_SigName" SG_ 2348884337 EngBrkIntLevPos6 "Engine Brake Intarder Lever Position 6";
BA_ "CI_SigId" SG_ 2348884337 EngBrkIntLevPos6 3746;
BA_ "CI_ParId" SG_ 2348884337 EngBrkIntLevPos6 "IB1016";
BA_ "SigType" SG_ 2348884337 EngBrkIntLevPos1 4;
BA_ "GenSigTimeoutTime_SGW" SG_ 2348884337 EngBrkIntLevPos1 500;
BA_ "GenSigTimeoutTime_RM_IRCS" SG_ 2348884337 EngBrkIntLevPos1 500;
BA_ "GenSigTimeoutTime_PCM" SG_ 2348884337 EngBrkIntLevPos1 500;
BA_ "GenSigTimeoutTime_MPPxPTFE2" SG_ 2348884337 EngBrkIntLevPos1 500;
BA_ "GenSigTimeoutTime_FMS_FMS5" SG_ 2348884337 EngBrkIntLevPos1 500;
BA_ "GenSigTimeoutTime_FMS_FMS4" SG_ 2348884337 EngBrkIntLevPos1 500;
BA_ "GenSigTimeoutTime_BCM_NBM" SG_ 2348884337 EngBrkIntLevPos1 500;
BA_ "CI_SigName" SG_ 2348884337 EngBrkIntLevPos1 "Engine Brake Intarder Lever Position 1";
BA_ "CI_SigId" SG_ 2348884337 EngBrkIntLevPos1 3743;
BA_ "CI_ParId" SG_ 2348884337 EngBrkIntLevPos1 "IB1011";
BA_ "SigType" SG_ 2348884337 EngBrkIntLevPos2 4;
BA_ "GenSigTimeoutTime_SGW" SG_ 2348884337 EngBrkIntLevPos2 500;
BA_ "GenSigTimeoutTime_RM_IRCS" SG_ 2348884337 EngBrkIntLevPos2 500;
BA_ "GenSigTimeoutTime_PCM" SG_ 2348884337 EngBrkIntLevPos2 500;
BA_ "GenSigTimeoutTime_MPPxPTFE2" SG_ 2348884337 EngBrkIntLevPos2 500;
BA_ "GenSigTimeoutTime_FMS_FMS5" SG_ 2348884337 EngBrkIntLevPos2 500;
BA_ "GenSigTimeoutTime_FMS_FMS4" SG_ 2348884337 EngBrkIntLevPos2 500;
BA_ "GenSigTimeoutTime_BCM_NBM" SG_ 2348884337 EngBrkIntLevPos2 500;
BA_ "CI_SigName" SG_ 2348884337 EngBrkIntLevPos2 "Engine Brake Intarder Lever Position 2";
BA_ "CI_SigId" SG_ 2348884337 EngBrkIntLevPos2 3742;
BA_ "CI_ParId" SG_ 2348884337 EngBrkIntLevPos2 "IB1012";
BA_ "SigType" SG_ 2348884337 EngBrkIntLevPos3 4;
BA_ "GenSigTimeoutTime_SGW" SG_ 2348884337 EngBrkIntLevPos3 500;
BA_ "GenSigTimeoutTime_RM_IRCS" SG_ 2348884337 EngBrkIntLevPos3 500;
BA_ "GenSigTimeoutTime_PCM" SG_ 2348884337 EngBrkIntLevPos3 500;
BA_ "GenSigTimeoutTime_MPPxPTFE2" SG_ 2348884337 EngBrkIntLevPos3 500;
BA_ "GenSigTimeoutTime_FMS_FMS5" SG_ 2348884337 EngBrkIntLevPos3 500;
BA_ "GenSigTimeoutTime_FMS_FMS4" SG_ 2348884337 EngBrkIntLevPos3 500;
BA_ "GenSigTimeoutTime_BCM_NBM" SG_ 2348884337 EngBrkIntLevPos3 500;
BA_ "CI_SigName" SG_ 2348884337 EngBrkIntLevPos3 "Engine Brake Intarder Lever Position 3";
BA_ "CI_SigId" SG_ 2348884337 EngBrkIntLevPos3 3741;
BA_ "CI_ParId" SG_ 2348884337 EngBrkIntLevPos3 "IB1013";
BA_ "SigType" SG_ 2348884337 EngBrkIntLevPos4 4;
BA_ "GenSigTimeoutTime_SGW" SG_ 2348884337 EngBrkIntLevPos4 500;
BA_ "GenSigTimeoutTime_RM_IRCS" SG_ 2348884337 EngBrkIntLevPos4 500;
BA_ "GenSigTimeoutTime_PCM" SG_ 2348884337 EngBrkIntLevPos4 500;
BA_ "GenSigTimeoutTime_MPPxPTFE2" SG_ 2348884337 EngBrkIntLevPos4 500;
BA_ "GenSigTimeoutTime_FMS_FMS5" SG_ 2348884337 EngBrkIntLevPos4 500;
BA_ "GenSigTimeoutTime_FMS_FMS4" SG_ 2348884337 EngBrkIntLevPos4 500;
BA_ "GenSigTimeoutTime_BCM_NBM" SG_ 2348884337 EngBrkIntLevPos4 500;
BA_ "CI_SigName" SG_ 2348884337 EngBrkIntLevPos4 "Engine Brake Intarder Lever Position 4";
BA_ "CI_SigId" SG_ 2348884337 EngBrkIntLevPos4 3740;
BA_ "CI_ParId" SG_ 2348884337 EngBrkIntLevPos4 "IB1014";
BA_ "SigType" SG_ 2348884337 EngBrkIntLevPosOff 4;
BA_ "GenSigTimeoutTime_SGW" SG_ 2348884337 EngBrkIntLevPosOff 500;
BA_ "GenSigTimeoutTime_RM_IRCS" SG_ 2348884337 EngBrkIntLevPosOff 500;
BA_ "GenSigTimeoutTime_PCM" SG_ 2348884337 EngBrkIntLevPosOff 500;
BA_ "GenSigTimeoutTime_MPPxPTFE2" SG_ 2348884337 EngBrkIntLevPosOff 500;
BA_ "GenSigTimeoutTime_FMS_FMS5" SG_ 2348884337 EngBrkIntLevPosOff 500;
BA_ "GenSigTimeoutTime_FMS_FMS4" SG_ 2348884337 EngBrkIntLevPosOff 500;
BA_ "GenSigTimeoutTime_BSM_EBS" SG_ 2348884337 EngBrkIntLevPosOff 500;
BA_ "GenSigTimeoutTime_BCM_NBM" SG_ 2348884337 EngBrkIntLevPosOff 500;
BA_ "CI_SigName" SG_ 2348884337 EngBrkIntLevPosOff "Engine Brake Intarder Lever Position OFF";
BA_ "CI_SigId" SG_ 2348884337 EngBrkIntLevPosOff 3736;
BA_ "CI_ParId" SG_ 2348884337 EngBrkIntLevPosOff "IB1010";
BA_ "SigType" SG_ 2365484270 TcoVehSpeed 1;
BA_ "SPN" SG_ 2365484270 TcoVehSpeed 1624;
BA_ "GenSigTimeoutTime_VMU" SG_ 2365484270 TcoVehSpeed 500;
BA_ "GenSigTimeoutTime_VCU" SG_ 2365484270 TcoVehSpeed 500;
BA_ "GenSigTimeoutTime_VCM" SG_ 2365484270 TcoVehSpeed 500;
BA_ "GenSigTimeoutTime_TPMS" SG_ 2365484270 TcoVehSpeed 500;
BA_ "GenSigTimeoutTime_TASM_ETS" SG_ 2365484270 TcoVehSpeed 500;
BA_ "GenSigTimeoutTime_SGW" SG_ 2365484270 TcoVehSpeed 500;
BA_ "GenSigTimeoutTime_RM_IRCS" SG_ 2365484270 TcoVehSpeed 500;
BA_ "GenSigTimeoutTime_PCM" SG_ 2365484270 TcoVehSpeed 500;
BA_ "GenSigTimeoutTime_MPPxPTFE2" SG_ 2365484270 TcoVehSpeed 500;
BA_ "GenSigTimeoutTime_IC_MulticS" SG_ 2365484270 TcoVehSpeed 500;
BA_ "GenSigTimeoutTime_IC_MulticII" SG_ 2365484270 TcoVehSpeed 500;
BA_ "GenSigTimeoutTime_FMS_FMS5" SG_ 2365484270 TcoVehSpeed 500;
BA_ "GenSigTimeoutTime_FMS_FMS4" SG_ 2365484270 TcoVehSpeed 500;
BA_ "GenSigTimeoutTime_ECM_MD1_G" SG_ 2365484270 TcoVehSpeed 500;
BA_ "GenSigTimeoutTime_ECM_MD1_D" SG_ 2365484270 TcoVehSpeed 500;
BA_ "GenSigTimeoutTime_BSM_EBS" SG_ 2365484270 TcoVehSpeed 500;
BA_ "GenSigTimeoutTime_BCM_NBM" SG_ 2365484270 TcoVehSpeed 500;
BA_ "GenSigTimeoutTime_Av2HP" SG_ 2365484270 TcoVehSpeed 500;
BA_ "GenSigTimeoutTime_ASM_ELC5_Fr" SG_ 2365484270 TcoVehSpeed 500;
BA_ "GenSigTimeoutTime_ADCU" SG_ 2365484270 TcoVehSpeed 500;
BA_ "CI_SigName" SG_ 2365484270 TcoVehSpeed "Tachograph vehicle speed";
BA_ "CI_SigId" SG_ 2365484270 TcoVehSpeed 669;
BA_ "CI_ParId" SG_ 2365484270 TcoVehSpeed "1624";
BA_ "SigType" SG_ 2365484270 DirInd 4;
BA_ "SPN" SG_ 2365484270 DirInd 1619;
BA_ "GenSigTimeoutTime_TASM_ETS" SG_ 2365484270 DirInd 500;
BA_ "GenSigTimeoutTime_SGW" SG_ 2365484270 DirInd 500;
BA_ "GenSigTimeoutTime_PCM" SG_ 2365484270 DirInd 500;
BA_ "GenSigTimeoutTime_MPPxPTFE2" SG_ 2365484270 DirInd 500;
BA_ "GenSigTimeoutTime_FMS_FMS5" SG_ 2365484270 DirInd 500;
BA_ "GenSigTimeoutTime_FMS_FMS4" SG_ 2365484270 DirInd 500;
BA_ "CI_SigName" SG_ 2365484270 DirInd "Direction indicator";
BA_ "CI_SigId" SG_ 2365484270 DirInd 667;
BA_ "CI_ParId" SG_ 2365484270 DirInd "1619";
BA_ "SigType" SG_ 2365484270 TcoPerf 4;
BA_ "SPN" SG_ 2365484270 TcoPerf 1620;
BA_ "GenSigTimeoutTime_VCM" SG_ 2365484270 TcoPerf 500;
BA_ "GenSigTimeoutTime_SGW" SG_ 2365484270 TcoPerf 500;
BA_ "GenSigTimeoutTime_PCM" SG_ 2365484270 TcoPerf 500;
BA_ "GenSigTimeoutTime_MPPxPTFE2" SG_ 2365484270 TcoPerf 500;
BA_ "GenSigTimeoutTime_IC_MulticS" SG_ 2365484270 TcoPerf 500;
BA_ "GenSigTimeoutTime_FMS_FMS5" SG_ 2365484270 TcoPerf 500;
BA_ "GenSigTimeoutTime_FMS_FMS4" SG_ 2365484270 TcoPerf 500;
BA_ "CI_SigName" SG_ 2365484270 TcoPerf "Tachograph performance";
BA_ "CI_SigId" SG_ 2365484270 TcoPerf 666;
BA_ "CI_ParId" SG_ 2365484270 TcoPerf "1620";
BA_ "SigType" SG_ 2365484270 HandInfo 4;
BA_ "SPN" SG_ 2365484270 HandInfo 1621;
BA_ "GenSigTimeoutTime_VCM" SG_ 2365484270 HandInfo 500;
BA_ "GenSigTimeoutTime_SGW" SG_ 2365484270 HandInfo 500;
BA_ "GenSigTimeoutTime_PCM" SG_ 2365484270 HandInfo 500;
BA_ "GenSigTimeoutTime_MPPxPTFE2" SG_ 2365484270 HandInfo 500;
BA_ "GenSigTimeoutTime_IC_MulticS" SG_ 2365484270 HandInfo 500;
BA_ "GenSigTimeoutTime_FMS_FMS5" SG_ 2365484270 HandInfo 500;
BA_ "GenSigTimeoutTime_FMS_FMS4" SG_ 2365484270 HandInfo 500;
BA_ "CI_SigName" SG_ 2365484270 HandInfo "Handling information";
BA_ "CI_SigId" SG_ 2365484270 HandInfo 665;
BA_ "CI_ParId" SG_ 2365484270 HandInfo "1621";
BA_ "SigType" SG_ 2365484270 SysEvt 4;
BA_ "SPN" SG_ 2365484270 SysEvt 1622;
BA_ "GenSigTimeoutTime_VCM" SG_ 2365484270 SysEvt 500;
BA_ "GenSigTimeoutTime_SGW" SG_ 2365484270 SysEvt 500;
BA_ "GenSigTimeoutTime_PCM" SG_ 2365484270 SysEvt 500;
BA_ "GenSigTimeoutTime_MPPxPTFE2" SG_ 2365484270 SysEvt 500;
BA_ "GenSigTimeoutTime_IC_MulticS" SG_ 2365484270 SysEvt 500;
BA_ "GenSigTimeoutTime_FMS_FMS5" SG_ 2365484270 SysEvt 500;
BA_ "GenSigTimeoutTime_FMS_FMS4" SG_ 2365484270 SysEvt 500;
BA_ "CI_SigName" SG_ 2365484270 SysEvt "System event";
BA_ "CI_SigId" SG_ 2365484270 SysEvt 664;
BA_ "CI_ParId" SG_ 2365484270 SysEvt "1622";
BA_ "SigType" SG_ 2365484270 DrivCardDriv2 4;
BA_ "SPN" SG_ 2365484270 DrivCardDriv2 1616;
BA_ "GenSigTimeoutTime_VCM" SG_ 2365484270 DrivCardDriv2 500;
BA_ "GenSigTimeoutTime_SGW" SG_ 2365484270 DrivCardDriv2 500;
BA_ "GenSigTimeoutTime_PCM" SG_ 2365484270 DrivCardDriv2 500;
BA_ "GenSigTimeoutTime_MPPxPTFE2" SG_ 2365484270 DrivCardDriv2 500;
BA_ "GenSigTimeoutTime_FMS_FMS5" SG_ 2365484270 DrivCardDriv2 500;
BA_ "GenSigTimeoutTime_FMS_FMS4" SG_ 2365484270 DrivCardDriv2 500;
BA_ "CI_SigName" SG_ 2365484270 DrivCardDriv2 "Driver card, driver 2";
BA_ "CI_SigId" SG_ 2365484270 DrivCardDriv2 663;
BA_ "CI_ParId" SG_ 2365484270 DrivCardDriv2 "1616";
BA_ "SPN" SG_ 2365484270 Driv2TimeRelSts 1618;
BA_ "GenSigTimeoutTime_VCM" SG_ 2365484270 Driv2TimeRelSts 500;
BA_ "GenSigTimeoutTime_SGW" SG_ 2365484270 Driv2TimeRelSts 500;
BA_ "GenSigTimeoutTime_PCM" SG_ 2365484270 Driv2TimeRelSts 500;
BA_ "GenSigTimeoutTime_MPPxPTFE2" SG_ 2365484270 Driv2TimeRelSts 500;
BA_ "GenSigTimeoutTime_IC_MulticS" SG_ 2365484270 Driv2TimeRelSts 500;
BA_ "GenSigTimeoutTime_FMS_FMS5" SG_ 2365484270 Driv2TimeRelSts 500;
BA_ "GenSigTimeoutTime_FMS_FMS4" SG_ 2365484270 Driv2TimeRelSts 500;
BA_ "CI_SigName" SG_ 2365484270 Driv2TimeRelSts "Driver 2 Time Related States";
BA_ "CI_SigId" SG_ 2365484270 Driv2TimeRelSts 662;
BA_ "CI_ParId" SG_ 2365484270 Driv2TimeRelSts "1618";
BA_ "SigType" SG_ 2365484270 VehOverspeed 4;
BA_ "SPN" SG_ 2365484270 VehOverspeed 1614;
BA_ "GenSigTimeoutTime_VCM" SG_ 2365484270 VehOverspeed 500;
BA_ "GenSigTimeoutTime_SGW" SG_ 2365484270 VehOverspeed 500;
BA_ "GenSigTimeoutTime_PCM" SG_ 2365484270 VehOverspeed 500;
BA_ "GenSigTimeoutTime_MPPxPTFE2" SG_ 2365484270 VehOverspeed 500;
BA_ "GenSigTimeoutTime_IC_MulticS" SG_ 2365484270 VehOverspeed 500;
BA_ "GenSigTimeoutTime_FMS_FMS5" SG_ 2365484270 VehOverspeed 500;
BA_ "GenSigTimeoutTime_FMS_FMS4" SG_ 2365484270 VehOverspeed 500;
BA_ "CI_SigName" SG_ 2365484270 VehOverspeed "Vehicle Overspeed";
BA_ "CI_SigId" SG_ 2365484270 VehOverspeed 661;
BA_ "CI_ParId" SG_ 2365484270 VehOverspeed "1614";
BA_ "SigType" SG_ 2365484270 DrivCardDriv1 4;
BA_ "SPN" SG_ 2365484270 DrivCardDriv1 1615;
BA_ "GenSigTimeoutTime_VCM" SG_ 2365484270 DrivCardDriv1 500;
BA_ "GenSigTimeoutTime_SGW" SG_ 2365484270 DrivCardDriv1 500;
BA_ "GenSigTimeoutTime_PCM" SG_ 2365484270 DrivCardDriv1 500;
BA_ "GenSigTimeoutTime_MPPxPTFE2" SG_ 2365484270 DrivCardDriv1 500;
BA_ "GenSigTimeoutTime_FMS_FMS5" SG_ 2365484270 DrivCardDriv1 500;
BA_ "GenSigTimeoutTime_FMS_FMS4" SG_ 2365484270 DrivCardDriv1 500;
BA_ "GenSigTimeoutTime_BCM_NBM" SG_ 2365484270 DrivCardDriv1 500;
BA_ "CI_SigName" SG_ 2365484270 DrivCardDriv1 "Driver card, driver 1";
BA_ "CI_SigId" SG_ 2365484270 DrivCardDriv1 660;
BA_ "CI_ParId" SG_ 2365484270 DrivCardDriv1 "1615";
BA_ "SPN" SG_ 2365484270 Driv1TimeRelSts 1617;
BA_ "GenSigTimeoutTime_VCM" SG_ 2365484270 Driv1TimeRelSts 500;
BA_ "GenSigTimeoutTime_SGW" SG_ 2365484270 Driv1TimeRelSts 500;
BA_ "GenSigTimeoutTime_PCM" SG_ 2365484270 Driv1TimeRelSts 500;
BA_ "GenSigTimeoutTime_MPPxPTFE2" SG_ 2365484270 Driv1TimeRelSts 500;
BA_ "GenSigTimeoutTime_IC_MulticS" SG_ 2365484270 Driv1TimeRelSts 500;
BA_ "GenSigTimeoutTime_FMS_FMS5" SG_ 2365484270 Driv1TimeRelSts 500;
BA_ "GenSigTimeoutTime_FMS_FMS4" SG_ 2365484270 Driv1TimeRelSts 500;
BA_ "CI_SigName" SG_ 2365484270 Driv1TimeRelSts "Driver 1 Time Related States";
BA_ "CI_SigId" SG_ 2365484270 Driv1TimeRelSts 659;
BA_ "CI_ParId" SG_ 2365484270 Driv1TimeRelSts "1617";
BA_ "SigType" SG_ 2365484270 VehMot 4;
BA_ "SPN" SG_ 2365484270 VehMot 1611;
BA_ "GenSigTimeoutTime_VCM" SG_ 2365484270 VehMot 500;
BA_ "GenSigTimeoutTime_SGW" SG_ 2365484270 VehMot 500;
BA_ "GenSigTimeoutTime_PCM" SG_ 2365484270 VehMot 500;
BA_ "GenSigTimeoutTime_MPPxPTFE2" SG_ 2365484270 VehMot 500;
BA_ "GenSigTimeoutTime_FMS_FMS5" SG_ 2365484270 VehMot 500;
BA_ "GenSigTimeoutTime_FMS_FMS4" SG_ 2365484270 VehMot 500;
BA_ "CI_SigName" SG_ 2365484270 VehMot "Vehicle motion";
BA_ "CI_SigId" SG_ 2365484270 VehMot 658;
BA_ "CI_ParId" SG_ 2365484270 VehMot "1611";
BA_ "SPN" SG_ 2365484270 Driv2WorkSts 1613;
BA_ "GenSigTimeoutTime_VCM" SG_ 2365484270 Driv2WorkSts 500;
BA_ "GenSigTimeoutTime_SGW" SG_ 2365484270 Driv2WorkSts 500;
BA_ "GenSigTimeoutTime_PCM" SG_ 2365484270 Driv2WorkSts 500;
BA_ "GenSigTimeoutTime_MPPxPTFE2" SG_ 2365484270 Driv2WorkSts 500;
BA_ "GenSigTimeoutTime_FMS_FMS5" SG_ 2365484270 Driv2WorkSts 500;
BA_ "GenSigTimeoutTime_FMS_FMS4" SG_ 2365484270 Driv2WorkSts 500;
BA_ "GenSigTimeoutTime_ADCU" SG_ 2365484270 Driv2WorkSts 500;
BA_ "CI_SigName" SG_ 2365484270 Driv2WorkSts "Driver 2 working state";
BA_ "CI_SigId" SG_ 2365484270 Driv2WorkSts 657;
BA_ "CI_ParId" SG_ 2365484270 Driv2WorkSts "1613";
BA_ "SPN" SG_ 2365484270 Driv1WorkSts 1612;
BA_ "GenSigTimeoutTime_VCM" SG_ 2365484270 Driv1WorkSts 500;
BA_ "GenSigTimeoutTime_SGW" SG_ 2365484270 Driv1WorkSts 500;
BA_ "GenSigTimeoutTime_PCM" SG_ 2365484270 Driv1WorkSts 500;
BA_ "GenSigTimeoutTime_MPPxPTFE2" SG_ 2365484270 Driv1WorkSts 500;
BA_ "GenSigTimeoutTime_FMS_FMS5" SG_ 2365484270 Driv1WorkSts 500;
BA_ "GenSigTimeoutTime_FMS_FMS4" SG_ 2365484270 Driv1WorkSts 500;
BA_ "GenSigTimeoutTime_ADCU" SG_ 2365484270 Driv1WorkSts 500;
BA_ "CI_SigName" SG_ 2365484270 Driv1WorkSts "Driver 1 working state";
BA_ "CI_SigId" SG_ 2365484270 Driv1WorkSts 656;
BA_ "CI_ParId" SG_ 2365484270 Driv1WorkSts "1612";
BA_ "SigType" SG_ 2566842094 Yr 1;
BA_ "SPN" SG_ 2566842094 Yr 964;
BA_ "GenSigTimeoutTime_VMU" SG_ 2566842094 Yr 5000;
BA_ "GenSigTimeoutTime_VCU" SG_ 2566842094 Yr 5000;
BA_ "GenSigTimeoutTime_VCM" SG_ 2566842094 Yr 5000;
BA_ "GenSigTimeoutTime_TPMS" SG_ 2566842094 Yr 5000;
BA_ "GenSigTimeoutTime_SGW2" SG_ 2566842094 Yr 5000;
BA_ "GenSigTimeoutTime_SGW" SG_ 2566842094 Yr 5000;
BA_ "GenSigTimeoutTime_RM_IRCS" SG_ 2566842094 Yr 5000;
BA_ "GenSigTimeoutTime_PCM" SG_ 2566842094 Yr 5000;
BA_ "GenSigTimeoutTime_MPPxPTFE2" SG_ 2566842094 Yr 5000;
BA_ "GenSigTimeoutTime_MBMS" SG_ 2566842094 Yr 5000;
BA_ "GenSigTimeoutTime_INVEM1_ELFA3" SG_ 2566842094 Yr 5000;
BA_ "GenSigTimeoutTime_IC_MulticS" SG_ 2566842094 Yr 5000;
BA_ "GenSigTimeoutTime_IC_MulticII" SG_ 2566842094 Yr 5000;
BA_ "GenSigTimeoutTime_HVPDU_HV_BOX" SG_ 2566842094 Yr 5000;
BA_ "GenSigTimeoutTime_FMS_FMS5" SG_ 2566842094 Yr 5000;
BA_ "GenSigTimeoutTime_FMS_FMS4" SG_ 2566842094 Yr 5000;
BA_ "GenSigTimeoutTime_ETC_Ecolife2" SG_ 2566842094 Yr 5000;
BA_ "GenSigTimeoutTime_ECM_MD1_G" SG_ 2566842094 Yr 5000;
BA_ "GenSigTimeoutTime_ECM_MD1_D" SG_ 2566842094 Yr 5000;
BA_ "GenSigTimeoutTime_DMS" SG_ 2566842094 Yr 5000;
BA_ "GenSigTimeoutTime_DICO" SG_ 2566842094 Yr 5000;
BA_ "GenSigTimeoutTime_BSM_EBS" SG_ 2566842094 Yr 5000;
BA_ "GenSigTimeoutTime_BCM_NBM" SG_ 2566842094 Yr 5000;
BA_ "GenSigTimeoutTime_Av2HP" SG_ 2566842094 Yr 5000;
BA_ "GenSigTimeoutTime_ASM_ELC5_Fr" SG_ 2566842094 Yr 5000;
BA_ "GenSigTimeoutTime_AI_CAID" SG_ 2566842094 Yr 5000;
BA_ "GenSigTimeoutTime_ADCU" SG_ 2566842094 Yr 5000;
BA_ "GenSigTimeoutTime_ACM_CANAIR" SG_ 2566842094 Yr 5000;
BA_ "CI_SigName" SG_ 2566842094 Yr "Year";
BA_ "CI_SigId" SG_ 2566842094 Yr 700;
BA_ "CI_ParId" SG_ 2566842094 Yr "964";
BA_ "SigType" SG_ 2566842094 Day 1;
BA_ "SPN" SG_ 2566842094 Day 962;
BA_ "GenSigTimeoutTime_VMU" SG_ 2566842094 Day 5000;
BA_ "GenSigTimeoutTime_VCU" SG_ 2566842094 Day 5000;
BA_ "GenSigTimeoutTime_VCM" SG_ 2566842094 Day 5000;
BA_ "GenSigTimeoutTime_TPMS" SG_ 2566842094 Day 5000;
BA_ "GenSigTimeoutTime_SGW2" SG_ 2566842094 Day 5000;
BA_ "GenSigTimeoutTime_SGW" SG_ 2566842094 Day 5000;
BA_ "GenSigTimeoutTime_RM_IRCS" SG_ 2566842094 Day 5000;
BA_ "GenSigTimeoutTime_PCM" SG_ 2566842094 Day 5000;
BA_ "GenSigTimeoutTime_MPPxPTFE2" SG_ 2566842094 Day 5000;
BA_ "GenSigTimeoutTime_MBMS" SG_ 2566842094 Day 5000;
BA_ "GenSigTimeoutTime_INVEM1_ELFA3" SG_ 2566842094 Day 5000;
BA_ "GenSigTimeoutTime_IC_MulticS" SG_ 2566842094 Day 5000;
BA_ "GenSigTimeoutTime_IC_MulticII" SG_ 2566842094 Day 5000;
BA_ "GenSigTimeoutTime_HVPDU_HV_BOX" SG_ 2566842094 Day 5000;
BA_ "GenSigTimeoutTime_FMS_FMS5" SG_ 2566842094 Day 5000;
BA_ "GenSigTimeoutTime_FMS_FMS4" SG_ 2566842094 Day 5000;
BA_ "GenSigTimeoutTime_ETC_Ecolife2" SG_ 2566842094 Day 5000;
BA_ "GenSigTimeoutTime_ECM_MD1_G" SG_ 2566842094 Day 5000;
BA_ "GenSigTimeoutTime_ECM_MD1_D" SG_ 2566842094 Day 5000;
BA_ "GenSigTimeoutTime_DMS" SG_ 2566842094 Day 5000;
BA_ "GenSigTimeoutTime_DICO" SG_ 2566842094 Day 5000;
BA_ "GenSigTimeoutTime_BSM_EBS" SG_ 2566842094 Day 5000;
BA_ "GenSigTimeoutTime_BCM_NBM" SG_ 2566842094 Day 5000;
BA_ "GenSigTimeoutTime_Av2HP" SG_ 2566842094 Day 5000;
BA_ "GenSigTimeoutTime_ASM_ELC5_Fr" SG_ 2566842094 Day 5000;
BA_ "GenSigTimeoutTime_AI_CAID" SG_ 2566842094 Day 5000;
BA_ "GenSigTimeoutTime_ADCU" SG_ 2566842094 Day 5000;
BA_ "GenSigTimeoutTime_ACM_CANAIR" SG_ 2566842094 Day 5000;
BA_ "CI_SigName" SG_ 2566842094 Day "Day";
BA_ "CI_SigId" SG_ 2566842094 Day 699;
BA_ "CI_ParId" SG_ 2566842094 Day "962";
BA_ "SigType" SG_ 2566842094 Month 1;
BA_ "SPN" SG_ 2566842094 Month 963;
BA_ "GenSigTimeoutTime_VMU" SG_ 2566842094 Month 5000;
BA_ "GenSigTimeoutTime_VCU" SG_ 2566842094 Month 5000;
BA_ "GenSigTimeoutTime_VCM" SG_ 2566842094 Month 5000;
BA_ "GenSigTimeoutTime_TPMS" SG_ 2566842094 Month 5000;
BA_ "GenSigTimeoutTime_SGW2" SG_ 2566842094 Month 5000;
BA_ "GenSigTimeoutTime_SGW" SG_ 2566842094 Month 5000;
BA_ "GenSigTimeoutTime_RM_IRCS" SG_ 2566842094 Month 5000;
BA_ "GenSigTimeoutTime_PCM" SG_ 2566842094 Month 5000;
BA_ "GenSigTimeoutTime_MPPxPTFE2" SG_ 2566842094 Month 5000;
BA_ "GenSigTimeoutTime_MBMS" SG_ 2566842094 Month 5000;
BA_ "GenSigTimeoutTime_INVEM1_ELFA3" SG_ 2566842094 Month 5000;
BA_ "GenSigTimeoutTime_IC_MulticS" SG_ 2566842094 Month 5000;
BA_ "GenSigTimeoutTime_IC_MulticII" SG_ 2566842094 Month 5000;
BA_ "GenSigTimeoutTime_HVPDU_HV_BOX" SG_ 2566842094 Month 5000;
BA_ "GenSigTimeoutTime_FMS_FMS5" SG_ 2566842094 Month 5000;
BA_ "GenSigTimeoutTime_FMS_FMS4" SG_ 2566842094 Month 5000;
BA_ "GenSigTimeoutTime_ETC_Ecolife2" SG_ 2566842094 Month 5000;
BA_ "GenSigTimeoutTime_ECM_MD1_G" SG_ 2566842094 Month 5000;
BA_ "GenSigTimeoutTime_ECM_MD1_D" SG_ 2566842094 Month 5000;
BA_ "GenSigTimeoutTime_DMS" SG_ 2566842094 Month 5000;
BA_ "GenSigTimeoutTime_DICO" SG_ 2566842094 Month 5000;
BA_ "GenSigTimeoutTime_BSM_EBS" SG_ 2566842094 Month 5000;
BA_ "GenSigTimeoutTime_BCM_NBM" SG_ 2566842094 Month 5000;
BA_ "GenSigTimeoutTime_Av2HP" SG_ 2566842094 Month 5000;
BA_ "GenSigTimeoutTime_ASM_ELC5_Fr" SG_ 2566842094 Month 5000;
BA_ "GenSigTimeoutTime_AI_CAID" SG_ 2566842094 Month 5000;
BA_ "GenSigTimeoutTime_ADCU" SG_ 2566842094 Month 5000;
BA_ "GenSigTimeoutTime_ACM_CANAIR" SG_ 2566842094 Month 5000;
BA_ "CI_SigName" SG_ 2566842094 Month "Month";
BA_ "CI_SigId" SG_ 2566842094 Month 698;
BA_ "CI_ParId" SG_ 2566842094 Month "963";
BA_ "SigType" SG_ 2566842094 Hr 1;
BA_ "SPN" SG_ 2566842094 Hr 961;
BA_ "GenSigTimeoutTime_VMU" SG_ 2566842094 Hr 5000;
BA_ "GenSigTimeoutTime_VCU" SG_ 2566842094 Hr 5000;
BA_ "GenSigTimeoutTime_VCM" SG_ 2566842094 Hr 5000;
BA_ "GenSigTimeoutTime_TPMS" SG_ 2566842094 Hr 5000;
BA_ "GenSigTimeoutTime_SGW2" SG_ 2566842094 Hr 5000;
BA_ "GenSigTimeoutTime_SGW" SG_ 2566842094 Hr 5000;
BA_ "GenSigTimeoutTime_RM_IRCS" SG_ 2566842094 Hr 5000;
BA_ "GenSigTimeoutTime_PCM" SG_ 2566842094 Hr 5000;
BA_ "GenSigTimeoutTime_MPPxPTFE2" SG_ 2566842094 Hr 5000;
BA_ "GenSigTimeoutTime_MBMS" SG_ 2566842094 Hr 5000;
BA_ "GenSigTimeoutTime_INVEM1_ELFA3" SG_ 2566842094 Hr 5000;
BA_ "GenSigTimeoutTime_IC_MulticS" SG_ 2566842094 Hr 5000;
BA_ "GenSigTimeoutTime_IC_MulticII" SG_ 2566842094 Hr 5000;
BA_ "GenSigTimeoutTime_HVPDU_HV_BOX" SG_ 2566842094 Hr 5000;
BA_ "GenSigTimeoutTime_FMS_FMS5" SG_ 2566842094 Hr 5000;
BA_ "GenSigTimeoutTime_FMS_FMS4" SG_ 2566842094 Hr 5000;
BA_ "GenSigTimeoutTime_ETC_Ecolife2" SG_ 2566842094 Hr 5000;
BA_ "GenSigTimeoutTime_ECM_MD1_G" SG_ 2566842094 Hr 5000;
BA_ "GenSigTimeoutTime_ECM_MD1_D" SG_ 2566842094 Hr 5000;
BA_ "GenSigTimeoutTime_DMS" SG_ 2566842094 Hr 5000;
BA_ "GenSigTimeoutTime_DICO" SG_ 2566842094 Hr 5000;
BA_ "GenSigTimeoutTime_BSM_EBS" SG_ 2566842094 Hr 5000;
BA_ "GenSigTimeoutTime_BCM_NBM" SG_ 2566842094 Hr 5000;
BA_ "GenSigTimeoutTime_Av2HP" SG_ 2566842094 Hr 5000;
BA_ "GenSigTimeoutTime_ASM_ELC5_Fr" SG_ 2566842094 Hr 5000;
BA_ "GenSigTimeoutTime_AI_CAID" SG_ 2566842094 Hr 5000;
BA_ "GenSigTimeoutTime_ADCU" SG_ 2566842094 Hr 5000;
BA_ "GenSigTimeoutTime_ACM_CANAIR" SG_ 2566842094 Hr 5000;
BA_ "CI_SigName" SG_ 2566842094 Hr "Hours";
BA_ "CI_SigId" SG_ 2566842094 Hr 697;
BA_ "CI_ParId" SG_ 2566842094 Hr "961";
BA_ "SigType" SG_ 2566842094 Min 1;
BA_ "SPN" SG_ 2566842094 Min 960;
BA_ "GenSigTimeoutTime_VMU" SG_ 2566842094 Min 5000;
BA_ "GenSigTimeoutTime_VCU" SG_ 2566842094 Min 5000;
BA_ "GenSigTimeoutTime_VCM" SG_ 2566842094 Min 5000;
BA_ "GenSigTimeoutTime_TPMS" SG_ 2566842094 Min 5000;
BA_ "GenSigTimeoutTime_SGW2" SG_ 2566842094 Min 5000;
BA_ "GenSigTimeoutTime_SGW" SG_ 2566842094 Min 5000;
BA_ "GenSigTimeoutTime_RM_IRCS" SG_ 2566842094 Min 5000;
BA_ "GenSigTimeoutTime_PCM" SG_ 2566842094 Min 5000;
BA_ "GenSigTimeoutTime_MPPxPTFE2" SG_ 2566842094 Min 5000;
BA_ "GenSigTimeoutTime_MBMS" SG_ 2566842094 Min 5000;
BA_ "GenSigTimeoutTime_INVEM1_ELFA3" SG_ 2566842094 Min 5000;
BA_ "GenSigTimeoutTime_IC_MulticS" SG_ 2566842094 Min 5000;
BA_ "GenSigTimeoutTime_IC_MulticII" SG_ 2566842094 Min 5000;
BA_ "GenSigTimeoutTime_HVPDU_HV_BOX" SG_ 2566842094 Min 5000;
BA_ "GenSigTimeoutTime_FMS_FMS5" SG_ 2566842094 Min 5000;
BA_ "GenSigTimeoutTime_FMS_FMS4" SG_ 2566842094 Min 5000;
BA_ "GenSigTimeoutTime_ETC_Ecolife2" SG_ 2566842094 Min 5000;
BA_ "GenSigTimeoutTime_ECM_MD1_G" SG_ 2566842094 Min 5000;
BA_ "GenSigTimeoutTime_ECM_MD1_D" SG_ 2566842094 Min 5000;
BA_ "GenSigTimeoutTime_DMS" SG_ 2566842094 Min 5000;
BA_ "GenSigTimeoutTime_DICO" SG_ 2566842094 Min 5000;
BA_ "GenSigTimeoutTime_BSM_EBS" SG_ 2566842094 Min 5000;
BA_ "GenSigTimeoutTime_BCM_NBM" SG_ 2566842094 Min 5000;
BA_ "GenSigTimeoutTime_Av2HP" SG_ 2566842094 Min 5000;
BA_ "GenSigTimeoutTime_ASM_ELC5_Fr" SG_ 2566842094 Min 5000;
BA_ "GenSigTimeoutTime_AI_CAID" SG_ 2566842094 Min 5000;
BA_ "GenSigTimeoutTime_ADCU" SG_ 2566842094 Min 5000;
BA_ "GenSigTimeoutTime_ACM_CANAIR" SG_ 2566842094 Min 5000;
BA_ "CI_SigName" SG_ 2566842094 Min "Minutes";
BA_ "CI_SigId" SG_ 2566842094 Min 696;
BA_ "CI_ParId" SG_ 2566842094 Min "960";
BA_ "SigType" SG_ 2566842094 Sec 1;
BA_ "SPN" SG_ 2566842094 Sec 959;
BA_ "GenSigTimeoutTime_VMU" SG_ 2566842094 Sec 5000;
BA_ "GenSigTimeoutTime_VCU" SG_ 2566842094 Sec 5000;
BA_ "GenSigTimeoutTime_VCM" SG_ 2566842094 Sec 5000;
BA_ "GenSigTimeoutTime_TPMS" SG_ 2566842094 Sec 5000;
BA_ "GenSigTimeoutTime_SGW2" SG_ 2566842094 Sec 5000;
BA_ "GenSigTimeoutTime_SGW" SG_ 2566842094 Sec 5000;
BA_ "GenSigTimeoutTime_RM_IRCS" SG_ 2566842094 Sec 5000;
BA_ "GenSigTimeoutTime_PCM" SG_ 2566842094 Sec 5000;
BA_ "GenSigTimeoutTime_MPPxPTFE2" SG_ 2566842094 Sec 5000;
BA_ "GenSigTimeoutTime_MBMS" SG_ 2566842094 Sec 5000;
BA_ "GenSigTimeoutTime_INVEM1_ELFA3" SG_ 2566842094 Sec 5000;
BA_ "GenSigTimeoutTime_IC_MulticS" SG_ 2566842094 Sec 5000;
BA_ "GenSigTimeoutTime_IC_MulticII" SG_ 2566842094 Sec 5000;
BA_ "GenSigTimeoutTime_HVPDU_HV_BOX" SG_ 2566842094 Sec 5000;
BA_ "GenSigTimeoutTime_FMS_FMS5" SG_ 2566842094 Sec 5000;
BA_ "GenSigTimeoutTime_FMS_FMS4" SG_ 2566842094 Sec 5000;
BA_ "GenSigTimeoutTime_ETC_Ecolife2" SG_ 2566842094 Sec 5000;
BA_ "GenSigTimeoutTime_ECM_MD1_G" SG_ 2566842094 Sec 5000;
BA_ "GenSigTimeoutTime_ECM_MD1_D" SG_ 2566842094 Sec 5000;
BA_ "GenSigTimeoutTime_DMS" SG_ 2566842094 Sec 5000;
BA_ "GenSigTimeoutTime_DICO" SG_ 2566842094 Sec 5000;
BA_ "GenSigTimeoutTime_BSM_EBS" SG_ 2566842094 Sec 5000;
BA_ "GenSigTimeoutTime_BCM_NBM" SG_ 2566842094 Sec 5000;
BA_ "GenSigTimeoutTime_Av2HP" SG_ 2566842094 Sec 5000;
BA_ "GenSigTimeoutTime_ASM_ELC5_Fr" SG_ 2566842094 Sec 5000;
BA_ "GenSigTimeoutTime_AI_CAID" SG_ 2566842094 Sec 5000;
BA_ "GenSigTimeoutTime_ADCU" SG_ 2566842094 Sec 5000;
BA_ "GenSigTimeoutTime_ACM_CANAIR" SG_ 2566842094 Sec 5000;
BA_ "CI_SigName" SG_ 2566842094 Sec "Seconds";
BA_ "CI_SigId" SG_ 2566842094 Sec 695;
BA_ "CI_ParId" SG_ 2566842094 Sec "959";
BA_ "GenSigTimeoutTime_SGW" SG_ 2566854213 ApuRedWarn 5000;
BA_ "GenSigTimeoutTime_PCM" SG_ 2566854213 ApuRedWarn 5000;
BA_ "CI_SigName" SG_ 2566854213 ApuRedWarn "APU red warning";
BA_ "CI_SigId" SG_ 2566854213 ApuRedWarn 1846;
BA_ "CI_ParId" SG_ 2566854213 ApuRedWarn "IB740";
BA_ "GenSigTimeoutTime_SGW" SG_ 2566854213 MildhybridStop_StartDeact 5000;
BA_ "GenSigTimeoutTime_PCM" SG_ 2566854213 MildhybridStop_StartDeact 5000;
BA_ "CI_SigName" SG_ 2566854213 MildhybridStop_StartDeact "MildHybrid stop/start deactivation";
BA_ "CI_SigId" SG_ 2566854213 MildhybridStop_StartDeact 1845;
BA_ "CI_ParId" SG_ 2566854213 MildhybridStop_StartDeact "IB739";
BA_ "GenSigTimeoutTime_SGW" SG_ 2566854213 ApuOrangeWarn_ElectrovalvesApuDe 5000;
BA_ "GenSigTimeoutTime_PCM" SG_ 2566854213 ApuOrangeWarn_ElectrovalvesApuDe 5000;
BA_ "CI_SigName" SG_ 2566854213 ApuOrangeWarn_ElectrovalvesApuDe "APU orange warning  / Electrovalves APU default";
BA_ "CI_SigId" SG_ 2566854213 ApuOrangeWarn_ElectrovalvesApuDe 1844;
BA_ "CI_ParId" SG_ 2566854213 ApuOrangeWarn_ElectrovalvesApuDe "IB738";
BA_ "GenSigTimeoutTime_SGW" SG_ 2566854213 OilLevPwrSteerPumpDef 5000;
BA_ "GenSigTimeoutTime_PCM" SG_ 2566854213 OilLevPwrSteerPumpDef 5000;
BA_ "CI_SigName" SG_ 2566854213 OilLevPwrSteerPumpDef "Oil level power steering pump default";
BA_ "CI_SigId" SG_ 2566854213 OilLevPwrSteerPumpDef 1843;
BA_ "CI_ParId" SG_ 2566854213 OilLevPwrSteerPumpDef "IB737";
BA_ "GenSigTimeoutTime_SGW" SG_ 2566854213 OilSepFault 5000;
BA_ "GenSigTimeoutTime_PCM" SG_ 2566854213 OilSepFault 5000;
BA_ "CI_SigName" SG_ 2566854213 OilSepFault "Oil separator fault  ";
BA_ "CI_SigId" SG_ 2566854213 OilSepFault 1842;
BA_ "CI_ParId" SG_ 2566854213 OilSepFault "IB736";
BA_ "GenSigTimeoutTime_SGW" SG_ 2566854213 GasFailElectrovalveN10 5000;
BA_ "GenSigTimeoutTime_PCM" SG_ 2566854213 GasFailElectrovalveN10 5000;
BA_ "CI_SigName" SG_ 2566854213 GasFailElectrovalveN10 "Gas failure - Electrovalve n°10";
BA_ "CI_SigId" SG_ 2566854213 GasFailElectrovalveN10 1841;
BA_ "CI_ParId" SG_ 2566854213 GasFailElectrovalveN10 "IB735";
BA_ "GenSigTimeoutTime_SGW" SG_ 2566854213 GasFailElectrovalveN9 5000;
BA_ "GenSigTimeoutTime_PCM" SG_ 2566854213 GasFailElectrovalveN9 5000;
BA_ "CI_SigName" SG_ 2566854213 GasFailElectrovalveN9 "Gas failure - Electrovalve n°9";
BA_ "CI_SigId" SG_ 2566854213 GasFailElectrovalveN9 1840;
BA_ "CI_ParId" SG_ 2566854213 GasFailElectrovalveN9 "IB734";
BA_ "GenSigTimeoutTime_SGW" SG_ 2566854213 GasFailElectrovalveN8 5000;
BA_ "GenSigTimeoutTime_PCM" SG_ 2566854213 GasFailElectrovalveN8 5000;
BA_ "CI_SigName" SG_ 2566854213 GasFailElectrovalveN8 "Gas failure - Electrovalve n°8";
BA_ "CI_SigId" SG_ 2566854213 GasFailElectrovalveN8 1839;
BA_ "CI_ParId" SG_ 2566854213 GasFailElectrovalveN8 "IB733";
BA_ "GenSigTimeoutTime_SGW" SG_ 2566854213 GasFailElectrovalveN7 5000;
BA_ "GenSigTimeoutTime_PCM" SG_ 2566854213 GasFailElectrovalveN7 5000;
BA_ "CI_SigName" SG_ 2566854213 GasFailElectrovalveN7 "Gas failure - Electrovalve n°7";
BA_ "CI_SigId" SG_ 2566854213 GasFailElectrovalveN7 1838;
BA_ "CI_ParId" SG_ 2566854213 GasFailElectrovalveN7 "IB732";
BA_ "GenSigTimeoutTime_SGW" SG_ 2566854213 GasFailElectrovalveN6 5000;
BA_ "GenSigTimeoutTime_PCM" SG_ 2566854213 GasFailElectrovalveN6 5000;
BA_ "CI_SigName" SG_ 2566854213 GasFailElectrovalveN6 "Gas failure - Electrovalve n°6";
BA_ "CI_SigId" SG_ 2566854213 GasFailElectrovalveN6 1837;
BA_ "CI_ParId" SG_ 2566854213 GasFailElectrovalveN6 "IB731";
BA_ "GenSigTimeoutTime_SGW" SG_ 2566854213 GasFailElectrovalveN5 5000;
BA_ "GenSigTimeoutTime_PCM" SG_ 2566854213 GasFailElectrovalveN5 5000;
BA_ "CI_SigName" SG_ 2566854213 GasFailElectrovalveN5 "Gas failure - Electrovalve n°5";
BA_ "CI_SigId" SG_ 2566854213 GasFailElectrovalveN5 1836;
BA_ "CI_ParId" SG_ 2566854213 GasFailElectrovalveN5 "IB730";
BA_ "GenSigTimeoutTime_SGW" SG_ 2566854213 GasFailElectrovalveN4 5000;
BA_ "GenSigTimeoutTime_PCM" SG_ 2566854213 GasFailElectrovalveN4 5000;
BA_ "CI_SigName" SG_ 2566854213 GasFailElectrovalveN4 "Gas failure - Electrovalve n°4";
BA_ "CI_SigId" SG_ 2566854213 GasFailElectrovalveN4 1835;
BA_ "CI_ParId" SG_ 2566854213 GasFailElectrovalveN4 "IB729";
BA_ "GenSigTimeoutTime_SGW" SG_ 2566854213 GasFailElectrovalveN3 5000;
BA_ "GenSigTimeoutTime_PCM" SG_ 2566854213 GasFailElectrovalveN3 5000;
BA_ "CI_SigName" SG_ 2566854213 GasFailElectrovalveN3 "Gas failure - Electrovalve n°3";
BA_ "CI_SigId" SG_ 2566854213 GasFailElectrovalveN3 1834;
BA_ "CI_ParId" SG_ 2566854213 GasFailElectrovalveN3 "IB728";
BA_ "GenSigTimeoutTime_SGW" SG_ 2566854213 GasFailElectrovalveN2 5000;
BA_ "GenSigTimeoutTime_PCM" SG_ 2566854213 GasFailElectrovalveN2 5000;
BA_ "CI_SigName" SG_ 2566854213 GasFailElectrovalveN2 "Gas failure - Electrovalve n°2";
BA_ "CI_SigId" SG_ 2566854213 GasFailElectrovalveN2 1833;
BA_ "CI_ParId" SG_ 2566854213 GasFailElectrovalveN2 "IB727";
BA_ "GenSigTimeoutTime_SGW" SG_ 2566854213 GasFailElectrovalveN1 5000;
BA_ "GenSigTimeoutTime_PCM" SG_ 2566854213 GasFailElectrovalveN1 5000;
BA_ "CI_SigName" SG_ 2566854213 GasFailElectrovalveN1 "Gas failure - Electrovalve n°1 ";
BA_ "CI_SigId" SG_ 2566854213 GasFailElectrovalveN1 1832;
BA_ "CI_ParId" SG_ 2566854213 GasFailElectrovalveN1 "IB726";
BA_ "GenSigTimeoutTime_SGW" SG_ 2566854213 ElectrovalveGasFail 5000;
BA_ "GenSigTimeoutTime_PCM" SG_ 2566854213 ElectrovalveGasFail 5000;
BA_ "CI_SigName" SG_ 2566854213 ElectrovalveGasFail "Electrovalve Gas failure";
BA_ "CI_SigId" SG_ 2566854213 ElectrovalveGasFail 1831;
BA_ "CI_ParId" SG_ 2566854213 ElectrovalveGasFail "IB725";
BA_ "GenSigTimeoutTime_SGW" SG_ 2566854213 GasTempSensFail 5000;
BA_ "GenSigTimeoutTime_PCM" SG_ 2566854213 GasTempSensFail 5000;
BA_ "CI_SigName" SG_ 2566854213 GasTempSensFail "Gas temperature sensor failed";
BA_ "CI_SigId" SG_ 2566854213 GasTempSensFail 1830;
BA_ "CI_ParId" SG_ 2566854213 GasTempSensFail "IB724";
BA_ "GenSigTimeoutTime_SGW" SG_ 2566854213 GasRefuelingGateOpen 5000;
BA_ "GenSigTimeoutTime_PCM" SG_ 2566854213 GasRefuelingGateOpen 5000;
BA_ "CI_SigName" SG_ 2566854213 GasRefuelingGateOpen "Gas refueling gate open";
BA_ "CI_SigId" SG_ 2566854213 GasRefuelingGateOpen 1829;
BA_ "CI_ParId" SG_ 2566854213 GasRefuelingGateOpen "IB723";
BA_ "GenSigTimeoutTime_SGW" SG_ 2566854213 GasTempTooHigh 5000;
BA_ "GenSigTimeoutTime_PCM" SG_ 2566854213 GasTempTooHigh 5000;
BA_ "CI_SigName" SG_ 2566854213 GasTempTooHigh "Gas  temperature  too high ";
BA_ "CI_SigId" SG_ 2566854213 GasTempTooHigh 1828;
BA_ "CI_ParId" SG_ 2566854213 GasTempTooHigh "IB722";
BA_ "GenSigTimeoutTime_SGW" SG_ 2566854213 AutoOilDef 5000;
BA_ "GenSigTimeoutTime_PCM" SG_ 2566854213 AutoOilDef 5000;
BA_ "CI_SigName" SG_ 2566854213 AutoOilDef "Automatic oil default";
BA_ "CI_SigId" SG_ 2566854213 AutoOilDef 1827;
BA_ "CI_ParId" SG_ 2566854213 AutoOilDef "IB721";
BA_ "GenSigTimeoutTime_SGW" SG_ 2566854213 DefPompeDosMod 5000;
BA_ "GenSigTimeoutTime_PCM" SG_ 2566854213 DefPompeDosMod 5000;
BA_ "CI_SigName" SG_ 2566854213 DefPompeDosMod "Default Pompe Dosing Module";
BA_ "CI_SigId" SG_ 2566854213 DefPompeDosMod 1826;
BA_ "CI_ParId" SG_ 2566854213 DefPompeDosMod "IB720";
BA_ "GenSigTimeoutTime_SGW" SG_ 2566854213 AcComprSts 5000;
BA_ "GenSigTimeoutTime_PCM" SG_ 2566854213 AcComprSts 5000;
BA_ "CI_SigName" SG_ 2566854213 AcComprSts "Air Conditioner compressor status";
BA_ "CI_SigId" SG_ 2566854213 AcComprSts 1825;
BA_ "CI_ParId" SG_ 2566854213 AcComprSts "IB719";
BA_ "GenSigTimeoutTime_SGW" SG_ 2566854213 AcFault 5000;
BA_ "GenSigTimeoutTime_PCM" SG_ 2566854213 AcFault 5000;
BA_ "CI_SigName" SG_ 2566854213 AcFault "Air conditioner fault";
BA_ "CI_SigId" SG_ 2566854213 AcFault 1824;
BA_ "CI_ParId" SG_ 2566854213 AcFault "IB718";
BA_ "GenSigTimeoutTime_SGW" SG_ 2566854213 AcOn 5000;
BA_ "GenSigTimeoutTime_PCM" SG_ 2566854213 AcOn 5000;
BA_ "CI_SigName" SG_ 2566854213 AcOn "Air Conditioner On";
BA_ "CI_SigId" SG_ 2566854213 AcOn 1823;
BA_ "CI_ParId" SG_ 2566854213 AcOn "IB717";
BA_ "GenSigTimeoutTime_SGW" SG_ 2566854213 DrivAcFault 5000;
BA_ "GenSigTimeoutTime_PCM" SG_ 2566854213 DrivAcFault 5000;
BA_ "CI_SigName" SG_ 2566854213 DrivAcFault "Driver Air Conditioner fault";
BA_ "CI_SigId" SG_ 2566854213 DrivAcFault 1822;
BA_ "CI_ParId" SG_ 2566854213 DrivAcFault "IB716";
BA_ "GenSigTimeoutTime_SGW" SG_ 2566854213 DrivAcOn 5000;
BA_ "GenSigTimeoutTime_PCM" SG_ 2566854213 DrivAcOn 5000;
BA_ "CI_SigName" SG_ 2566854213 DrivAcOn "Driver Air Conditioner On";
BA_ "CI_SigId" SG_ 2566854213 DrivAcOn 1821;
BA_ "CI_ParId" SG_ 2566854213 DrivAcOn "IB715";
BA_ "GenSigTimeoutTime_SGW" SG_ 2566854213 FuelFiltClogDef 5000;
BA_ "GenSigTimeoutTime_PCM" SG_ 2566854213 FuelFiltClogDef 5000;
BA_ "CI_SigName" SG_ 2566854213 FuelFiltClogDef "Fuel Filter clogged default";
BA_ "CI_SigId" SG_ 2566854213 FuelFiltClogDef 1820;
BA_ "CI_ParId" SG_ 2566854213 FuelFiltClogDef "IB714";
BA_ "GenSigTimeoutTime_SGW" SG_ 2566854213 EngOilLowLev 5000;
BA_ "GenSigTimeoutTime_PCM" SG_ 2566854213 EngOilLowLev 5000;
BA_ "CI_SigName" SG_ 2566854213 EngOilLowLev "Engine oil low level";
BA_ "CI_SigId" SG_ 2566854213 EngOilLowLev 1819;
BA_ "CI_ParId" SG_ 2566854213 EngOilLowLev "IB713";
BA_ "GenSigTimeoutTime_SGW" SG_ 2566854213 EngAirFiltClogDef 5000;
BA_ "GenSigTimeoutTime_PCM" SG_ 2566854213 EngAirFiltClogDef 5000;
BA_ "CI_SigName" SG_ 2566854213 EngAirFiltClogDef "Engine air filter clogged default";
BA_ "CI_SigId" SG_ 2566854213 EngAirFiltClogDef 1818;
BA_ "CI_ParId" SG_ 2566854213 EngAirFiltClogDef "IB712";
BA_ "GenSigTimeoutTime_SGW" SG_ 2566854213 LowLevEngCoolRefr 5000;
BA_ "GenSigTimeoutTime_PCM" SG_ 2566854213 LowLevEngCoolRefr 5000;
BA_ "CI_SigName" SG_ 2566854213 LowLevEngCoolRefr "Low level engine cooling refrigerant";
BA_ "CI_SigId" SG_ 2566854213 LowLevEngCoolRefr 1817;
BA_ "CI_ParId" SG_ 2566854213 LowLevEngCoolRefr "IB711";
BA_ "GenSigTimeoutTime_SGW" SG_ 2566854213 VehSpeedSigDef 5000;
BA_ "GenSigTimeoutTime_PCM" SG_ 2566854213 VehSpeedSigDef 5000;
BA_ "CI_SigName" SG_ 2566854213 VehSpeedSigDef "Vehicle Speed signal default";
BA_ "CI_SigId" SG_ 2566854213 VehSpeedSigDef 1816;
BA_ "CI_ParId" SG_ 2566854213 VehSpeedSigDef "IB710";
BA_ "GenSigTimeoutTime_SGW" SG_ 2566854213 CaidLeadenBtnSts 5000;
BA_ "GenSigTimeoutTime_PCM" SG_ 2566854213 CaidLeadenBtnSts 5000;
BA_ "CI_SigName" SG_ 2566854213 CaidLeadenBtnSts "CAID Leaden button Status";
BA_ "CI_SigId" SG_ 2566854213 CaidLeadenBtnSts 1815;
BA_ "CI_ParId" SG_ 2566854213 CaidLeadenBtnSts "IB709";
BA_ "GenSigTimeoutTime_SGW" SG_ 2566854213 DrlLightDef 5000;
BA_ "GenSigTimeoutTime_PCM" SG_ 2566854213 DrlLightDef 5000;
BA_ "CI_SigName" SG_ 2566854213 DrlLightDef "DRL lights default";
BA_ "CI_SigId" SG_ 2566854213 DrlLightDef 1814;
BA_ "CI_ParId" SG_ 2566854213 DrlLightDef "IB708";
BA_ "GenSigTimeoutTime_SGW" SG_ 2566854213 PavillonRightTurnLightDef 5000;
BA_ "GenSigTimeoutTime_PCM" SG_ 2566854213 PavillonRightTurnLightDef 5000;
BA_ "CI_SigName" SG_ 2566854213 PavillonRightTurnLightDef "Pavillon right turn light default";
BA_ "CI_SigId" SG_ 2566854213 PavillonRightTurnLightDef 1813;
BA_ "CI_ParId" SG_ 2566854213 PavillonRightTurnLightDef "IB707";
BA_ "GenSigTimeoutTime_SGW" SG_ 2566854213 PavillonLeftTurnLightDef 5000;
BA_ "GenSigTimeoutTime_PCM" SG_ 2566854213 PavillonLeftTurnLightDef 5000;
BA_ "CI_SigName" SG_ 2566854213 PavillonLeftTurnLightDef "Pavillon left turn light default";
BA_ "CI_SigId" SG_ 2566854213 PavillonLeftTurnLightDef 1812;
BA_ "CI_ParId" SG_ 2566854213 PavillonLeftTurnLightDef "IB706";
BA_ "GenSigTimeoutTime_SGW" SG_ 2566854213 LatRightTurnLightDef 5000;
BA_ "GenSigTimeoutTime_PCM" SG_ 2566854213 LatRightTurnLightDef 5000;
BA_ "CI_SigName" SG_ 2566854213 LatRightTurnLightDef "Lateral right turn light default";
BA_ "CI_SigId" SG_ 2566854213 LatRightTurnLightDef 1811;
BA_ "CI_ParId" SG_ 2566854213 LatRightTurnLightDef "IB705";
BA_ "GenSigTimeoutTime_SGW" SG_ 2566854213 LatLeftTurnLightDef 5000;
BA_ "GenSigTimeoutTime_PCM" SG_ 2566854213 LatLeftTurnLightDef 5000;
BA_ "CI_SigName" SG_ 2566854213 LatLeftTurnLightDef "Lateral left turn light default";
BA_ "CI_SigId" SG_ 2566854213 LatLeftTurnLightDef 1810;
BA_ "CI_ParId" SG_ 2566854213 LatLeftTurnLightDef "IB704";
BA_ "GenSigTimeoutTime_SGW" SG_ 2566854213 RearRightTurnLightDef 5000;
BA_ "GenSigTimeoutTime_PCM" SG_ 2566854213 RearRightTurnLightDef 5000;
BA_ "CI_SigName" SG_ 2566854213 RearRightTurnLightDef "Rear right turn light default";
BA_ "CI_SigId" SG_ 2566854213 RearRightTurnLightDef 1809;
BA_ "CI_ParId" SG_ 2566854213 RearRightTurnLightDef "IB703";
BA_ "GenSigTimeoutTime_SGW" SG_ 2566854213 RearLeftTurnLightDef 5000;
BA_ "GenSigTimeoutTime_PCM" SG_ 2566854213 RearLeftTurnLightDef 5000;
BA_ "CI_SigName" SG_ 2566854213 RearLeftTurnLightDef "Rear left turn light default";
BA_ "CI_SigId" SG_ 2566854213 RearLeftTurnLightDef 1808;
BA_ "CI_ParId" SG_ 2566854213 RearLeftTurnLightDef "IB702";
BA_ "GenSigTimeoutTime_SGW" SG_ 2566854213 RearFogLightDef 5000;
BA_ "GenSigTimeoutTime_PCM" SG_ 2566854213 RearFogLightDef 5000;
BA_ "CI_SigName" SG_ 2566854213 RearFogLightDef "Rear fog light default";
BA_ "CI_SigId" SG_ 2566854213 RearFogLightDef 1807;
BA_ "CI_ParId" SG_ 2566854213 RearFogLightDef "IB701";
BA_ "GenSigTimeoutTime_SGW" SG_ 2566854213 FaRFogLightDef 5000;
BA_ "GenSigTimeoutTime_PCM" SG_ 2566854213 FaRFogLightDef 5000;
BA_ "CI_SigName" SG_ 2566854213 FaRFogLightDef "Right front fog light default";
BA_ "CI_SigId" SG_ 2566854213 FaRFogLightDef 1806;
BA_ "CI_ParId" SG_ 2566854213 FaRFogLightDef "IB700";
BA_ "GenSigTimeoutTime_SGW" SG_ 2566854213 FaLFogLightDef 5000;
BA_ "GenSigTimeoutTime_PCM" SG_ 2566854213 FaLFogLightDef 5000;
BA_ "CI_SigName" SG_ 2566854213 FaLFogLightDef "Left front fog light default";
BA_ "CI_SigId" SG_ 2566854213 FaLFogLightDef 1805;
BA_ "CI_ParId" SG_ 2566854213 FaLFogLightDef "IB699";
BA_ "GenSigTimeoutTime_SGW" SG_ 2566854213 RearPosLightDef 5000;
BA_ "GenSigTimeoutTime_PCM" SG_ 2566854213 RearPosLightDef 5000;
BA_ "CI_SigName" SG_ 2566854213 RearPosLightDef "Rear position light default";
BA_ "CI_SigId" SG_ 2566854213 RearPosLightDef 1804;
BA_ "CI_ParId" SG_ 2566854213 RearPosLightDef "IB698";
BA_ "GenSigTimeoutTime_SGW" SG_ 2566854213 RearPavillonPosLightDef 5000;
BA_ "GenSigTimeoutTime_PCM" SG_ 2566854213 RearPavillonPosLightDef 5000;
BA_ "CI_SigName" SG_ 2566854213 RearPavillonPosLightDef "Rear pavillon position light default";
BA_ "CI_SigId" SG_ 2566854213 RearPavillonPosLightDef 1803;
BA_ "CI_ParId" SG_ 2566854213 RearPavillonPosLightDef "IB697";
BA_ "GenSigTimeoutTime_SGW" SG_ 2566854213 FrontRightTurnLightDef 5000;
BA_ "GenSigTimeoutTime_PCM" SG_ 2566854213 FrontRightTurnLightDef 5000;
BA_ "CI_SigName" SG_ 2566854213 FrontRightTurnLightDef "Front right turn light default";
BA_ "CI_SigId" SG_ 2566854213 FrontRightTurnLightDef 1802;
BA_ "CI_ParId" SG_ 2566854213 FrontRightTurnLightDef "IB696";
BA_ "GenSigTimeoutTime_SGW" SG_ 2566854213 FrontLeftTurnLightDef 5000;
BA_ "GenSigTimeoutTime_PCM" SG_ 2566854213 FrontLeftTurnLightDef 5000;
BA_ "CI_SigName" SG_ 2566854213 FrontLeftTurnLightDef "Front left turn light default";
BA_ "CI_SigId" SG_ 2566854213 FrontLeftTurnLightDef 1801;
BA_ "CI_ParId" SG_ 2566854213 FrontLeftTurnLightDef "IB695";
BA_ "GenSigTimeoutTime_SGW" SG_ 2566854213 RightLowBeamLightDef 5000;
BA_ "GenSigTimeoutTime_PCM" SG_ 2566854213 RightLowBeamLightDef 5000;
BA_ "CI_SigName" SG_ 2566854213 RightLowBeamLightDef "Right low beam light default";
BA_ "CI_SigId" SG_ 2566854213 RightLowBeamLightDef 1800;
BA_ "CI_ParId" SG_ 2566854213 RightLowBeamLightDef "IB694";
BA_ "GenSigTimeoutTime_SGW" SG_ 2566854213 LeftLowBeamLightDef 5000;
BA_ "GenSigTimeoutTime_PCM" SG_ 2566854213 LeftLowBeamLightDef 5000;
BA_ "CI_SigName" SG_ 2566854213 LeftLowBeamLightDef "Left low beam light default";
BA_ "CI_SigId" SG_ 2566854213 LeftLowBeamLightDef 1799;
BA_ "CI_ParId" SG_ 2566854213 LeftLowBeamLightDef "IB693";
BA_ "GenSigTimeoutTime_SGW" SG_ 2566854213 RightHighBeamLightDef 5000;
BA_ "GenSigTimeoutTime_PCM" SG_ 2566854213 RightHighBeamLightDef 5000;
BA_ "CI_SigName" SG_ 2566854213 RightHighBeamLightDef "Right high beam light default";
BA_ "CI_SigId" SG_ 2566854213 RightHighBeamLightDef 1798;
BA_ "CI_ParId" SG_ 2566854213 RightHighBeamLightDef "IB692";
BA_ "GenSigTimeoutTime_SGW" SG_ 2566854213 LeftHighBeamLightDef 5000;
BA_ "GenSigTimeoutTime_PCM" SG_ 2566854213 LeftHighBeamLightDef 5000;
BA_ "CI_SigName" SG_ 2566854213 LeftHighBeamLightDef "Left high beam light default";
BA_ "CI_SigId" SG_ 2566854213 LeftHighBeamLightDef 1797;
BA_ "CI_ParId" SG_ 2566854213 LeftHighBeamLightDef "IB691";
BA_ "GenSigTimeoutTime_SGW" SG_ 2566854213 RevLightDef 5000;
BA_ "GenSigTimeoutTime_PCM" SG_ 2566854213 RevLightDef 5000;
BA_ "CI_SigName" SG_ 2566854213 RevLightDef "Reversing lights default";
BA_ "CI_SigId" SG_ 2566854213 RevLightDef 1796;
BA_ "CI_ParId" SG_ 2566854213 RevLightDef "IB690";
BA_ "GenSigTimeoutTime_SGW" SG_ 2566854213 StopLightDef 5000;
BA_ "GenSigTimeoutTime_PCM" SG_ 2566854213 StopLightDef 5000;
BA_ "CI_SigName" SG_ 2566854213 StopLightDef "Stop lights default";
BA_ "CI_SigId" SG_ 2566854213 StopLightDef 1795;
BA_ "CI_ParId" SG_ 2566854213 StopLightDef "IB689";
BA_ "GenSigTimeoutTime_SGW" SG_ 2566854213 FireOngoing 5000;
BA_ "GenSigTimeoutTime_PCM" SG_ 2566854213 FireOngoing 5000;
BA_ "CI_SigName" SG_ 2566854213 FireOngoing "Fire ongoing ";
BA_ "CI_SigId" SG_ 2566854213 FireOngoing 1794;
BA_ "CI_ParId" SG_ 2566854213 FireOngoing "IB688";
BA_ "GenSigTimeoutTime_SGW" SG_ 2566854213 Overheating_RiskOfFire 5000;
BA_ "GenSigTimeoutTime_PCM" SG_ 2566854213 Overheating_RiskOfFire 5000;
BA_ "CI_SigName" SG_ 2566854213 Overheating_RiskOfFire "Overheating / Risk of Fire";
BA_ "CI_SigId" SG_ 2566854213 Overheating_RiskOfFire 1793;
BA_ "CI_ParId" SG_ 2566854213 Overheating_RiskOfFire "IB687";
BA_ "GenSigTimeoutTime_SGW" SG_ 2566854213 FireExtinctionFaulty 5000;
BA_ "GenSigTimeoutTime_PCM" SG_ 2566854213 FireExtinctionFaulty 5000;
BA_ "CI_SigName" SG_ 2566854213 FireExtinctionFaulty "Fire extinction faulty";
BA_ "CI_SigId" SG_ 2566854213 FireExtinctionFaulty 1792;
BA_ "CI_ParId" SG_ 2566854213 FireExtinctionFaulty "IB686";
BA_ "GenSigTimeoutTime_SGW" SG_ 2566854213 AirPrsMidBrkCircDef 5000;
BA_ "GenSigTimeoutTime_PCM" SG_ 2566854213 AirPrsMidBrkCircDef 5000;
BA_ "CI_SigName" SG_ 2566854213 AirPrsMidBrkCircDef "Air pressure middle brake circuit  default";
BA_ "CI_SigId" SG_ 2566854213 AirPrsMidBrkCircDef 1791;
BA_ "CI_ParId" SG_ 2566854213 AirPrsMidBrkCircDef "IB685";
BA_ "GenSigTimeoutTime_SGW" SG_ 2566854213 AirPrsServitudeCircDef 5000;
BA_ "GenSigTimeoutTime_PCM" SG_ 2566854213 AirPrsServitudeCircDef 5000;
BA_ "CI_SigName" SG_ 2566854213 AirPrsServitudeCircDef "Air pressure servitude circuit default";
BA_ "CI_SigId" SG_ 2566854213 AirPrsServitudeCircDef 1790;
BA_ "CI_ParId" SG_ 2566854213 AirPrsServitudeCircDef "IB684";
BA_ "GenSigTimeoutTime_SGW" SG_ 2566854213 AirPrsParkBrkCircDef 5000;
BA_ "GenSigTimeoutTime_PCM" SG_ 2566854213 AirPrsParkBrkCircDef 5000;
BA_ "CI_SigName" SG_ 2566854213 AirPrsParkBrkCircDef "Air pressure park brake circuit default";
BA_ "CI_SigId" SG_ 2566854213 AirPrsParkBrkCircDef 1789;
BA_ "CI_ParId" SG_ 2566854213 AirPrsParkBrkCircDef "IB683";
BA_ "GenSigTimeoutTime_SGW" SG_ 2566854213 AirPrsFrontBrkCircDef 5000;
BA_ "GenSigTimeoutTime_PCM" SG_ 2566854213 AirPrsFrontBrkCircDef 5000;
BA_ "CI_SigName" SG_ 2566854213 AirPrsFrontBrkCircDef "Air pressure front brake circuit  default";
BA_ "CI_SigId" SG_ 2566854213 AirPrsFrontBrkCircDef 1788;
BA_ "CI_ParId" SG_ 2566854213 AirPrsFrontBrkCircDef "IB682";
BA_ "GenSigTimeoutTime_SGW" SG_ 2566854213 AirPrsRearBrkCircDef 5000;
BA_ "GenSigTimeoutTime_PCM" SG_ 2566854213 AirPrsRearBrkCircDef 5000;
BA_ "CI_SigName" SG_ 2566854213 AirPrsRearBrkCircDef "Air pressure rear brake circuit  default";
BA_ "CI_SigId" SG_ 2566854213 AirPrsRearBrkCircDef 1787;
BA_ "CI_ParId" SG_ 2566854213 AirPrsRearBrkCircDef "IB681";
BA_ "GenSigTimeoutTime_SGW" SG_ 2566854213 Ramp_Whchair_LiftFail 5000;
BA_ "GenSigTimeoutTime_PCM" SG_ 2566854213 Ramp_Whchair_LiftFail 5000;
BA_ "CI_SigName" SG_ 2566854213 Ramp_Whchair_LiftFail "Ramp/wheelchair/lift  failure";
BA_ "CI_SigId" SG_ 2566854213 Ramp_Whchair_LiftFail 1786;
BA_ "CI_ParId" SG_ 2566854213 Ramp_Whchair_LiftFail "IB680";
BA_ "GenSigTimeoutTime_SGW" SG_ 2566854213 FailOnRampSensitiveEdge_Step 5000;
BA_ "GenSigTimeoutTime_PCM" SG_ 2566854213 FailOnRampSensitiveEdge_Step 5000;
BA_ "CI_SigName" SG_ 2566854213 FailOnRampSensitiveEdge_Step "Failure on ramp sensitive edge/step";
BA_ "CI_SigId" SG_ 2566854213 FailOnRampSensitiveEdge_Step 1785;
BA_ "CI_ParId" SG_ 2566854213 FailOnRampSensitiveEdge_Step "IB679";
BA_ "GenSigTimeoutTime_SGW" SG_ 2566854213 DoorsSecurModeDeactivated 5000;
BA_ "GenSigTimeoutTime_PCM" SG_ 2566854213 DoorsSecurModeDeactivated 5000;
BA_ "CI_SigName" SG_ 2566854213 DoorsSecurModeDeactivated "Doors security mode deactivated";
BA_ "CI_SigId" SG_ 2566854213 DoorsSecurModeDeactivated 1784;
BA_ "CI_ParId" SG_ 2566854213 DoorsSecurModeDeactivated "IB678";
BA_ "SigType" SG_ 2566858309 EmbeddedEnergy 1;
BA_ "GenSigTimeoutTime_SGW" SG_ 2566858309 EmbeddedEnergy 5000;
BA_ "GenSigTimeoutTime_PCM" SG_ 2566858309 EmbeddedEnergy 5000;
BA_ "CI_SigName" SG_ 2566858309 EmbeddedEnergy "Embedded Energy";
BA_ "CI_SigId" SG_ 2566858309 EmbeddedEnergy 1859;
BA_ "CI_ParId" SG_ 2566858309 EmbeddedEnergy "IB752";
BA_ "GenSigTimeoutTime_SGW" SG_ 2566858309 HeatOnFullElec 5000;
BA_ "GenSigTimeoutTime_PCM" SG_ 2566858309 HeatOnFullElec 5000;
BA_ "CI_SigName" SG_ 2566858309 HeatOnFullElec "Heating On - Full Elec";
BA_ "CI_SigId" SG_ 2566858309 HeatOnFullElec 1858;
BA_ "CI_ParId" SG_ 2566858309 HeatOnFullElec "IB751";
BA_ "GenSigTimeoutTime_SGW" SG_ 2566858309 CanPwr3FaultFullElec 5000;
BA_ "GenSigTimeoutTime_PCM" SG_ 2566858309 CanPwr3FaultFullElec 5000;
BA_ "CI_SigName" SG_ 2566858309 CanPwr3FaultFullElec "CAN POWER 3 fault - Full Elec";
BA_ "CI_SigId" SG_ 2566858309 CanPwr3FaultFullElec 1857;
BA_ "CI_ParId" SG_ 2566858309 CanPwr3FaultFullElec "IB750";
BA_ "GenSigTimeoutTime_SGW" SG_ 2566858309 LowPwrSupplyLevFullElec 5000;
BA_ "GenSigTimeoutTime_PCM" SG_ 2566858309 LowPwrSupplyLevFullElec 5000;
BA_ "CI_SigName" SG_ 2566858309 LowPwrSupplyLevFullElec "Low power supply  level - Full Elec";
BA_ "CI_SigId" SG_ 2566858309 LowPwrSupplyLevFullElec 1856;
BA_ "CI_ParId" SG_ 2566858309 LowPwrSupplyLevFullElec "IB749";
BA_ "GenSigTimeoutTime_SGW" SG_ 2566858309 ChgIncident_InServOpportunityChg 5000;
BA_ "GenSigTimeoutTime_PCM" SG_ 2566858309 ChgIncident_InServOpportunityChg 5000;
BA_ "CI_SigName" SG_ 2566858309 ChgIncident_InServOpportunityChg "Charging incident – In service Opportunity charging - Full Elec";
BA_ "CI_SigId" SG_ 2566858309 ChgIncident_InServOpportunityChg 1855;
BA_ "CI_ParId" SG_ 2566858309 ChgIncident_InServOpportunityChg "IB748";
BA_ "GenSigTimeoutTime_SGW" SG_ 2566858309 ChgIncident_OvernightModeFullEle 5000;
BA_ "GenSigTimeoutTime_PCM" SG_ 2566858309 ChgIncident_OvernightModeFullEle 5000;
BA_ "CI_SigName" SG_ 2566858309 ChgIncident_OvernightModeFullEle "Charging incident – Overnight mode - Full Elec";
BA_ "CI_SigId" SG_ 2566858309 ChgIncident_OvernightModeFullEle 1854;
BA_ "CI_ParId" SG_ 2566858309 ChgIncident_OvernightModeFullEle "IB747";
BA_ "SigType" SG_ 2566858309 VehStsOnDrivMode 4;
BA_ "GenSigTimeoutTime_SGW" SG_ 2566858309 VehStsOnDrivMode 5000;
BA_ "GenSigTimeoutTime_PCM" SG_ 2566858309 VehStsOnDrivMode 5000;
BA_ "CI_SigName" SG_ 2566858309 VehStsOnDrivMode "Vehicle state on drive mode ";
BA_ "CI_SigId" SG_ 2566858309 VehStsOnDrivMode 1853;
BA_ "CI_ParId" SG_ 2566858309 VehStsOnDrivMode "IB746";
BA_ "SigType" SG_ 2566858309 EnergyInstantElPwr 1;
BA_ "GenSigTimeoutTime_SGW" SG_ 2566858309 EnergyInstantElPwr 5000;
BA_ "GenSigTimeoutTime_PCM" SG_ 2566858309 EnergyInstantElPwr 5000;
BA_ "GenSigStartValue" SG_ 2566858309 EnergyInstantElPwr 125;
BA_ "CI_SigName" SG_ 2566858309 EnergyInstantElPwr "Energy Instant Electric Power";
BA_ "CI_SigId" SG_ 2566858309 EnergyInstantElPwr 1852;
BA_ "CI_ParId" SG_ 2566858309 EnergyInstantElPwr "IB745";
BA_ "SigType" SG_ 2566858309 RngFullElec 1;
BA_ "GenSigTimeoutTime_VMU" SG_ 2566858309 RngFullElec 5000;
BA_ "GenSigTimeoutTime_SGW" SG_ 2566858309 RngFullElec 5000;
BA_ "GenSigTimeoutTime_PCM" SG_ 2566858309 RngFullElec 5000;
BA_ "CI_SigName" SG_ 2566858309 RngFullElec "Range -  Full Elec";
BA_ "CI_SigId" SG_ 2566858309 RngFullElec 1851;
BA_ "CI_ParId" SG_ 2566858309 RngFullElec "IB744";
BA_ "SigType" SG_ 2566858309 InternVehTempTr 1;
BA_ "GenSigTimeoutTime_SGW" SG_ 2566858309 InternVehTempTr 5000;
BA_ "GenSigTimeoutTime_PCM" SG_ 2566858309 InternVehTempTr 5000;
BA_ "GenSigStartValue" SG_ 2566858309 InternVehTempTr 40;
BA_ "CI_SigName" SG_ 2566858309 InternVehTempTr "Internal vehicle temperature (trailer)";
BA_ "CI_SigId" SG_ 2566858309 InternVehTempTr 1850;
BA_ "CI_ParId" SG_ 2566858309 InternVehTempTr "IB743";
BA_ "SigType" SG_ 2566858309 InternVehTemp 1;
BA_ "GenSigTimeoutTime_SGW" SG_ 2566858309 InternVehTemp 5000;
BA_ "GenSigTimeoutTime_PCM" SG_ 2566858309 InternVehTemp 5000;
BA_ "GenSigStartValue" SG_ 2566858309 InternVehTemp 40;
BA_ "CI_SigName" SG_ 2566858309 InternVehTemp "Internal vehicle temperature";
BA_ "CI_SigId" SG_ 2566858309 InternVehTemp 1849;
BA_ "CI_ParId" SG_ 2566858309 InternVehTemp "IB742";
BA_ "SigType" SG_ 2566858309 ExtTemp 1;
BA_ "GenSigTimeoutTime_SGW" SG_ 2566858309 ExtTemp 5000;
BA_ "GenSigTimeoutTime_PCM" SG_ 2566858309 ExtTemp 5000;
BA_ "GenSigStartValue" SG_ 2566858309 ExtTemp 40;
BA_ "CI_SigName" SG_ 2566858309 ExtTemp "External temperature";
BA_ "CI_SigId" SG_ 2566858309 ExtTemp 1848;
BA_ "CI_ParId" SG_ 2566858309 ExtTemp "IB741";
VAL_ 2566907443 TyrePrsSts 0 "Nominal pressure range" 1 "ECO overpressure (Future Use)" 2 "Over pressure (Future Use)" 3 "Extr. overpressure (Future Use)" 4 "ECO underpressure (Future Use)" 5 "Under pressure" 6 "Extreme under pressure" 13 "Signal Not Supported" 14 "Error" 15 "Signal Not Available" ;
VAL_ 2566907443 BatSts 0 "Not Supported" 1 "< 10% NOK" 2 "20%" 3 "30%" 4 "40%" 5 "50%" 6 "60%" 7 "70%" 8 "80%" 9 "90%" 10 "100%" 11 "Battery OK > 100%" 12 "Reserved" 13 "Reserved" 14 "Reserved" 15 "Invalid / Error" ;
VAL_ 2566907443 TyrePrs 1019 "Signal Not Supported" 1020 "Reserved for future use" 1021 "Reserved for future use" 1022 "Error" 1023 "Not Available" ;
VAL_ 2566867182 SignifTimeOverlapInUsedDrivActiv 0 "no significant time overlaps" 1 "significant time overlap" 2 "Error indicator" 3 "Not Available" ;
VAL_ 2566867182 MultiManningCurShift 0 "Single driver for current shift" 1 "Multi-manning for current shift" 2 "Error indicator" 3 "Not Available" ;
VAL_ 2566867182 WeekRestPerCalcEna 0 "Disabled" 1 "Enabled" 2 "Error indicator" 3 "Not Available" ;
VAL_ 2566867182 NoSuffDataOnTheDrivCard 0 "Sufficient data" 1 "No sufficient data" 2 "Error indicator" 3 "Not Available" ;
VAL_ 2566867182 UnknownPer 0 "No UNKNOWN periods" 1 "At least one UNKNOWN period" 2 "Error indicator" 3 "Not Available or not installed" ;
VAL_ 2566867182 RemReducDayRestPer 4 "Reserved" 5 "Reserved" 6 "Error indicator" 7 "Not Available" ;
VAL_ 2566867182 Rem10HDrivTimes 3 "Reserved" 4 "Reserved" 5 "Reserved" 6 "Error indicator" 7 "Not Available" ;
VAL_ 2566867438 NextBreak_RestExByAComp 0 "Nt extended by a compensation" 1 "Extendedby a compensation" 2 "Error indicator" 3 "Not Available" ;
VAL_ 2566867438 TypeOfNextBreak_Rest 1 "Driving interruption of 45 min" 2 "Driving interruption of 30 min" 17 "Reduced daily rest period" 18 "Regular daily rest period" 19 "Split regular daily rest, part 2" 20 "Multi-manning daily rest period" 33 "Reduced weekly rest period" 34 "Regular weekly rest period" 62 "Error indicator" 63 "Not Available" ;
VAL_ 2566867694 LwAssignReducWeekRestPer 14 "Error indicator" 15 "Not Available" ;
VAL_ 2566867694 LwAssignRegWeekRestPer 14 "Error indicator" 15 "Not Available" ;
VAL_ 2566867694 CwNumOfAssignReducWeekRestPer 14 "Error indicator" 15 "Not Available" ;
VAL_ 2566867694 CwNumOfAssignRegWeekRestPer 14 "Error indicator" 15 "Not Available" ;
VAL_ 2566892311 MsgCks_FFAB17 15 "Not Available, request honored" ;
VAL_ 2566892311 MsgCnt_FFAB17 8 "Reserved" 9 "Reserved" 10 "Reserved" 11 "Reserved" 12 "Reserved" 13 "Reserved" 14 "Reserved" 15 "Not Available, request honored" ;
VAL_ 2566892311 RevWarnEn 0 "Disabled" 1 "Enabled" 2 "Error" 3 "Not Available" ;
VAL_ 2566892311 MoisDrvFuncEn 0 "Off" 1 "On" 2 "Error" 3 "Not Available" ;
VAL_ 2566892311 BsisWarnEn 0 "Disabled" 1 "Enabled" 2 "Error" 3 "Not Available" ;
VAL_ 2566892311 MoisWarnEn 0 "Disabled" 1 "Enabled" 2 "Error" 3 "Not Available" ;
VAL_ 2566892446 MsgCks_FFAB9E 15 "Not Available, request honored" ;
VAL_ 2566892446 MsgCnt_FFAB9E 8 "Reserved" 9 "Reserved" 10 "Reserved" 11 "Reserved" 12 "Reserved" 13 "Reserved" 14 "Reserved" 15 "Not Available, request honored" ;
VAL_ 2566892446 BsisRightWarnLvl 0 "No warning" 1 "coll Lev 1" 2 "coll Lev 2" 3 "Close coll, warn ind dis. Lev 3" 4 "Close coll, warn ind en. Lev 3" 6 "Error" 7 "Not Available" ;
VAL_ 2566892446 BsisPlcaDetZone0 0 "Not Detected" 1 "coll Lev 1" 2 "coll Lev 2" 3 "Close coll, warn ind dis. Lev 2" 4 "Close coll, warn ind en. Lev 3" 6 "Error" 7 "Not Available" ;
VAL_ 2566892446 BsisPlcaDetZone1 0 "Not Detected" 1 "coll Lev 1" 2 "coll Lev 2" 3 "Close coll, warn ind dis. Lev 2" 4 "Close coll, warn ind en. Lev 3" 6 "Error" 7 "Not Available" ;
VAL_ 2566892446 BsisLeftWarnLvl 0 "No warning" 1 "coll Lev 1" 2 "coll Lev 2" 3 "Close coll, warn ind dis. Lev 3" 4 "Close coll, warn ind en. Lev 3" 6 "Error" 7 "Not Available" ;
VAL_ 2566892446 BsisDetObj 0 "Object Not Detected" 1 "Pedestrian" 2 "Cyclist" 3 "Pedestrian and Cyclist" 4 "Generic" 6 "Error" 7 "Not Available" ;
VAL_ 2566892446 BsisPlcaDetZone4 0 "Not Detected" 1 "coll Lev 1" 2 "coll Lev 2" 3 "Close coll, warn ind dis. Lev 2" 4 "Close coll, warn ind en. Lev 3" 6 "Error" 7 "Not Available" ;
VAL_ 2566892446 BsisPlcaDetZone3 0 "Not Detected" 1 "coll Lev 1" 2 "coll Lev 2" 3 "Close coll, warn ind dis. Lev 2" 4 "Close coll, warn ind en. Lev 3" 6 "Error" 7 "Not Available" ;
VAL_ 2566892446 BsisSts 0 "Manually disabled by driver" 1 "RTA- Warning enabled" 2 "RTA Warn man disabled by driver" 3 "NRTA Warning enabled" 4 "NRTA Warning disabled" 5 "Initiation" 6 "Error" 7 "Not Available" ;
VAL_ 2566892446 MoisWarnLvl 0 "No Warning" 1 "Only Information" 2 "Warning, warn  ind. dis" 3 "Warning, warn  ind. en" 6 "Error" 7 "Not Available" ;
VAL_ 2566892446 MoisDetObj 0 "Object Not Detected" 1 "Pedestrian" 2 "Cyclist" 3 "Pedestrian and Cyclist" 4 "Generic" 6 "Error" 7 "Not Available" ;
VAL_ 2566892446 MoisDetZone3 0 "Not Detected coll" 1 "Possible coll" 2 "Close coll, warn ind dis." 3 "Close coll, warn ind en." 6 "Error" 7 "Not available" ;
VAL_ 2566892446 MoisDetZone2 0 "Not Detected coll" 1 "Possible coll" 2 "Close coll, warn ind dis." 3 "Close coll, warn ind en." 6 "Error" 7 "Not available" ;
VAL_ 2566892446 MoisDetZone1 0 "Not Detected coll" 1 "Possible coll" 2 "Close coll, warn ind dis." 3 "Close coll, warn ind en." 6 "Error" 7 "Not available" ;
VAL_ 2566892446 MoisSts 0 "Manually disabled by driver" 1 "RTA- Warning enabled" 2 "RTA Warn man disabled by driver" 3 "NRTA Warning enabled" 4 "NRTA Warning disabled" 5 "Initiation" 6 "Error" 7 "Not Available" ;
VAL_ 2631855639 TripGrp1 0 "Take no action" 1 "Reset" 2 "Reserved" 3 "Not applicable" ;
VAL_ 2565537539 PgnRqst 37120 "VLSI1" 40448 "DM29" 41216 "DM33" 41728 "DM31" 41984 "DM30" 47360 "PLLT(PlanListLifetime)" 47872 "PLD(PlanListDistance)" 49408 "DM21" 49664 "DM20" 49920 "DM22" 53504 "MaintBcIc" 54016 "DM19" 60928 "ACL" 61184 "STOD" 64342 "HVESP3CFG" 64344 "HVESP2CFG" 64346 "HVESP1CFG" 64529 "TGFI" 64579 "TCSI" 64582 "TSIS" 64583 "MTI" 64605 "HVESSCFG" 64606 "HVESSHIST" 64653 "PII" 64701 "A1SCRSI2" 64782 "AT1OGC2" 64784 "AT1IGC2" 64839 "TML" 64879 "EEC8" 64896 "DM28" 64905 "VDS2" 64906 "J2012" 64912 "AETC" 64920 "AT1HI1" 64949 "DM23" 64950 "DM24" 64951 "DM25" 64952 "DM26" 64953 "TPRI" 64965 "ECUID" 64981 "EEC5" 65039 "LC" 65099 "TCFG2" 65109 "GFD" 65127 "CCC" 65131 "DI" 65136 "CVW" 65144 "TP1" 65145 "TP2" 65146 "TP3" 65195 "ETC6" 65196 "EBC4" 65199 "GFC" 65201 "EH" 65202 "GFI1" 65203 "LFI1" 65208 "GTFI" 65212 "CBI" 65214 "EEC4" 65216 "SERV" 65219 "ETC5" 65221 "ETC4" 65223 "ETC3" 65227 "DM02" 65228 "DM03" 65229 "DM04" 65230 "DM05" 65231 "DM06" 65234 "DM10" 65235 "DM11" 65236 "DM12" 65242 "SOFT" 65244 "IO" 65248 "VD" 65250 "TCFG" 65253 "HOURS" 65254 "TD" 65255 "VH" 65256 "VDS" 65257 "LFC1" 65258 "VW" 65259 "CI" 65260 "VI" 65261 "CCSS" 65284 "PB_DriversConsentOnPersonalData" 65376 "VehCfg" 65413 "PB_3CT" 65482 "PB_ID1" 65484 "PB_VNS" 65502 "Av2" 65520 "SCh" 65521 "DIS" 65524 "PB_IVA" ;
VAL_ 2565485386 PgnRqst_EA334A 37120 "VLSI1" 40448 "DM29" 41216 "DM33" 41728 "DM31" 41984 "DM30" 47360 "PLLT(PlanListLifetime)" 47872 "PLD(PlanListDistance)" 49408 "DM21" 49664 "DM20" 49920 "DM22" 53504 "MaintBcIc" 54016 "DM19" 60928 "ACL" 61184 "STOD" 64342 "HVESP3CFG" 64344 "HVESP2CFG" 64346 "HVESP1CFG" 64529 "TGFI" 64579 "TCSI" 64582 "TSIS" 64583 "MTI" 64605 "HVESSCFG" 64606 "HVESSHIST" 64653 "PII" 64701 "A1SCRSI2" 64782 "AT1OGC2" 64784 "AT1IGC2" 64839 "TML" 64879 "EEC8" 64896 "DM28" 64905 "VDS2" 64906 "J2012" 64912 "AETC" 64920 "AT1HI1" 64949 "DM23" 64950 "DM24" 64951 "DM25" 64952 "DM26" 64953 "TPRI" 64965 "ECUID" 64981 "EEC5" 65039 "LC" 65099 "TCFG2" 65109 "GFD" 65127 "CCC" 65131 "DI" 65136 "CVW" 65144 "TP1" 65145 "TP2" 65146 "TP3" 65195 "ETC6" 65196 "EBC4" 65199 "GFC" 65201 "EH" 65202 "GFI1" 65203 "LFI1" 65208 "GTFI" 65212 "CBI" 65214 "EEC4" 65216 "SERV" 65219 "ETC5" 65221 "ETC4" 65223 "ETC3" 65227 "DM02" 65228 "DM03" 65229 "DM04" 65230 "DM05" 65231 "DM06" 65234 "DM10" 65235 "DM11" 65236 "DM12" 65242 "SOFT" 65244 "IO" 65248 "VD" 65250 "TCFG" 65253 "HOURS" 65254 "TD" 65255 "VH" 65256 "VDS" 65257 "LFC1" 65258 "VW" 65259 "CI" 65260 "VI" 65261 "CCSS" 65284 "PB_DriversConsentOnPersonalData" 65376 "VehCfg" 65413 "PB_3CT" 65482 "PB_ID1" 65484 "PB_VNS" 65502 "Av2" 65520 "SCh" 65521 "DIS" 65524 "PB_IVA" ;
VAL_ 2565533258 PgnRqst_EAEE4A 37120 "VLSI1" 40448 "DM29" 41216 "DM33" 41728 "DM31" 41984 "DM30" 47360 "PLLT(PlanListLifetime)" 47872 "PLD(PlanListDistance)" 49408 "DM21" 49664 "DM20" 49920 "DM22" 53504 "MaintBcIc" 54016 "DM19" 60928 "ACL" 61184 "STOD" 64342 "HVESP3CFG" 64344 "HVESP2CFG" 64346 "HVESP1CFG" 64529 "TGFI" 64579 "TCSI" 64582 "TSIS" 64583 "MTI" 64605 "HVESSCFG" 64606 "HVESSHIST" 64653 "PII" 64701 "A1SCRSI2" 64782 "AT1OGC2" 64784 "AT1IGC2" 64839 "TML" 64879 "EEC8" 64896 "DM28" 64905 "VDS2" 64906 "J2012" 64912 "AETC" 64920 "AT1HI1" 64949 "DM23" 64950 "DM24" 64951 "DM25" 64952 "DM26" 64953 "TPRI" 64965 "ECUID" 64981 "EEC5" 65039 "LC" 65099 "TCFG2" 65109 "GFD" 65127 "CCC" 65131 "DI" 65136 "CVW" 65144 "TP1" 65145 "TP2" 65146 "TP3" 65195 "ETC6" 65196 "EBC4" 65199 "GFC" 65201 "EH" 65202 "GFI1" 65203 "LFI1" 65208 "GTFI" 65212 "CBI" 65214 "EEC4" 65216 "SERV" 65219 "ETC5" 65221 "ETC4" 65223 "ETC3" 65227 "DM02" 65228 "DM03" 65229 "DM04" 65230 "DM05" 65231 "DM06" 65234 "DM10" 65235 "DM11" 65236 "DM12" 65242 "SOFT" 65244 "IO" 65248 "VD" 65250 "TCFG" 65253 "HOURS" 65254 "TD" 65255 "VH" 65256 "VDS" 65257 "LFC1" 65258 "VW" 65259 "CI" 65260 "VI" 65261 "CCSS" 65284 "PB_DriversConsentOnPersonalData" 65376 "VehCfg" 65413 "PB_3CT" 65482 "PB_ID1" 65484 "PB_VNS" 65502 "Av2" 65520 "SCh" 65521 "DIS" 65524 "PB_IVA" ;
VAL_ 2566852224 ContactInconsitency 0 "no error" 1 "Bit 1 for Contactor Q1" 2 "Bit 2 for Contactor Q2" 4 "Bit 3 for Contactor Q4" 8 "Bit 4 for Contactor Q5" 48 "error" 63 "not available" ;
VAL_ 2566852224 MajorIsolFault 0 "No Fault" 1 "Fault" 2 "error" 3 "not available" ;
VAL_ 2566852224 MinorIsolFault 0 "No Fault" 1 "Fault" 2 "error" 3 "not available" ;
VAL_ 2566852224 ChgSts 0 "No charging" 1 "Charging" 2 "error" 3 "not available" ;
VAL_ 2566838813 SwIdField3 48 "0" 49 "1" 50 "2" 51 "3" 52 "4" 53 "5" 54 "6" 55 "7" 56 "8" 57 "9" 65 "A" 66 "B" 67 "C" 68 "D" 69 "E" 70 "F" 71 "G" 72 "H" 73 "I" 74 "J" 75 "K" 76 "L" 77 "M" 78 "N" 79 "O" 80 "P" 81 "Q" 82 "R" 83 "S" 84 "T" 85 "U" 86 "V" 87 "W" 88 "X" 89 "Y" 90 "Z" ;
VAL_ 2566838813 SwIdField2 48 "0" 49 "1" 50 "2" 51 "3" 52 "4" 53 "5" 54 "6" 55 "7" 56 "8" 57 "9" 65 "A" 66 "B" 67 "C" 68 "D" 69 "E" 70 "F" 71 "G" 72 "H" 73 "I" 74 "J" 75 "K" 76 "L" 77 "M" 78 "N" 79 "O" 80 "P" 81 "Q" 82 "R" 83 "S" 84 "T" 85 "U" 86 "V" 87 "W" 88 "X" 89 "Y" 90 "Z" ;
VAL_ 2566838813 SwIdField1 48 "0" 49 "1" 50 "2" 51 "3" 52 "4" 53 "5" 54 "6" 55 "7" 56 "8" 57 "9" 65 "A" 66 "B" 67 "C" 68 "D" 69 "E" 70 "F" 71 "G" 72 "H" 73 "I" 74 "J" 75 "K" 76 "L" 77 "M" 78 "N" 79 "O" 80 "P" 81 "Q" 82 "R" 83 "S" 84 "T" 85 "U" 86 "V" 87 "W" 88 "X" 89 "Y" 90 "Z" ;
VAL_ 2566869235 Bms10BatSoh 0 "39%" 61 "100%" 62 "Error(OnSOH_Measurment)" 63 "Not Available" ;
VAL_ 2566869235 Bms09BatSoh 0 "39%" 61 "100%" 62 "Error(OnSOH_Measurment)" 63 "Not Available" ;
VAL_ 2566869235 Bms08BatSoh 0 "39%" 61 "100%" 62 "Error(OnSOH_Measurment)" 63 "Not Available" ;
VAL_ 2566869235 Bms07BatSoh 0 "39%" 61 "100%" 62 "Error(OnSOH_Measurment)" 63 "Not Available" ;
VAL_ 2566869235 Bms06BatSoh 0 "39%" 61 "100%" 62 "Error(OnSOH_Measurment)" 63 "Not Available" ;
VAL_ 2566869235 Bms05BatSoh 0 "39%" 61 "100%" 62 "Error(OnSOH_Measurment)" 63 "Not Available" ;
VAL_ 2566869235 Bms04BatSoh 0 "39%" 61 "100%" 62 "Error(OnSOH_Measurment)" 63 "Not Available" ;
VAL_ 2566869235 Bms03BatSoh 0 "39%" 61 "100%" 62 "Error(OnSOH_Measurment)" 63 "Not Available" ;
VAL_ 2566869235 Bms02BatSoh 0 "39%" 61 "100%" 62 "Error(OnSOH_Measurment)" 63 "Not Available" ;
VAL_ 2566869235 Bms01BatSoh 0 "39%" 61 "100%" 62 "Error(OnSOH_Measurment)" 63 "Not Available" ;
VAL_ 2566869491 Bms20BatSoh 0 "39%" 61 "100%" 62 "Error(OnSOH_Measurment)" 63 "Not Available" ;
VAL_ 2566869491 Bms19BatSoh 0 "39%" 61 "100%" 62 "Error(OnSOH_Measurment)" 63 "Not Available" ;
VAL_ 2566869491 Bms18BatSoh 0 "39%" 61 "100%" 62 "Error(OnSOH_Measurment)" 63 "Not Available" ;
VAL_ 2566869491 Bms17BatSoh 0 "39%" 61 "100%" 62 "Error(OnSOH_Measurment)" 63 "Not Available" ;
VAL_ 2566869491 Bms16BatSoh 0 "39%" 61 "100%" 62 "Error(OnSOH_Measurment)" 63 "Not Available" ;
VAL_ 2566869491 Bms15BatSoh 0 "39%" 61 "100%" 62 "Error(OnSOH_Measurment)" 63 "Not Available" ;
VAL_ 2566869491 Bms14BatSoh 0 "39%" 61 "100%" 62 "Error(OnSOH_Measurment)" 63 "Not Available" ;
VAL_ 2566869491 Bms13BatSoh 0 "39%" 61 "100%" 62 "Error(OnSOH_Measurment)" 63 "Not Available" ;
VAL_ 2566869491 Bms12BatSoh 0 "39%" 61 "100%" 62 "Error(OnSOH_Measurment)" 63 "Not Available" ;
VAL_ 2566869491 Bms11BatSoh 0 "39%" 61 "100%" 62 "Error(OnSOH_Measurment)" 63 "Not Available" ;
VAL_ 2348884337 WindshWiperOff 0 "Off" 1 "On" 2 "Error" 3 "Not Available" ;
VAL_ 2348884337 EngBrkIntLevPos5 0 "Off" 1 "On" 2 "Error" 3 "Not Available" ;
VAL_ 2348884337 EngBrkIntLevPos6 0 "Off" 1 "On" 2 "Error" 3 "Not Available" ;
VAL_ 2348884337 EngBrkIntLevPos1 0 "Off" 1 "On" 2 "Error" 3 "Not Available" ;
VAL_ 2348884337 EngBrkIntLevPos2 0 "Off" 1 "On" 2 "Error" 3 "Not Available" ;
VAL_ 2348884337 EngBrkIntLevPos3 0 "Off" 1 "On" 2 "Error" 3 "Not Available" ;
VAL_ 2348884337 EngBrkIntLevPos4 0 "Off" 1 "On" 2 "Error" 3 "Not Available" ;
VAL_ 2348884337 EngBrkIntLevPosOff 0 "Off" 1 "On" 2 "Error" 3 "Not Available" ;
VAL_ 2365484270 TcoVehSpeed 65024 "Error" 65535 "Not_Available" ;
VAL_ 2365484270 DirInd 0 "Forward" 1 "Reverse" 2 "Error" 3 "Not Available" ;
VAL_ 2365484270 TcoPerf 0 "Normal performance" 1 "Performance analysis" 2 "Error" 3 "Not Available" ;
VAL_ 2365484270 HandInfo 0 "No handling information" 1 "Handling information" 2 "Error" 3 "Not Available" ;
VAL_ 2365484270 SysEvt 0 "No tachograph event" 1 "Tachograph event" 2 "Error" 3 "Not Available" ;
VAL_ 2365484270 DrivCardDriv2 0 "Driver card not present" 1 "Driver card present" 2 "Error" 3 "Not Available" ;
VAL_ 2365484270 Driv2TimeRelSts 0 "Normal, No limits reached" 1 "Limit 1, 15 min before 4 ½h" 2 "Limit 2, 4 ½h reached" 3 "Limit 3, 15min before 9h" 4 "Limit 4, 9h reached" 5 "Limit 5, 15min before 16h" 6 "Limit 6, 16h reached" 13 "Other" 14 "Error" 15 "Not Available" ;
VAL_ 2365484270 VehOverspeed 0 "No overspeed" 1 "Overspeed" 2 "Error" 3 "Not Available" ;
VAL_ 2365484270 DrivCardDriv1 0 "Driver card not present" 1 "Driver card present" 2 "Error" 3 "Not Available" ;
VAL_ 2365484270 Driv1TimeRelSts 0 "Normal, No limits reached" 1 "Limit 1, 15 min before 4 ½h" 2 "Limit 2, 4 ½h reached" 3 "Limit 3, 15min before 9h" 4 "Limit 4, 9h reached" 5 "Limit 5, 15min before 16h" 6 "Limit 6, 16h reached" 13 "Other" 14 "Error" 15 "Not Available" ;
VAL_ 2365484270 VehMot 0 "Vehicle motion not detected" 1 "Vehicle motion detected" 2 "Error" 3 "Not Available" ;
VAL_ 2365484270 Driv2WorkSts 0 "Rest, sleeping" 1 "Driver available, short break" 2 "Work" 3 "Drive, Behind wheel" 4 "Reserved" 5 "Reserved" 6 "Error" 7 "Not Available" ;
VAL_ 2365484270 Driv1WorkSts 0 "Rest, sleeping" 1 "Driver available, short break" 2 "Work" 3 "Drive, Behind wheel" 4 "Reserved" 5 "Reserved" 6 "Error" 7 "Not Available" ;
VAL_ 2566842094 Yr 255 "Not Available" ;
VAL_ 2566842094 Day 255 "Not Available" ;
VAL_ 2566842094 Month 255 "Not Available" ;
VAL_ 2566842094 Hr 255 "Not Available" ;
VAL_ 2566842094 Min 255 "Not Available" ;
VAL_ 2566842094 Sec 255 "Not Available" ;
VAL_ 2566854213 ApuRedWarn 0 "OFF" 1 "ON" ;
VAL_ 2566854213 MildhybridStop_StartDeact 0 "OFF" 1 "ON" ;
VAL_ 2566854213 ApuOrangeWarn_ElectrovalvesApuDe 0 "OFF" 1 "ON" ;
VAL_ 2566854213 OilLevPwrSteerPumpDef 0 "OFF" 1 "ON" ;
VAL_ 2566854213 OilSepFault 0 "OFF" 1 "ON" ;
VAL_ 2566854213 GasFailElectrovalveN10 0 "OFF" 1 "ON" ;
VAL_ 2566854213 GasFailElectrovalveN9 0 "OFF" 1 "ON" ;
VAL_ 2566854213 GasFailElectrovalveN8 0 "OFF" 1 "ON" ;
VAL_ 2566854213 GasFailElectrovalveN7 0 "OFF" 1 "ON" ;
VAL_ 2566854213 GasFailElectrovalveN6 0 "OFF" 1 "ON" ;
VAL_ 2566854213 GasFailElectrovalveN5 0 "OFF" 1 "ON" ;
VAL_ 2566854213 GasFailElectrovalveN4 0 "OFF" 1 "ON" ;
VAL_ 2566854213 GasFailElectrovalveN3 0 "OFF" 1 "ON" ;
VAL_ 2566854213 GasFailElectrovalveN2 0 "OFF" 1 "ON" ;
VAL_ 2566854213 GasFailElectrovalveN1 0 "OFF" 1 "ON" ;
VAL_ 2566854213 ElectrovalveGasFail 0 "OFF" 1 "ON" ;
VAL_ 2566854213 GasTempSensFail 0 "OFF" 1 "ON" ;
VAL_ 2566854213 GasRefuelingGateOpen 0 "OFF" 1 "ON" ;
VAL_ 2566854213 GasTempTooHigh 0 "OFF" 1 "ON" ;
VAL_ 2566854213 AutoOilDef 0 "OFF" 1 "ON" ;
VAL_ 2566854213 DefPompeDosMod 0 "OFF" 1 "ON" ;
VAL_ 2566854213 AcComprSts 0 "OFF" 1 "ON" ;
VAL_ 2566854213 AcFault 0 "OFF" 1 "ON" ;
VAL_ 2566854213 AcOn 0 "OFF" 1 "ON" ;
VAL_ 2566854213 DrivAcFault 0 "OFF" 1 "ON" ;
VAL_ 2566854213 DrivAcOn 0 "OFF" 1 "ON" ;
VAL_ 2566854213 FuelFiltClogDef 0 "OFF" 1 "ON" ;
VAL_ 2566854213 EngOilLowLev 0 "OFF" 1 "ON" ;
VAL_ 2566854213 EngAirFiltClogDef 0 "OFF" 1 "ON" ;
VAL_ 2566854213 LowLevEngCoolRefr 0 "OFF" 1 "ON" ;
VAL_ 2566854213 VehSpeedSigDef 0 "OFF" 1 "ON" ;
VAL_ 2566854213 CaidLeadenBtnSts 0 "OFF" 1 "ON" ;
VAL_ 2566854213 DrlLightDef 0 "OFF" 1 "ON" ;
VAL_ 2566854213 PavillonRightTurnLightDef 0 "OFF" 1 "ON" ;
VAL_ 2566854213 PavillonLeftTurnLightDef 0 "OFF" 1 "ON" ;
VAL_ 2566854213 LatRightTurnLightDef 0 "OFF" 1 "ON" ;
VAL_ 2566854213 LatLeftTurnLightDef 0 "OFF" 1 "ON" ;
VAL_ 2566854213 RearRightTurnLightDef 0 "OFF" 1 "ON" ;
VAL_ 2566854213 RearLeftTurnLightDef 0 "OFF" 1 "ON" ;
VAL_ 2566854213 RearFogLightDef 0 "OFF" 1 "ON" ;
VAL_ 2566854213 FaRFogLightDef 0 "OFF" 1 "ON" ;
VAL_ 2566854213 FaLFogLightDef 0 "OFF" 1 "ON" ;
VAL_ 2566854213 RearPosLightDef 0 "OFF" 1 "ON" ;
VAL_ 2566854213 RearPavillonPosLightDef 0 "OFF" 1 "ON" ;
VAL_ 2566854213 FrontRightTurnLightDef 0 "OFF" 1 "ON" ;
VAL_ 2566854213 FrontLeftTurnLightDef 0 "OFF" 1 "ON" ;
VAL_ 2566854213 RightLowBeamLightDef 0 "OFF" 1 "ON" ;
VAL_ 2566854213 LeftLowBeamLightDef 0 "OFF" 1 "ON" ;
VAL_ 2566854213 RightHighBeamLightDef 0 "OFF" 1 "ON" ;
VAL_ 2566854213 LeftHighBeamLightDef 0 "OFF" 1 "ON" ;
VAL_ 2566854213 RevLightDef 0 "OFF" 1 "ON" ;
VAL_ 2566854213 StopLightDef 0 "OFF" 1 "ON" ;
VAL_ 2566854213 FireOngoing 0 "OFF" 1 "ON" ;
VAL_ 2566854213 Overheating_RiskOfFire 0 "OFF" 1 "ON" ;
VAL_ 2566854213 FireExtinctionFaulty 0 "OFF" 1 "ON" ;
VAL_ 2566854213 AirPrsMidBrkCircDef 0 "OFF" 1 "ON" ;
VAL_ 2566854213 AirPrsServitudeCircDef 0 "OFF" 1 "ON" ;
VAL_ 2566854213 AirPrsParkBrkCircDef 0 "OFF" 1 "ON" ;
VAL_ 2566854213 AirPrsFrontBrkCircDef 0 "OFF" 1 "ON" ;
VAL_ 2566854213 AirPrsRearBrkCircDef 0 "OFF" 1 "ON" ;
VAL_ 2566854213 Ramp_Whchair_LiftFail 0 "OFF" 1 "ON" ;
VAL_ 2566854213 FailOnRampSensitiveEdge_Step 0 "OFF" 1 "ON" ;
VAL_ 2566854213 DoorsSecurModeDeactivated 0 "OFF" 1 "ON" ;
VAL_ 2566858309 HeatOnFullElec 0 "OFF" 1 "ON" ;
VAL_ 2566858309 CanPwr3FaultFullElec 0 "OFF" 1 "ON" ;
VAL_ 2566858309 LowPwrSupplyLevFullElec 0 "OFF" 1 "ON" ;
VAL_ 2566858309 ChgIncident_InServOpportunityChg 0 "OFF" 1 "ON" ;
VAL_ 2566858309 ChgIncident_OvernightModeFullEle 0 "OFF" 1 "ON" ;
VAL_ 2566858309 VehStsOnDrivMode 1 "Recovery_ChargeState" 2 "ECO" 3 "POWER" ;
